VERSION ""

NS_ :

BS_:

BU_: EMS FR_CMR TCU vBDM AFS ILCU_LH ILCU_RH VCU BMS CLU EPB ESC H_U_MM IBU IBU_HS LDC MCU MDPS OBC RR_C_RDR SVM DATC ADAS_DRV ADAS_PRK AWD RWS AMP APSU DAU DVRS Dummy FCS HUD IAU ICSC ICU MLM PFSU PTGM SBW ACU ADM ECS TPMS HCU OPU PSB eCall AHLS ODS VESS AHV DHV DLBCU DPSS DPSU PSM RLHV RRHV SHVU_FR SHVU_RR DIBOX SAS FPCM SCM AFCU_DRV ESC_C CGW SCU WPC MFSW SWRC ESU AFCU_AST AFCU_RL AFCU_RR APSM ARS BCM BCW CCM DSS ECW FCU FICU GST HFKS HSWS LPI OPI PSD PSU RDC RLPSM RRPSM RWPC SLB SMK YRS SML CTM FR_C_RDR_LH FR_C_RDR_RH RR_C_RDR_LH CLU_MM HUD_MM LSD MKBD MM_CGW SBW_FF eCall_MM H_U_ETH FR_RDR

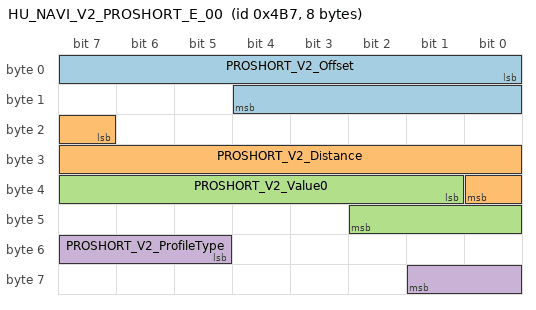
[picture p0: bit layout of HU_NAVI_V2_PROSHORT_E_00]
BO_ 1207 HU_NAVI_V2_PROSHORT_E_00: 8 H_U_ETH
 SG_ PROSHORT_V2_Offset : 0|13@1+ (1,0) [0|0] "m"  FR_CMR
 SG_ PROSHORT_V2_Distance : 23|10@1+ (1,0) [0|0] "m"  FR_CMR
 SG_ PROSHORT_V2_Value0 : 33|10@1+ (1,0) [0|0] ""  FR_CMR
 SG_ PROSHORT_V2_ProfileType : 53|5@1+ (1,0) [0|0] ""  FR_CMR

CM_ BO_ 1207 "[EC] Periodic and On Event";
CM_ SG_ 1207 PROSHORT_V2_Offset "Information for Offset of position of the first profile spot from currnet position
-This Offset should be calculated using below Factors(according to Profile Type)
-Profile Type 1(Curvature): 1m
-Profile Type 4(Slope): 1m(PROSHORT_Accuracy=0x0), 3m(PROSHORT_Accuracy=0x2)
-Profile Type 16(Safety Driving Section): 1m(Section0,1,2,3,5)
-Refer to Specification(ES96523-31) for details";
CM_ SG_ 1207 PROSHORT_V2_Distance "Information for Distance from first profile spot to the second one
-This distance should be calculated using below Factors(according to Profile Type)
-Profile Type 1(Curvature): 2
-Profile Type 4(Slope): 2(PROSHORT_Accuracy=0x0), 20(PROSHORT_Accuracy=0x2)
-Profile Type 16(Safety Driving Section): 20(Section0,1), 2(Section2,3), 5(Section5)";
CM_ SG_ 1207 PROSHORT_V2_Value0 "Information for Profile Short value at Offset";
CM_ SG_ 1207 PROSHORT_V2_ProfileType "Information for Profile Short Type: Slope(Linear) is used for Slope
-In case of Section Speed, transmitt Average Value of Speed Limit of Links in Section.
-Link without Speed Limit is excluded for Average Speed Calculation
-Unlimited Lane in Europe reflects 140kph for Average Speed Calculation";
BA_DEF_ BO_  "GenMsgILSupport" ENUM  "No","Yes";
BA_DEF_ BO_  "DiagState" ENUM  "No","Yes";
BA_DEF_ BO_  "DiagResponse" ENUM  "No","Yes";
BA_DEF_ BO_  "DiagRequest" ENUM  "No","Yes";
BA_DEF_ BO_  "VFrameFormat" ENUM  "StandardCAN","ExtendedCAN","reserved","reserved","reserved","reserved","reserved","reserved","reserved","reserved","reserved","reserved","reserved","reserved","StandardCAN_FD","ExtendedCAN_FD";
BA_DEF_ BO_  "GenMsgSendType" ENUM  "Cyclic","NoMsgSendType";
BA_DEF_ SG_  "UserSigValidity" ENUM  "B+","ACC","IG","IG1","IG2","IG3","IG1 or IG2","IG1 or IG3","Undef";
BA_DEF_ SG_  "RoutingFactor" INT 1 1215752192;
BA_DEF_ SG_  "NetworkRequestHoldingTime" INT 0 65535;
BA_DEF_ SG_  "Description" STRING ;
BA_DEF_ SG_  "Version" STRING ;
BA_DEF_ BO_  "GenMsgCycleTime" INT 0 2000;
BA_DEF_ BO_  "GenMsgStartDelayTime" INT 0 2000;
BA_DEF_ SG_  "UsrSigPurpose" ENUM  "Undef","FN","DIAG","DEV","NM";
BA_DEF_ SG_  "GenSigStartValue" INT 0 0;
BA_DEF_DEF_  "GenMsgILSupport" "Yes";
BA_DEF_DEF_  "DiagState" "No";
BA_DEF_DEF_  "DiagResponse" "No";
BA_DEF_DEF_  "DiagRequest" "No";
BA_DEF_DEF_  "VFrameFormat" "";
BA_DEF_DEF_  "GenMsgSendType" "NoMsgSendType";
BA_DEF_DEF_  "UserSigValidity" "IG";
BA_DEF_DEF_  "RoutingFactor" 1;
BA_DEF_DEF_  "NetworkRequestHoldingTime" 0;
BA_DEF_DEF_  "Description" "";
BA_DEF_DEF_  "Version" "";
BA_DEF_DEF_  "GenMsgCycleTime" 0;
BA_DEF_DEF_  "GenMsgStartDelayTime" 0;
BA_DEF_DEF_  "UsrSigPurpose" "FN";
BA_DEF_DEF_  "GenSigStartValue" 0;
BA_ "GenMsgSendType" BO_ 1207 0;
BA_ "VFrameFormat" BO_ 1207 14;
BA_ "UserSigValidity" SG_ 1207 PROSHORT_V2_Offset 3;
BA_ "GenSigStartValue" SG_ 1207 PROSHORT_V2_Offset 8191;
BA_ "Description" SG_ 1207 PROSHORT_V2_Offset "[Default Value]

0x1FFF";
BA_ "Version" SG_ 1207 PROSHORT_V2_Offset "18.01.07";
BA_ "UserSigValidity" SG_ 1207 PROSHORT_V2_Distance 3;
BA_ "GenSigStartValue" SG_ 1207 PROSHORT_V2_Distance 1023;
BA_ "Description" SG_ 1207 PROSHORT_V2_Distance "[Default Value]

0x3FF";
BA_ "Version" SG_ 1207 PROSHORT_V2_Distance "18.01.04";
BA_ "UserSigValidity" SG_ 1207 PROSHORT_V2_Value0 3;
BA_ "GenSigStartValue" SG_ 1207 PROSHORT_V2_Value0 1023;
BA_ "Description" SG_ 1207 PROSHORT_V2_Value0 "[Default Value]

0x3FF";
BA_ "Version" SG_ 1207 PROSHORT_V2_Value0 "18.01.04";
BA_ "UserSigValidity" SG_ 1207 PROSHORT_V2_ProfileType 3;
BA_ "Description" SG_ 1207 PROSHORT_V2_ProfileType "[Default Value]

0x0";
BA_ "Version" SG_ 1207 PROSHORT_V2_ProfileType "18.01.04";
VAL_ 1207 PROSHORT_V2_Offset 0 "Distance" 1 "Distance" 2 "Distance" 3 "Distance" 4 "Distance" 5 "Distance" 6 "Distance" 7 "Distance" 8 "Distance" 9 "Distance" 10 "Distance" 11 "Distance" 12 "Distance" 13 "Distance" 14 "Distance" 15 "Distance" 16 "Distance" 17 "Distance" 18 "Distance" 19 "Distance" 20 "Distance" 21 "Distance" 22 "Distance" 23 "Distance" 24 "Distance" 25 "Distance" 26 "Distance" 27 "Distance" 28 "Distance" 29 "Distance" 30 "Distance" 31 "Distance" 32 "Distance" 33 "Distance" 34 "Distance" 35 "Distance" 36 "Distance" 37 "Distance" 38 "Distance" 39 "Distance" 40 "Distance" 41 "Distance" 42 "Distance" 43 "Distance" 44 "Distance" 45 "Distance" 46 "Distance" 47 "Distance" 48 "Distance" 49 "Distance" 50 "Distance" 51 "Distance" 52 "Distance" 53 "Distance" 54 "Distance" 55 "Distance" 56 "Distance" 57 "Distance" 58 "Distance" 59 "Distance" 60 "Distance" 61 "Distance" 62 "Distance" 63 "Distance" 64 "Distance" 65 "Distance" 66 "Distance" 67 "Distance" 68 "Distance" 69 "Distance" 70 "Distance" 71 "Distance" 72 "Distance" 73 "Distance" 74 "Distance" 75 "Distance" 76 "Distance" 77 "Distance" 78 "Distance" 79 "Distance" 80 "Distance" 81 "Distance" 82 "Distance" 83 "Distance" 84 "Distance" 85 "Distance" 86 "Distance" 87 "Distance" 88 "Distance" 89 "Distance" 90 "Distance" 91 "Distance" 92 "Distance" 93 "Distance" 94 "Distance" 95 "Distance" 96 "Distance" 97 "Distance" 98 "Distance" 99 "Distance" 100 "Distance" 101 "Distance" 102 "Distance" 103 "Distance" 104 "Distance" 105 "Distance" 106 "Distance" 107 "Distance" 108 "Distance" 109 "Distance" 110 "Distance" 111 "Distance" 112 "Distance" 113 "Distance" 114 "Distance" 115 "Distance" 116 "Distance" 117 "Distance" 118 "Distance" 119 "Distance" 120 "Distance" 121 "Distance" 122 "Distance" 123 "Distance" 124 "Distance" 125 "Distance" 126 "Distance" 127 "Distance" 128 "Distance" 129 "Distance" 130 "Distance" 131 "Distance" 132 "Distance" 133 "Distance" 134 "Distance" 135 "Distance" 136 "Distance" 137 "Distance" 138 "Distance" 139 "Distance" 140 "Distance" 141 "Distance" 142 "Distance" 143 "Distance" 144 "Distance" 145 "Distance" 146 "Distance" 147 "Distance" 148 "Distance" 149 "Distance" 150 "Distance" 151 "Distance" 152 "Distance" 153 "Distance" 154 "Distance" 155 "Distance" 156 "Distance" 157 "Distance" 158 "Distance" 159 "Distance" 160 "Distance" 161 "Distance" 162 "Distance" 163 "Distance" 164 "Distance" 165 "Distance" 166 "Distance" 167 "Distance" 168 "Distance" 169 "Distance" 170 "Distance" 171 "Distance" 172 "Distance" 173 "Distance" 174 "Distance" 175 "Distance" 176 "Distance" 177 "Distance" 178 "Distance" 179 "Distance" 180 "Distance" 181 "Distance" 182 "Distance" 183 "Distance" 184 "Distance" 185 "Distance" 186 "Distance" 187 "Distance" 188 "Distance" 189 "Distance" 190 "Distance" 191 "Distance" 192 "Distance" 193 "Distance" 194 "Distance" 195 "Distance" 196 "Distance" 197 "Distance" 198 "Distance" 199 "Distance" 200 "Distance" 201 "Distance" 202 "Distance" 203 "Distance" 204 "Distance" 205 "Distance" 206 "Distance" 207 "Distance" 208 "Distance" 209 "Distance" 210 "Distance" 211 "Distance" 212 "Distance" 213 "Distance" 214 "Distance" 215 "Distance" 216 "Distance" 217 "Distance" 218 "Distance" 219 "Distance" 220 "Distance" 221 "Distance" 222 "Distance" 223 "Distance" 224 "Distance" 225 "Distance" 226 "Distance" 227 "Distance" 228 "Distance" 229 "Distance" 230 "Distance" 231 "Distance" 232 "Distance" 233 "Distance" 234 "Distance" 235 "Distance" 236 "Distance" 237 "Distance" 238 "Distance" 239 "Distance" 240 "Distance" 241 "Distance" 242 "Distance" 243 "Distance" 244 "Distance" 245 "Distance" 246 "Distance" 247 "Distance" 248 "Distance" 249 "Distance" 250 "Distance" 251 "Distance" 252 "Distance" 253 "Distance" 254 "Distance" 255 "Distance" 256 "Distance" 257 "Distance" 258 "Distance" 259 "Distance" 260 "Distance" 261 "Distance" 262 "Distance" 263 "Distance" 264 "Distance" 265 "Distance" 266 "Distance" 267 "Distance" 268 "Distance" 269 "Distance" 270 "Distance" 271 "Distance" 272 "Distance" 273 "Distance" 274 "Distance" 275 "Distance" 276 "Distance" 277 "Distance" 278 "Distance" 279 "Distance" 280 "Distance" 281 "Distance" 282 "Distance" 283 "Distance" 284 "Distance" 285 "Distance" 286 "Distance" 287 "Distance" 288 "Distance" 289 "Distance" 290 "Distance" 291 "Distance" 292 "Distance" 293 "Distance" 294 "Distance" 295 "Distance" 296 "Distance" 297 "Distance" 298 "Distance" 299 "Distance" 300 "Distance" 301 "Distance" 302 "Distance" 303 "Distance" 304 "Distance" 305 "Distance" 306 "Distance" 307 "Distance" 308 "Distance" 309 "Distance" 310 "Distance" 311 "Distance" 312 "Distance" 313 "Distance" 314 "Distance" 315 "Distance" 316 "Distance" 317 "Distance" 318 "Distance" 319 "Distance" 320 "Distance" 321 "Distance" 322 "Distance" 323 "Distance" 324 "Distance" 325 "Distance" 326 "Distance" 327 "Distance" 328 "Distance" 329 "Distance" 330 "Distance" 331 "Distance" 332 "Distance" 333 "Distance" 334 "Distance" 335 "Distance" 336 "Distance" 337 "Distance" 338 "Distance" 339 "Distance" 340 "Distance" 341 "Distance" 342 "Distance" 343 "Distance" 344 "Distance" 345 "Distance" 346 "Distance" 347 "Distance" 348 "Distance" 349 "Distance" 350 "Distance" 351 "Distance" 352 "Distance" 353 "Distance" 354 "Distance" 355 "Distance" 356 "Distance" 357 "Distance" 358 "Distance" 359 "Distance" 360 "Distance" 361 "Distance" 362 "Distance" 363 "Distance" 364 "Distance" 365 "Distance" 366 "Distance" 367 "Distance" 368 "Distance" 369 "Distance" 370 "Distance" 371 "Distance" 372 "Distance" 373 "Distance" 374 "Distance" 375 "Distance" 376 "Distance" 377 "Distance" 378 "Distance" 379 "Distance" 380 "Distance" 381 "Distance" 382 "Distance" 383 "Distance" 384 "Distance" 385 "Distance" 386 "Distance" 387 "Distance" 388 "Distance" 389 "Distance" 390 "Distance" 391 "Distance" 392 "Distance" 393 "Distance" 394 "Distance" 395 "Distance" 396 "Distance" 397 "Distance" 398 "Distance" 399 "Distance" 400 "Distance" 401 "Distance" 402 "Distance" 403 "Distance" 404 "Distance" 405 "Distance" 406 "Distance" 407 "Distance" 408 "Distance" 409 "Distance" 410 "Distance" 411 "Distance" 412 "Distance" 413 "Distance" 414 "Distance" 415 "Distance" 416 "Distance" 417 "Distance" 418 "Distance" 419 "Distance" 420 "Distance" 421 "Distance" 422 "Distance" 423 "Distance" 424 "Distance" 425 "Distance" 426 "Distance" 427 "Distance" 428 "Distance" 429 "Distance" 430 "Distance" 431 "Distance" 432 "Distance" 433 "Distance" 434 "Distance" 435 "Distance" 436 "Distance" 437 "Distance" 438 "Distance" 439 "Distance" 440 "Distance" 441 "Distance" 442 "Distance" 443 "Distance" 444 "Distance" 445 "Distance" 446 "Distance" 447 "Distance" 448 "Distance" 449 "Distance" 450 "Distance" 451 "Distance" 452 "Distance" 453 "Distance" 454 "Distance" 455 "Distance" 456 "Distance" 457 "Distance" 458 "Distance" 459 "Distance" 460 "Distance" 461 "Distance" 462 "Distance" 463 "Distance" 464 "Distance" 465 "Distance" 466 "Distance" 467 "Distance" 468 "Distance" 469 "Distance" 470 "Distance" 471 "Distance" 472 "Distance" 473 "Distance" 474 "Distance" 475 "Distance" 476 "Distance" 477 "Distance" 478 "Distance" 479 "Distance" 480 "Distance" 481 "Distance" 482 "Distance" 483 "Distance" 484 "Distance" 485 "Distance" 486 "Distance" 487 "Distance" 488 "Distance" 489 "Distance" 490 "Distance" 491 "Distance" 492 "Distance" 493 "Distance" 494 "Distance" 495 "Distance" 496 "Distance" 497 "Distance" 498 "Distance" 499 "Distance" 500 "Distance" 501 "Distance" 502 "Distance" 503 "Distance" 504 "Distance" 505 "Distance" 506 "Distance" 507 "Distance" 508 "Distance" 509 "Distance" 510 "Distance" 511 "Distance" 512 "Distance" 513 "Distance" 514 "Distance" 515 "Distance" 516 "Distance" 517 "Distance" 518 "Distance" 519 "Distance" 520 "Distance" 521 "Distance" 522 "Distance" 523 "Distance" 524 "Distance" 525 "Distance" 526 "Distance" 527 "Distance" 528 "Distance" 529 "Distance" 530 "Distance" 531 "Distance" 532 "Distance" 533 "Distance" 534 "Distance" 535 "Distance" 536 "Distance" 537 "Distance" 538 "Distance" 539 "Distance" 540 "Distance" 541 "Distance" 542 "Distance" 543 "Distance" 544 "Distance" 545 "Distance" 546 "Distance" 547 "Distance" 548 "Distance" 549 "Distance" 550 "Distance" 551 "Distance" 552 "Distance" 553 "Distance" 554 "Distance" 555 "Distance" 556 "Distance" 557 "Distance" 558 "Distance" 559 "Distance" 560 "Distance" 561 "Distance" 562 "Distance" 563 "Distance" 564 "Distance" 565 "Distance" 566 "Distance" 567 "Distance" 568 "Distance" 569 "Distance" 570 "Distance" 571 "Distance" 572 "Distance" 573 "Distance" 574 "Distance" 575 "Distance" 576 "Distance" 577 "Distance" 578 "Distance" 579 "Distance" 580 "Distance" 581 "Distance" 582 "Distance" 583 "Distance" 584 "Distance" 585 "Distance" 586 "Distance" 587 "Distance" 588 "Distance" 589 "Distance" 590 "Distance" 591 "Distance" 592 "Distance" 593 "Distance" 594 "Distance" 595 "Distance" 596 "Distance" 597 "Distance" 598 "Distance" 599 "Distance" 600 "Distance" 601 "Distance" 602 "Distance" 603 "Distance" 604 "Distance" 605 "Distance" 606 "Distance" 607 "Distance" 608 "Distance" 609 "Distance" 610 "Distance" 611 "Distance" 612 "Distance" 613 "Distance" 614 "Distance" 615 "Distance" 616 "Distance" 617 "Distance" 618 "Distance" 619 "Distance" 620 "Distance" 621 "Distance" 622 "Distance" 623 "Distance" 624 "Distance" 625 "Distance" 626 "Distance" 627 "Distance" 628 "Distance" 629 "Distance" 630 "Distance" 631 "Distance" 632 "Distance" 633 "Distance" 634 "Distance" 635 "Distance" 636 "Distance" 637 "Distance" 638 "Distance" 639 "Distance" 640 "Distance" 641 "Distance" 642 "Distance" 643 "Distance" 644 "Distance" 645 "Distance" 646 "Distance" 647 "Distance" 648 "Distance" 649 "Distance" 650 "Distance" 651 "Distance" 652 "Distance" 653 "Distance" 654 "Distance" 655 "Distance" 656 "Distance" 657 "Distance" 658 "Distance" 659 "Distance" 660 "Distance" 661 "Distance" 662 "Distance" 663 "Distance" 664 "Distance" 665 "Distance" 666 "Distance" 667 "Distance" 668 "Distance" 669 "Distance" 670 "Distance" 671 "Distance" 672 "Distance" 673 "Distance" 674 "Distance" 675 "Distance" 676 "Distance" 677 "Distance" 678 "Distance" 679 "Distance" 680 "Distance" 681 "Distance" 682 "Distance" 683 "Distance" 684 "Distance" 685 "Distance" 686 "Distance" 687 "Distance" 688 "Distance" 689 "Distance" 690 "Distance" 691 "Distance" 692 "Distance" 693 "Distance" 694 "Distance" 695 "Distance" 696 "Distance" 697 "Distance" 698 "Distance" 699 "Distance" 700 "Distance" 701 "Distance" 702 "Distance" 703 "Distance" 704 "Distance" 705 "Distance" 706 "Distance" 707 "Distance" 708 "Distance" 709 "Distance" 710 "Distance" 711 "Distance" 712 "Distance" 713 "Distance" 714 "Distance" 715 "Distance" 716 "Distance" 717 "Distance" 718 "Distance" 719 "Distance" 720 "Distance" 721 "Distance" 722 "Distance" 723 "Distance" 724 "Distance" 725 "Distance" 726 "Distance" 727 "Distance" 728 "Distance" 729 "Distance" 730 "Distance" 731 "Distance" 732 "Distance" 733 "Distance" 734 "Distance" 735 "Distance" 736 "Distance" 737 "Distance" 738 "Distance" 739 "Distance" 740 "Distance" 741 "Distance" 742 "Distance" 743 "Distance" 744 "Distance" 745 "Distance" 746 "Distance" 747 "Distance" 748 "Distance" 749 "Distance" 750 "Distance" 751 "Distance" 752 "Distance" 753 "Distance" 754 "Distance" 755 "Distance" 756 "Distance" 757 "Distance" 758 "Distance" 759 "Distance" 760 "Distance" 761 "Distance" 762 "Distance" 763 "Distance" 764 "Distance" 765 "Distance" 766 "Distance" 767 "Distance" 768 "Distance" 769 "Distance" 770 "Distance" 771 "Distance" 772 "Distance" 773 "Distance" 774 "Distance" 775 "Distance" 776 "Distance" 777 "Distance" 778 "Distance" 779 "Distance" 780 "Distance" 781 "Distance" 782 "Distance" 783 "Distance" 784 "Distance" 785 "Distance" 786 "Distance" 787 "Distance" 788 "Distance" 789 "Distance" 790 "Distance" 791 "Distance" 792 "Distance" 793 "Distance" 794 "Distance" 795 "Distance" 796 "Distance" 797 "Distance" 798 "Distance" 799 "Distance" 800 "Distance" 801 "Distance" 802 "Distance" 803 "Distance" 804 "Distance" 805 "Distance" 806 "Distance" 807 "Distance" 808 "Distance" 809 "Distance" 810 "Distance" 811 "Distance" 812 "Distance" 813 "Distance" 814 "Distance" 815 "Distance" 816 "Distance" 817 "Distance" 818 "Distance" 819 "Distance" 820 "Distance" 821 "Distance" 822 "Distance" 823 "Distance" 824 "Distance" 825 "Distance" 826 "Distance" 827 "Distance" 828 "Distance" 829 "Distance" 830 "Distance" 831 "Distance" 832 "Distance" 833 "Distance" 834 "Distance" 835 "Distance" 836 "Distance" 837 "Distance" 838 "Distance" 839 "Distance" 840 "Distance" 841 "Distance" 842 "Distance" 843 "Distance" 844 "Distance" 845 "Distance" 846 "Distance" 847 "Distance" 848 "Distance" 849 "Distance" 850 "Distance" 851 "Distance" 852 "Distance" 853 "Distance" 854 "Distance" 855 "Distance" 856 "Distance" 857 "Distance" 858 "Distance" 859 "Distance" 860 "Distance" 861 "Distance" 862 "Distance" 863 "Distance" 864 "Distance" 865 "Distance" 866 "Distance" 867 "Distance" 868 "Distance" 869 "Distance" 870 "Distance" 871 "Distance" 872 "Distance" 873 "Distance" 874 "Distance" 875 "Distance" 876 "Distance" 877 "Distance" 878 "Distance" 879 "Distance" 880 "Distance" 881 "Distance" 882 "Distance" 883 "Distance" 884 "Distance" 885 "Distance" 886 "Distance" 887 "Distance" 888 "Distance" 889 "Distance" 890 "Distance" 891 "Distance" 892 "Distance" 893 "Distance" 894 "Distance" 895 "Distance" 896 "Distance" 897 "Distance" 898 "Distance" 899 "Distance" 900 "Distance" 901 "Distance" 902 "Distance" 903 "Distance" 904 "Distance" 905 "Distance" 906 "Distance" 907 "Distance" 908 "Distance" 909 "Distance" 910 "Distance" 911 "Distance" 912 "Distance" 913 "Distance" 914 "Distance" 915 "Distance" 916 "Distance" 917 "Distance" 918 "Distance" 919 "Distance" 920 "Distance" 921 "Distance" 922 "Distance" 923 "Distance" 924 "Distance" 925 "Distance" 926 "Distance" 927 "Distance" 928 "Distance" 929 "Distance" 930 "Distance" 931 "Distance" 932 "Distance" 933 "Distance" 934 "Distance" 935 "Distance" 936 "Distance" 937 "Distance" 938 "Distance" 939 "Distance" 940 "Distance" 941 "Distance" 942 "Distance" 943 "Distance" 944 "Distance" 945 "Distance" 946 "Distance" 947 "Distance" 948 "Distance" 949 "Distance" 950 "Distance" 951 "Distance" 952 "Distance" 953 "Distance" 954 "Distance" 955 "Distance" 956 "Distance" 957 "Distance" 958 "Distance" 959 "Distance" 960 "Distance" 961 "Distance" 962 "Distance" 963 "Distance" 964 "Distance" 965 "Distance" 966 "Distance" 967 "Distance" 968 "Distance" 969 "Distance" 970 "Distance" 971 "Distance" 972 "Distance" 973 "Distance" 974 "Distance" 975 "Distance" 976 "Distance" 977 "Distance" 978 "Distance" 979 "Distance" 980 "Distance" 981 "Distance" 982 "Distance" 983 "Distance" 984 "Distance" 985 "Distance" 986 "Distance" 987 "Distance" 988 "Distance" 989 "Distance" 990 "Distance" 991 "Distance" 992 "Distance" 993 "Distance" 994 "Distance" 995 "Distance" 996 "Distance" 997 "Distance" 998 "Distance" 999 "Distance" 1000 "Distance" 1001 "Distance" 1002 "Distance" 1003 "Distance" 1004 "Distance" 1005 "Distance" 1006 "Distance" 1007 "Distance" 1008 "Distance" 1009 "Distance" 1010 "Distance" 1011 "Distance" 1012 "Distance" 1013 "Distance" 1014 "Distance" 1015 "Distance" 1016 "Distance" 1017 "Distance" 1018 "Distance" 1019 "Distance" 1020 "Distance" 1021 "Distance" 1022 "Distance" 1023 "Distance" 1024 "Distance" 1025 "Distance" 1026 "Distance" 1027 "Distance" 1028 "Distance" 1029 "Distance" 1030 "Distance" 1031 "Distance" 1032 "Distance" 1033 "Distance" 1034 "Distance" 1035 "Distance" 1036 "Distance" 1037 "Distance" 1038 "Distance" 1039 "Distance" 1040 "Distance" 1041 "Distance" 1042 "Distance" 1043 "Distance" 1044 "Distance" 1045 "Distance" 1046 "Distance" 1047 "Distance" 1048 "Distance" 1049 "Distance" 1050 "Distance" 1051 "Distance" 1052 "Distance" 1053 "Distance" 1054 "Distance" 1055 "Distance" 1056 "Distance" 1057 "Distance" 1058 "Distance" 1059 "Distance" 1060 "Distance" 1061 "Distance" 1062 "Distance" 1063 "Distance" 1064 "Distance" 1065 "Distance" 1066 "Distance" 1067 "Distance" 1068 "Distance" 1069 "Distance" 1070 "Distance" 1071 "Distance" 1072 "Distance" 1073 "Distance" 1074 "Distance" 1075 "Distance" 1076 "Distance" 1077 "Distance" 1078 "Distance" 1079 "Distance" 1080 "Distance" 1081 "Distance" 1082 "Distance" 1083 "Distance" 1084 "Distance" 1085 "Distance" 1086 "Distance" 1087 "Distance" 1088 "Distance" 1089 "Distance" 1090 "Distance" 1091 "Distance" 1092 "Distance" 1093 "Distance" 1094 "Distance" 1095 "Distance" 1096 "Distance" 1097 "Distance" 1098 "Distance" 1099 "Distance" 1100 "Distance" 1101 "Distance" 1102 "Distance" 1103 "Distance" 1104 "Distance" 1105 "Distance" 1106 "Distance" 1107 "Distance" 1108 "Distance" 1109 "Distance" 1110 "Distance" 1111 "Distance" 1112 "Distance" 1113 "Distance" 1114 "Distance" 1115 "Distance" 1116 "Distance" 1117 "Distance" 1118 "Distance" 1119 "Distance" 1120 "Distance" 1121 "Distance" 1122 "Distance" 1123 "Distance" 1124 "Distance" 1125 "Distance" 1126 "Distance" 1127 "Distance" 1128 "Distance" 1129 "Distance" 1130 "Distance" 1131 "Distance" 1132 "Distance" 1133 "Distance" 1134 "Distance" 1135 "Distance" 1136 "Distance" 1137 "Distance" 1138 "Distance" 1139 "Distance" 1140 "Distance" 1141 "Distance" 1142 "Distance" 1143 "Distance" 1144 "Distance" 1145 "Distance" 1146 "Distance" 1147 "Distance" 1148 "Distance" 1149 "Distance" 1150 "Distance" 1151 "Distance" 1152 "Distance" 1153 "Distance" 1154 "Distance" 1155 "Distance" 1156 "Distance" 1157 "Distance" 1158 "Distance" 1159 "Distance" 1160 "Distance" 1161 "Distance" 1162 "Distance" 1163 "Distance" 1164 "Distance" 1165 "Distance" 1166 "Distance" 1167 "Distance" 1168 "Distance" 1169 "Distance" 1170 "Distance" 1171 "Distance" 1172 "Distance" 1173 "Distance" 1174 "Distance" 1175 "Distance" 1176 "Distance" 1177 "Distance" 1178 "Distance" 1179 "Distance" 1180 "Distance" 1181 "Distance" 1182 "Distance" 1183 "Distance" 1184 "Distance" 1185 "Distance" 1186 "Distance" 1187 "Distance" 1188 "Distance" 1189 "Distance" 1190 "Distance" 1191 "Distance" 1192 "Distance" 1193 "Distance" 1194 "Distance" 1195 "Distance" 1196 "Distance" 1197 "Distance" 1198 "Distance" 1199 "Distance" 1200 "Distance" 1201 "Distance" 1202 "Distance" 1203 "Distance" 1204 "Distance" 1205 "Distance" 1206 "Distance" 1207 "Distance" 1208 "Distance" 1209 "Distance" 1210 "Distance" 1211 "Distance" 1212 "Distance" 1213 "Distance" 1214 "Distance" 1215 "Distance" 1216 "Distance" 1217 "Distance" 1218 "Distance" 1219 "Distance" 1220 "Distance" 1221 "Distance" 1222 "Distance" 1223 "Distance" 1224 "Distance" 1225 "Distance" 1226 "Distance" 1227 "Distance" 1228 "Distance" 1229 "Distance" 1230 "Distance" 1231 "Distance" 1232 "Distance" 1233 "Distance" 1234 "Distance" 1235 "Distance" 1236 "Distance" 1237 "Distance" 1238 "Distance" 1239 "Distance" 1240 "Distance" 1241 "Distance" 1242 "Distance" 1243 "Distance" 1244 "Distance" 1245 "Distance" 1246 "Distance" 1247 "Distance" 1248 "Distance" 1249 "Distance" 1250 "Distance" 1251 "Distance" 1252 "Distance" 1253 "Distance" 1254 "Distance" 1255 "Distance" 1256 "Distance" 1257 "Distance" 1258 "Distance" 1259 "Distance" 1260 "Distance" 1261 "Distance" 1262 "Distance" 1263 "Distance" 1264 "Distance" 1265 "Distance" 1266 "Distance" 1267 "Distance" 1268 "Distance" 1269 "Distance" 1270 "Distance" 1271 "Distance" 1272 "Distance" 1273 "Distance" 1274 "Distance" 1275 "Distance" 1276 "Distance" 1277 "Distance" 1278 "Distance" 1279 "Distance" 1280 "Distance" 1281 "Distance" 1282 "Distance" 1283 "Distance" 1284 "Distance" 1285 "Distance" 1286 "Distance" 1287 "Distance" 1288 "Distance" 1289 "Distance" 1290 "Distance" 1291 "Distance" 1292 "Distance" 1293 "Distance" 1294 "Distance" 1295 "Distance" 1296 "Distance" 1297 "Distance" 1298 "Distance" 1299 "Distance" 1300 "Distance" 1301 "Distance" 1302 "Distance" 1303 "Distance" 1304 "Distance" 1305 "Distance" 1306 "Distance" 1307 "Distance" 1308 "Distance" 1309 "Distance" 1310 "Distance" 1311 "Distance" 1312 "Distance" 1313 "Distance" 1314 "Distance" 1315 "Distance" 1316 "Distance" 1317 "Distance" 1318 "Distance" 1319 "Distance" 1320 "Distance" 1321 "Distance" 1322 "Distance" 1323 "Distance" 1324 "Distance" 1325 "Distance" 1326 "Distance" 1327 "Distance" 1328 "Distance" 1329 "Distance" 1330 "Distance" 1331 "Distance" 1332 "Distance" 1333 "Distance" 1334 "Distance" 1335 "Distance" 1336 "Distance" 1337 "Distance" 1338 "Distance" 1339 "Distance" 1340 "Distance" 1341 "Distance" 1342 "Distance" 1343 "Distance" 1344 "Distance" 1345 "Distance" 1346 "Distance" 1347 "Distance" 1348 "Distance" 1349 "Distance" 1350 "Distance" 1351 "Distance" 1352 "Distance" 1353 "Distance" 1354 "Distance" 1355 "Distance" 1356 "Distance" 1357 "Distance" 1358 "Distance" 1359 "Distance" 1360 "Distance" 1361 "Distance" 1362 "Distance" 1363 "Distance" 1364 "Distance" 1365 "Distance" 1366 "Distance" 1367 "Distance" 1368 "Distance" 1369 "Distance" 1370 "Distance" 1371 "Distance" 1372 "Distance" 1373 "Distance" 1374 "Distance" 1375 "Distance" 1376 "Distance" 1377 "Distance" 1378 "Distance" 1379 "Distance" 1380 "Distance" 1381 "Distance" 1382 "Distance" 1383 "Distance" 1384 "Distance" 1385 "Distance" 1386 "Distance" 1387 "Distance" 1388 "Distance" 1389 "Distance" 1390 "Distance" 1391 "Distance" 1392 "Distance" 1393 "Distance" 1394 "Distance" 1395 "Distance" 1396 "Distance" 1397 "Distance" 1398 "Distance" 1399 "Distance" 1400 "Distance" 1401 "Distance" 1402 "Distance" 1403 "Distance" 1404 "Distance" 1405 "Distance" 1406 "Distance" 1407 "Distance" 1408 "Distance" 1409 "Distance" 1410 "Distance" 1411 "Distance" 1412 "Distance" 1413 "Distance" 1414 "Distance" 1415 "Distance" 1416 "Distance" 1417 "Distance" 1418 "Distance" 1419 "Distance" 1420 "Distance" 1421 "Distance" 1422 "Distance" 1423 "Distance" 1424 "Distance" 1425 "Distance" 1426 "Distance" 1427 "Distance" 1428 "Distance" 1429 "Distance" 1430 "Distance" 1431 "Distance" 1432 "Distance" 1433 "Distance" 1434 "Distance" 1435 "Distance" 1436 "Distance" 1437 "Distance" 1438 "Distance" 1439 "Distance" 1440 "Distance" 1441 "Distance" 1442 "Distance" 1443 "Distance" 1444 "Distance" 1445 "Distance" 1446 "Distance" 1447 "Distance" 1448 "Distance" 1449 "Distance" 1450 "Distance" 1451 "Distance" 1452 "Distance" 1453 "Distance" 1454 "Distance" 1455 "Distance" 1456 "Distance" 1457 "Distance" 1458 "Distance" 1459 "Distance" 1460 "Distance" 1461 "Distance" 1462 "Distance" 1463 "Distance" 1464 "Distance" 1465 "Distance" 1466 "Distance" 1467 "Distance" 1468 "Distance" 1469 "Distance" 1470 "Distance" 1471 "Distance" 1472 "Distance" 1473 "Distance" 1474 "Distance" 1475 "Distance" 1476 "Distance" 1477 "Distance" 1478 "Distance" 1479 "Distance" 1480 "Distance" 1481 "Distance" 1482 "Distance" 1483 "Distance" 1484 "Distance" 1485 "Distance" 1486 "Distance" 1487 "Distance" 1488 "Distance" 1489 "Distance" 1490 "Distance" 1491 "Distance" 1492 "Distance" 1493 "Distance" 1494 "Distance" 1495 "Distance" 1496 "Distance" 1497 "Distance" 1498 "Distance" 1499 "Distance" 1500 "Distance" 1501 "Distance" 1502 "Distance" 1503 "Distance" 1504 "Distance" 1505 "Distance" 1506 "Distance" 1507 "Distance" 1508 "Distance" 1509 "Distance" 1510 "Distance" 1511 "Distance" 1512 "Distance" 1513 "Distance" 1514 "Distance" 1515 "Distance" 1516 "Distance" 1517 "Distance" 1518 "Distance" 1519 "Distance" 1520 "Distance" 1521 "Distance" 1522 "Distance" 1523 "Distance" 1524 "Distance" 1525 "Distance" 1526 "Distance" 1527 "Distance" 1528 "Distance" 1529 "Distance" 1530 "Distance" 1531 "Distance" 1532 "Distance" 1533 "Distance" 1534 "Distance" 1535 "Distance" 1536 "Distance" 1537 "Distance" 1538 "Distance" 1539 "Distance" 1540 "Distance" 1541 "Distance" 1542 "Distance" 1543 "Distance" 1544 "Distance" 1545 "Distance" 1546 "Distance" 1547 "Distance" 1548 "Distance" 1549 "Distance" 1550 "Distance" 1551 "Distance" 1552 "Distance" 1553 "Distance" 1554 "Distance" 1555 "Distance" 1556 "Distance" 1557 "Distance" 1558 "Distance" 1559 "Distance" 1560 "Distance" 1561 "Distance" 1562 "Distance" 1563 "Distance" 1564 "Distance" 1565 "Distance" 1566 "Distance" 1567 "Distance" 1568 "Distance" 1569 "Distance" 1570 "Distance" 1571 "Distance" 1572 "Distance" 1573 "Distance" 1574 "Distance" 1575 "Distance" 1576 "Distance" 1577 "Distance" 1578 "Distance" 1579 "Distance" 1580 "Distance" 1581 "Distance" 1582 "Distance" 1583 "Distance" 1584 "Distance" 1585 "Distance" 1586 "Distance" 1587 "Distance" 1588 "Distance" 1589 "Distance" 1590 "Distance" 1591 "Distance" 1592 "Distance" 1593 "Distance" 1594 "Distance" 1595 "Distance" 1596 "Distance" 1597 "Distance" 1598 "Distance" 1599 "Distance" 1600 "Distance" 1601 "Distance" 1602 "Distance" 1603 "Distance" 1604 "Distance" 1605 "Distance" 1606 "Distance" 1607 "Distance" 1608 "Distance" 1609 "Distance" 1610 "Distance" 1611 "Distance" 1612 "Distance" 1613 "Distance" 1614 "Distance" 1615 "Distance" 1616 "Distance" 1617 "Distance" 1618 "Distance" 1619 "Distance" 1620 "Distance" 1621 "Distance" 1622 "Distance" 1623 "Distance" 1624 "Distance" 1625 "Distance" 1626 "Distance" 1627 "Distance" 1628 "Distance" 1629 "Distance" 1630 "Distance" 1631 "Distance" 1632 "Distance" 1633 "Distance" 1634 "Distance" 1635 "Distance" 1636 "Distance" 1637 "Distance" 1638 "Distance" 1639 "Distance" 1640 "Distance" 1641 "Distance" 1642 "Distance" 1643 "Distance" 1644 "Distance" 1645 "Distance" 1646 "Distance" 1647 "Distance" 1648 "Distance" 1649 "Distance" 1650 "Distance" 1651 "Distance" 1652 "Distance" 1653 "Distance" 1654 "Distance" 1655 "Distance" 1656 "Distance" 1657 "Distance" 1658 "Distance" 1659 "Distance" 1660 "Distance" 1661 "Distance" 1662 "Distance" 1663 "Distance" 1664 "Distance" 1665 "Distance" 1666 "Distance" 1667 "Distance" 1668 "Distance" 1669 "Distance" 1670 "Distance" 1671 "Distance" 1672 "Distance" 1673 "Distance" 1674 "Distance" 1675 "Distance" 1676 "Distance" 1677 "Distance" 1678 "Distance" 1679 "Distance" 1680 "Distance" 1681 "Distance" 1682 "Distance" 1683 "Distance" 1684 "Distance" 1685 "Distance" 1686 "Distance" 1687 "Distance" 1688 "Distance" 1689 "Distance" 1690 "Distance" 1691 "Distance" 1692 "Distance" 1693 "Distance" 1694 "Distance" 1695 "Distance" 1696 "Distance" 1697 "Distance" 1698 "Distance" 1699 "Distance" 1700 "Distance" 1701 "Distance" 1702 "Distance" 1703 "Distance" 1704 "Distance" 1705 "Distance" 1706 "Distance" 1707 "Distance" 1708 "Distance" 1709 "Distance" 1710 "Distance" 1711 "Distance" 1712 "Distance" 1713 "Distance" 1714 "Distance" 1715 "Distance" 1716 "Distance" 1717 "Distance" 1718 "Distance" 1719 "Distance" 1720 "Distance" 1721 "Distance" 1722 "Distance" 1723 "Distance" 1724 "Distance" 1725 "Distance" 1726 "Distance" 1727 "Distance" 1728 "Distance" 1729 "Distance" 1730 "Distance" 1731 "Distance" 1732 "Distance" 1733 "Distance" 1734 "Distance" 1735 "Distance" 1736 "Distance" 1737 "Distance" 1738 "Distance" 1739 "Distance" 1740 "Distance" 1741 "Distance" 1742 "Distance" 1743 "Distance" 1744 "Distance" 1745 "Distance" 1746 "Distance" 1747 "Distance" 1748 "Distance" 1749 "Distance" 1750 "Distance" 1751 "Distance" 1752 "Distance" 1753 "Distance" 1754 "Distance" 1755 "Distance" 1756 "Distance" 1757 "Distance" 1758 "Distance" 1759 "Distance" 1760 "Distance" 1761 "Distance" 1762 "Distance" 1763 "Distance" 1764 "Distance" 1765 "Distance" 1766 "Distance" 1767 "Distance" 1768 "Distance" 1769 "Distance" 1770 "Distance" 1771 "Distance" 1772 "Distance" 1773 "Distance" 1774 "Distance" 1775 "Distance" 1776 "Distance" 1777 "Distance" 1778 "Distance" 1779 "Distance" 1780 "Distance" 1781 "Distance" 1782 "Distance" 1783 "Distance" 1784 "Distance" 1785 "Distance" 1786 "Distance" 1787 "Distance" 1788 "Distance" 1789 "Distance" 1790 "Distance" 1791 "Distance" 1792 "Distance" 1793 "Distance" 1794 "Distance" 1795 "Distance" 1796 "Distance" 1797 "Distance" 1798 "Distance" 1799 "Distance" 1800 "Distance" 1801 "Distance" 1802 "Distance" 1803 "Distance" 1804 "Distance" 1805 "Distance" 1806 "Distance" 1807 "Distance" 1808 "Distance" 1809 "Distance" 1810 "Distance" 1811 "Distance" 1812 "Distance" 1813 "Distance" 1814 "Distance" 1815 "Distance" 1816 "Distance" 1817 "Distance" 1818 "Distance" 1819 "Distance" 1820 "Distance" 1821 "Distance" 1822 "Distance" 1823 "Distance" 1824 "Distance" 1825 "Distance" 1826 "Distance" 1827 "Distance" 1828 "Distance" 1829 "Distance" 1830 "Distance" 1831 "Distance" 1832 "Distance" 1833 "Distance" 1834 "Distance" 1835 "Distance" 1836 "Distance" 1837 "Distance" 1838 "Distance" 1839 "Distance" 1840 "Distance" 1841 "Distance" 1842 "Distance" 1843 "Distance" 1844 "Distance" 1845 "Distance" 1846 "Distance" 1847 "Distance" 1848 "Distance" 1849 "Distance" 1850 "Distance" 1851 "Distance" 1852 "Distance" 1853 "Distance" 1854 "Distance" 1855 "Distance" 1856 "Distance" 1857 "Distance" 1858 "Distance" 1859 "Distance" 1860 "Distance" 1861 "Distance" 1862 "Distance" 1863 "Distance" 1864 "Distance" 1865 "Distance" 1866 "Distance" 1867 "Distance" 1868 "Distance" 1869 "Distance" 1870 "Distance" 1871 "Distance" 1872 "Distance" 1873 "Distance" 1874 "Distance" 1875 "Distance" 1876 "Distance" 1877 "Distance" 1878 "Distance" 1879 "Distance" 1880 "Distance" 1881 "Distance" 1882 "Distance" 1883 "Distance" 1884 "Distance" 1885 "Distance" 1886 "Distance" 1887 "Distance" 1888 "Distance" 1889 "Distance" 1890 "Distance" 1891 "Distance" 1892 "Distance" 1893 "Distance" 1894 "Distance" 1895 "Distance" 1896 "Distance" 1897 "Distance" 1898 "Distance" 1899 "Distance" 1900 "Distance" 1901 "Distance" 1902 "Distance" 1903 "Distance" 1904 "Distance" 1905 "Distance" 1906 "Distance" 1907 "Distance" 1908 "Distance" 1909 "Distance" 1910 "Distance" 1911 "Distance" 1912 "Distance" 1913 "Distance" 1914 "Distance" 1915 "Distance" 1916 "Distance" 1917 "Distance" 1918 "Distance" 1919 "Distance" 1920 "Distance" 1921 "Distance" 1922 "Distance" 1923 "Distance" 1924 "Distance" 1925 "Distance" 1926 "Distance" 1927 "Distance" 1928 "Distance" 1929 "Distance" 1930 "Distance" 1931 "Distance" 1932 "Distance" 1933 "Distance" 1934 "Distance" 1935 "Distance" 1936 "Distance" 1937 "Distance" 1938 "Distance" 1939 "Distance" 1940 "Distance" 1941 "Distance" 1942 "Distance" 1943 "Distance" 1944 "Distance" 1945 "Distance" 1946 "Distance" 1947 "Distance" 1948 "Distance" 1949 "Distance" 1950 "Distance" 1951 "Distance" 1952 "Distance" 1953 "Distance" 1954 "Distance" 1955 "Distance" 1956 "Distance" 1957 "Distance" 1958 "Distance" 1959 "Distance" 1960 "Distance" 1961 "Distance" 1962 "Distance" 1963 "Distance" 1964 "Distance" 1965 "Distance" 1966 "Distance" 1967 "Distance" 1968 "Distance" 1969 "Distance" 1970 "Distance" 1971 "Distance" 1972 "Distance" 1973 "Distance" 1974 "Distance" 1975 "Distance" 1976 "Distance" 1977 "Distance" 1978 "Distance" 1979 "Distance" 1980 "Distance" 1981 "Distance" 1982 "Distance" 1983 "Distance" 1984 "Distance" 1985 "Distance" 1986 "Distance" 1987 "Distance" 1988 "Distance" 1989 "Distance" 1990 "Distance" 1991 "Distance" 1992 "Distance" 1993 "Distance" 1994 "Distance" 1995 "Distance" 1996 "Distance" 1997 "Distance" 1998 "Distance" 1999 "Distance" 2000 "Distance" 2001 "Distance" 2002 "Distance" 2003 "Distance" 2004 "Distance" 2005 "Distance" 2006 "Distance" 2007 "Distance" 2008 "Distance" 2009 "Distance" 2010 "Distance" 2011 "Distance" 2012 "Distance" 2013 "Distance" 2014 "Distance" 2015 "Distance" 2016 "Distance" 2017 "Distance" 2018 "Distance" 2019 "Distance" 2020 "Distance" 2021 "Distance" 2022 "Distance" 2023 "Distance" 2024 "Distance" 2025 "Distance" 2026 "Distance" 2027 "Distance" 2028 "Distance" 2029 "Distance" 2030 "Distance" 2031 "Distance" 2032 "Distance" 2033 "Distance" 2034 "Distance" 2035 "Distance" 2036 "Distance" 2037 "Distance" 2038 "Distance" 2039 "Distance" 2040 "Distance" 2041 "Distance" 2042 "Distance" 2043 "Distance" 2044 "Distance" 2045 "Distance" 2046 "Distance" 2047 "Distance" 2048 "Distance" 2049 "Distance" 2050 "Distance" 2051 "Distance" 2052 "Distance" 2053 "Distance" 2054 "Distance" 2055 "Distance" 2056 "Distance" 2057 "Distance" 2058 "Distance" 2059 "Distance" 2060 "Distance" 2061 "Distance" 2062 "Distance" 2063 "Distance" 2064 "Distance" 2065 "Distance" 2066 "Distance" 2067 "Distance" 2068 "Distance" 2069 "Distance" 2070 "Distance" 2071 "Distance" 2072 "Distance" 2073 "Distance" 2074 "Distance" 2075 "Distance" 2076 "Distance" 2077 "Distance" 2078 "Distance" 2079 "Distance" 2080 "Distance" 2081 "Distance" 2082 "Distance" 2083 "Distance" 2084 "Distance" 2085 "Distance" 2086 "Distance" 2087 "Distance" 2088 "Distance" 2089 "Distance" 2090 "Distance" 2091 "Distance" 2092 "Distance" 2093 "Distance" 2094 "Distance" 2095 "Distance" 2096 "Distance" 2097 "Distance" 2098 "Distance" 2099 "Distance" 2100 "Distance" 2101 "Distance" 2102 "Distance" 2103 "Distance" 2104 "Distance" 2105 "Distance" 2106 "Distance" 2107 "Distance" 2108 "Distance" 2109 "Distance" 2110 "Distance" 2111 "Distance" 2112 "Distance" 2113 "Distance" 2114 "Distance" 2115 "Distance" 2116 "Distance" 2117 "Distance" 2118 "Distance" 2119 "Distance" 2120 "Distance" 2121 "Distance" 2122 "Distance" 2123 "Distance" 2124 "Distance" 2125 "Distance" 2126 "Distance" 2127 "Distance" 2128 "Distance" 2129 "Distance" 2130 "Distance" 2131 "Distance" 2132 "Distance" 2133 "Distance" 2134 "Distance" 2135 "Distance" 2136 "Distance" 2137 "Distance" 2138 "Distance" 2139 "Distance" 2140 "Distance" 2141 "Distance" 2142 "Distance" 2143 "Distance" 2144 "Distance" 2145 "Distance" 2146 "Distance" 2147 "Distance" 2148 "Distance" 2149 "Distance" 2150 "Distance" 2151 "Distance" 2152 "Distance" 2153 "Distance" 2154 "Distance" 2155 "Distance" 2156 "Distance" 2157 "Distance" 2158 "Distance" 2159 "Distance" 2160 "Distance" 2161 "Distance" 2162 "Distance" 2163 "Distance" 2164 "Distance" 2165 "Distance" 2166 "Distance" 2167 "Distance" 2168 "Distance" 2169 "Distance" 2170 "Distance" 2171 "Distance" 2172 "Distance" 2173 "Distance" 2174 "Distance" 2175 "Distance" 2176 "Distance" 2177 "Distance" 2178 "Distance" 2179 "Distance" 2180 "Distance" 2181 "Distance" 2182 "Distance" 2183 "Distance" 2184 "Distance" 2185 "Distance" 2186 "Distance" 2187 "Distance" 2188 "Distance" 2189 "Distance" 2190 "Distance" 2191 "Distance" 2192 "Distance" 2193 "Distance" 2194 "Distance" 2195 "Distance" 2196 "Distance" 2197 "Distance" 2198 "Distance" 2199 "Distance" 2200 "Distance" 2201 "Distance" 2202 "Distance" 2203 "Distance" 2204 "Distance" 2205 "Distance" 2206 "Distance" 2207 "Distance" 2208 "Distance" 2209 "Distance" 2210 "Distance" 2211 "Distance" 2212 "Distance" 2213 "Distance" 2214 "Distance" 2215 "Distance" 2216 "Distance" 2217 "Distance" 2218 "Distance" 2219 "Distance" 2220 "Distance" 2221 "Distance" 2222 "Distance" 2223 "Distance" 2224 "Distance" 2225 "Distance" 2226 "Distance" 2227 "Distance" 2228 "Distance" 2229 "Distance" 2230 "Distance" 2231 "Distance" 2232 "Distance" 2233 "Distance" 2234 "Distance" 2235 "Distance" 2236 "Distance" 2237 "Distance" 2238 "Distance" 2239 "Distance" 2240 "Distance" 2241 "Distance" 2242 "Distance" 2243 "Distance" 2244 "Distance" 2245 "Distance" 2246 "Distance" 2247 "Distance" 2248 "Distance" 2249 "Distance" 2250 "Distance" 2251 "Distance" 2252 "Distance" 2253 "Distance" 2254 "Distance" 2255 "Distance" 2256 "Distance" 2257 "Distance" 2258 "Distance" 2259 "Distance" 2260 "Distance" 2261 "Distance" 2262 "Distance" 2263 "Distance" 2264 "Distance" 2265 "Distance" 2266 "Distance" 2267 "Distance" 2268 "Distance" 2269 "Distance" 2270 "Distance" 2271 "Distance" 2272 "Distance" 2273 "Distance" 2274 "Distance" 2275 "Distance" 2276 "Distance" 2277 "Distance" 2278 "Distance" 2279 "Distance" 2280 "Distance" 2281 "Distance" 2282 "Distance" 2283 "Distance" 2284 "Distance" 2285 "Distance" 2286 "Distance" 2287 "Distance" 2288 "Distance" 2289 "Distance" 2290 "Distance" 2291 "Distance" 2292 "Distance" 2293 "Distance" 2294 "Distance" 2295 "Distance" 2296 "Distance" 2297 "Distance" 2298 "Distance" 2299 "Distance" 2300 "Distance" 2301 "Distance" 2302 "Distance" 2303 "Distance" 2304 "Distance" 2305 "Distance" 2306 "Distance" 2307 "Distance" 2308 "Distance" 2309 "Distance" 2310 "Distance" 2311 "Distance" 2312 "Distance" 2313 "Distance" 2314 "Distance" 2315 "Distance" 2316 "Distance" 2317 "Distance" 2318 "Distance" 2319 "Distance" 2320 "Distance" 2321 "Distance" 2322 "Distance" 2323 "Distance" 2324 "Distance" 2325 "Distance" 2326 "Distance" 2327 "Distance" 2328 "Distance" 2329 "Distance" 2330 "Distance" 2331 "Distance" 2332 "Distance" 2333 "Distance" 2334 "Distance" 2335 "Distance" 2336 "Distance" 2337 "Distance" 2338 "Distance" 2339 "Distance" 2340 "Distance" 2341 "Distance" 2342 "Distance" 2343 "Distance" 2344 "Distance" 2345 "Distance" 2346 "Distance" 2347 "Distance" 2348 "Distance" 2349 "Distance" 2350 "Distance" 2351 "Distance" 2352 "Distance" 2353 "Distance" 2354 "Distance" 2355 "Distance" 2356 "Distance" 2357 "Distance" 2358 "Distance" 2359 "Distance" 2360 "Distance" 2361 "Distance" 2362 "Distance" 2363 "Distance" 2364 "Distance" 2365 "Distance" 2366 "Distance" 2367 "Distance" 2368 "Distance" 2369 "Distance" 2370 "Distance" 2371 "Distance" 2372 "Distance" 2373 "Distance" 2374 "Distance" 2375 "Distance" 2376 "Distance" 2377 "Distance" 2378 "Distance" 2379 "Distance" 2380 "Distance" 2381 "Distance" 2382 "Distance" 2383 "Distance" 2384 "Distance" 2385 "Distance" 2386 "Distance" 2387 "Distance" 2388 "Distance" 2389 "Distance" 2390 "Distance" 2391 "Distance" 2392 "Distance" 2393 "Distance" 2394 "Distance" 2395 "Distance" 2396 "Distance" 2397 "Distance" 2398 "Distance" 2399 "Distance" 2400 "Distance" 2401 "Distance" 2402 "Distance" 2403 "Distance" 2404 "Distance" 2405 "Distance" 2406 "Distance" 2407 "Distance" 2408 "Distance" 2409 "Distance" 2410 "Distance" 2411 "Distance" 2412 "Distance" 2413 "Distance" 2414 "Distance" 2415 "Distance" 2416 "Distance" 2417 "Distance" 2418 "Distance" 2419 "Distance" 2420 "Distance" 2421 "Distance" 2422 "Distance" 2423 "Distance" 2424 "Distance" 2425 "Distance" 2426 "Distance" 2427 "Distance" 2428 "Distance" 2429 "Distance" 2430 "Distance" 2431 "Distance" 2432 "Distance" 2433 "Distance" 2434 "Distance" 2435 "Distance" 2436 "Distance" 2437 "Distance" 2438 "Distance" 2439 "Distance" 2440 "Distance" 2441 "Distance" 2442 "Distance" 2443 "Distance" 2444 "Distance" 2445 "Distance" 2446 "Distance" 2447 "Distance" 2448 "Distance" 2449 "Distance" 2450 "Distance" 2451 "Distance" 2452 "Distance" 2453 "Distance" 2454 "Distance" 2455 "Distance" 2456 "Distance" 2457 "Distance" 2458 "Distance" 2459 "Distance" 2460 "Distance" 2461 "Distance" 2462 "Distance" 2463 "Distance" 2464 "Distance" 2465 "Distance" 2466 "Distance" 2467 "Distance" 2468 "Distance" 2469 "Distance" 2470 "Distance" 2471 "Distance" 2472 "Distance" 2473 "Distance" 2474 "Distance" 2475 "Distance" 2476 "Distance" 2477 "Distance" 2478 "Distance" 2479 "Distance" 2480 "Distance" 2481 "Distance" 2482 "Distance" 2483 "Distance" 2484 "Distance" 2485 "Distance" 2486 "Distance" 2487 "Distance" 2488 "Distance" 2489 "Distance" 2490 "Distance" 2491 "Distance" 2492 "Distance" 2493 "Distance" 2494 "Distance" 2495 "Distance" 2496 "Distance" 2497 "Distance" 2498 "Distance" 2499 "Distance" 2500 "Distance" 2501 "Distance" 2502 "Distance" 2503 "Distance" 2504 "Distance" 2505 "Distance" 2506 "Distance" 2507 "Distance" 2508 "Distance" 2509 "Distance" 2510 "Distance" 2511 "Distance" 2512 "Distance" 2513 "Distance" 2514 "Distance" 2515 "Distance" 2516 "Distance" 2517 "Distance" 2518 "Distance" 2519 "Distance" 2520 "Distance" 2521 "Distance" 2522 "Distance" 2523 "Distance" 2524 "Distance" 2525 "Distance" 2526 "Distance" 2527 "Distance" 2528 "Distance" 2529 "Distance" 2530 "Distance" 2531 "Distance" 2532 "Distance" 2533 "Distance" 2534 "Distance" 2535 "Distance" 2536 "Distance" 2537 "Distance" 2538 "Distance" 2539 "Distance" 2540 "Distance" 2541 "Distance" 2542 "Distance" 2543 "Distance" 2544 "Distance" 2545 "Distance" 2546 "Distance" 2547 "Distance" 2548 "Distance" 2549 "Distance" 2550 "Distance" 2551 "Distance" 2552 "Distance" 2553 "Distance" 2554 "Distance" 2555 "Distance" 2556 "Distance" 2557 "Distance" 2558 "Distance" 2559 "Distance" 2560 "Distance" 2561 "Distance" 2562 "Distance" 2563 "Distance" 2564 "Distance" 2565 "Distance" 2566 "Distance" 2567 "Distance" 2568 "Distance" 2569 "Distance" 2570 "Distance" 2571 "Distance" 2572 "Distance" 2573 "Distance" 2574 "Distance" 2575 "Distance" 2576 "Distance" 2577 "Distance" 2578 "Distance" 2579 "Distance" 2580 "Distance" 2581 "Distance" 2582 "Distance" 2583 "Distance" 2584 "Distance" 2585 "Distance" 2586 "Distance" 2587 "Distance" 2588 "Distance" 2589 "Distance" 2590 "Distance" 2591 "Distance" 2592 "Distance" 2593 "Distance" 2594 "Distance" 2595 "Distance" 2596 "Distance" 2597 "Distance" 2598 "Distance" 2599 "Distance" 2600 "Distance" 2601 "Distance" 2602 "Distance" 2603 "Distance" 2604 "Distance" 2605 "Distance" 2606 "Distance" 2607 "Distance" 2608 "Distance" 2609 "Distance" 2610 "Distance" 2611 "Distance" 2612 "Distance" 2613 "Distance" 2614 "Distance" 2615 "Distance" 2616 "Distance" 2617 "Distance" 2618 "Distance" 2619 "Distance" 2620 "Distance" 2621 "Distance" 2622 "Distance" 2623 "Distance" 2624 "Distance" 2625 "Distance" 2626 "Distance" 2627 "Distance" 2628 "Distance" 2629 "Distance" 2630 "Distance" 2631 "Distance" 2632 "Distance" 2633 "Distance" 2634 "Distance" 2635 "Distance" 2636 "Distance" 2637 "Distance" 2638 "Distance" 2639 "Distance" 2640 "Distance" 2641 "Distance" 2642 "Distance" 2643 "Distance" 2644 "Distance" 2645 "Distance" 2646 "Distance" 2647 "Distance" 2648 "Distance" 2649 "Distance" 2650 "Distance" 2651 "Distance" 2652 "Distance" 2653 "Distance" 2654 "Distance" 2655 "Distance" 2656 "Distance" 2657 "Distance" 2658 "Distance" 2659 "Distance" 2660 "Distance" 2661 "Distance" 2662 "Distance" 2663 "Distance" 2664 "Distance" 2665 "Distance" 2666 "Distance" 2667 "Distance" 2668 "Distance" 2669 "Distance" 2670 "Distance" 2671 "Distance" 2672 "Distance" 2673 "Distance" 2674 "Distance" 2675 "Distance" 2676 "Distance" 2677 "Distance" 2678 "Distance" 2679 "Distance" 2680 "Distance" 2681 "Distance" 2682 "Distance" 2683 "Distance" 2684 "Distance" 2685 "Distance" 2686 "Distance" 2687 "Distance" 2688 "Distance" 2689 "Distance" 2690 "Distance" 2691 "Distance" 2692 "Distance" 2693 "Distance" 2694 "Distance" 2695 "Distance" 2696 "Distance" 2697 "Distance" 2698 "Distance" 2699 "Distance" 2700 "Distance" 2701 "Distance" 2702 "Distance" 2703 "Distance" 2704 "Distance" 2705 "Distance" 2706 "Distance" 2707 "Distance" 2708 "Distance" 2709 "Distance" 2710 "Distance" 2711 "Distance" 2712 "Distance" 2713 "Distance" 2714 "Distance" 2715 "Distance" 2716 "Distance" 2717 "Distance" 2718 "Distance" 2719 "Distance" 2720 "Distance" 2721 "Distance" 2722 "Distance" 2723 "Distance" 2724 "Distance" 2725 "Distance" 2726 "Distance" 2727 "Distance" 2728 "Distance" 2729 "Distance" 2730 "Distance" 2731 "Distance" 2732 "Distance" 2733 "Distance" 2734 "Distance" 2735 "Distance" 2736 "Distance" 2737 "Distance" 2738 "Distance" 2739 "Distance" 2740 "Distance" 2741 "Distance" 2742 "Distance" 2743 "Distance" 2744 "Distance" 2745 "Distance" 2746 "Distance" 2747 "Distance" 2748 "Distance" 2749 "Distance" 2750 "Distance" 2751 "Distance" 2752 "Distance" 2753 "Distance" 2754 "Distance" 2755 "Distance" 2756 "Distance" 2757 "Distance" 2758 "Distance" 2759 "Distance" 2760 "Distance" 2761 "Distance" 2762 "Distance" 2763 "Distance" 2764 "Distance" 2765 "Distance" 2766 "Distance" 2767 "Distance" 2768 "Distance" 2769 "Distance" 2770 "Distance" 2771 "Distance" 2772 "Distance" 2773 "Distance" 2774 "Distance" 2775 "Distance" 2776 "Distance" 2777 "Distance" 2778 "Distance" 2779 "Distance" 2780 "Distance" 2781 "Distance" 2782 "Distance" 2783 "Distance" 2784 "Distance" 2785 "Distance" 2786 "Distance" 2787 "Distance" 2788 "Distance" 2789 "Distance" 2790 "Distance" 2791 "Distance" 2792 "Distance" 2793 "Distance" 2794 "Distance" 2795 "Distance" 2796 "Distance" 2797 "Distance" 2798 "Distance" 2799 "Distance" 2800 "Distance" 2801 "Distance" 2802 "Distance" 2803 "Distance" 2804 "Distance" 2805 "Distance" 2806 "Distance" 2807 "Distance" 2808 "Distance" 2809 "Distance" 2810 "Distance" 2811 "Distance" 2812 "Distance" 2813 "Distance" 2814 "Distance" 2815 "Distance" 2816 "Distance" 2817 "Distance" 2818 "Distance" 2819 "Distance" 2820 "Distance" 2821 "Distance" 2822 "Distance" 2823 "Distance" 2824 "Distance" 2825 "Distance" 2826 "Distance" 2827 "Distance" 2828 "Distance" 2829 "Distance" 2830 "Distance" 2831 "Distance" 2832 "Distance" 2833 "Distance" 2834 "Distance" 2835 "Distance" 2836 "Distance" 2837 "Distance" 2838 "Distance" 2839 "Distance" 2840 "Distance" 2841 "Distance" 2842 "Distance" 2843 "Distance" 2844 "Distance" 2845 "Distance" 2846 "Distance" 2847 "Distance" 2848 "Distance" 2849 "Distance" 2850 "Distance" 2851 "Distance" 2852 "Distance" 2853 "Distance" 2854 "Distance" 2855 "Distance" 2856 "Distance" 2857 "Distance" 2858 "Distance" 2859 "Distance" 2860 "Distance" 2861 "Distance" 2862 "Distance" 2863 "Distance" 2864 "Distance" 2865 "Distance" 2866 "Distance" 2867 "Distance" 2868 "Distance" 2869 "Distance" 2870 "Distance" 2871 "Distance" 2872 "Distance" 2873 "Distance" 2874 "Distance" 2875 "Distance" 2876 "Distance" 2877 "Distance" 2878 "Distance" 2879 "Distance" 2880 "Distance" 2881 "Distance" 2882 "Distance" 2883 "Distance" 2884 "Distance" 2885 "Distance" 2886 "Distance" 2887 "Distance" 2888 "Distance" 2889 "Distance" 2890 "Distance" 2891 "Distance" 2892 "Distance" 2893 "Distance" 2894 "Distance" 2895 "Distance" 2896 "Distance" 2897 "Distance" 2898 "Distance" 2899 "Distance" 2900 "Distance" 2901 "Distance" 2902 "Distance" 2903 "Distance" 2904 "Distance" 2905 "Distance" 2906 "Distance" 2907 "Distance" 2908 "Distance" 2909 "Distance" 2910 "Distance" 2911 "Distance" 2912 "Distance" 2913 "Distance" 2914 "Distance" 2915 "Distance" 2916 "Distance" 2917 "Distance" 2918 "Distance" 2919 "Distance" 2920 "Distance" 2921 "Distance" 2922 "Distance" 2923 "Distance" 2924 "Distance" 2925 "Distance" 2926 "Distance" 2927 "Distance" 2928 "Distance" 2929 "Distance" 2930 "Distance" 2931 "Distance" 2932 "Distance" 2933 "Distance" 2934 "Distance" 2935 "Distance" 2936 "Distance" 2937 "Distance" 2938 "Distance" 2939 "Distance" 2940 "Distance" 2941 "Distance" 2942 "Distance" 2943 "Distance" 2944 "Distance" 2945 "Distance" 2946 "Distance" 2947 "Distance" 2948 "Distance" 2949 "Distance" 2950 "Distance" 2951 "Distance" 2952 "Distance" 2953 "Distance" 2954 "Distance" 2955 "Distance" 2956 "Distance" 2957 "Distance" 2958 "Distance" 2959 "Distance" 2960 "Distance" 2961 "Distance" 2962 "Distance" 2963 "Distance" 2964 "Distance" 2965 "Distance" 2966 "Distance" 2967 "Distance" 2968 "Distance" 2969 "Distance" 2970 "Distance" 2971 "Distance" 2972 "Distance" 2973 "Distance" 2974 "Distance" 2975 "Distance" 2976 "Distance" 2977 "Distance" 2978 "Distance" 2979 "Distance" 2980 "Distance" 2981 "Distance" 2982 "Distance" 2983 "Distance" 2984 "Distance" 2985 "Distance" 2986 "Distance" 2987 "Distance" 2988 "Distance" 2989 "Distance" 2990 "Distance" 2991 "Distance" 2992 "Distance" 2993 "Distance" 2994 "Distance" 2995 "Distance" 2996 "Distance" 2997 "Distance" 2998 "Distance" 2999 "Distance" 3000 "Distance" 3001 "Distance" 3002 "Distance" 3003 "Distance" 3004 "Distance" 3005 "Distance" 3006 "Distance" 3007 "Distance" 3008 "Distance" 3009 "Distance" 3010 "Distance" 3011 "Distance" 3012 "Distance" 3013 "Distance" 3014 "Distance" 3015 "Distance" 3016 "Distance" 3017 "Distance" 3018 "Distance" 3019 "Distance" 3020 "Distance" 3021 "Distance" 3022 "Distance" 3023 "Distance" 3024 "Distance" 3025 "Distance" 3026 "Distance" 3027 "Distance" 3028 "Distance" 3029 "Distance" 3030 "Distance" 3031 "Distance" 3032 "Distance" 3033 "Distance" 3034 "Distance" 3035 "Distance" 3036 "Distance" 3037 "Distance" 3038 "Distance" 3039 "Distance" 3040 "Distance" 3041 "Distance" 3042 "Distance" 3043 "Distance" 3044 "Distance" 3045 "Distance" 3046 "Distance" 3047 "Distance" 3048 "Distance" 3049 "Distance" 3050 "Distance" 3051 "Distance" 3052 "Distance" 3053 "Distance" 3054 "Distance" 3055 "Distance" 3056 "Distance" 3057 "Distance" 3058 "Distance" 3059 "Distance" 3060 "Distance" 3061 "Distance" 3062 "Distance" 3063 "Distance" 3064 "Distance" 3065 "Distance" 3066 "Distance" 3067 "Distance" 3068 "Distance" 3069 "Distance" 3070 "Distance" 3071 "Distance" 3072 "Distance" 3073 "Distance" 3074 "Distance" 3075 "Distance" 3076 "Distance" 3077 "Distance" 3078 "Distance" 3079 "Distance" 3080 "Distance" 3081 "Distance" 3082 "Distance" 3083 "Distance" 3084 "Distance" 3085 "Distance" 3086 "Distance" 3087 "Distance" 3088 "Distance" 3089 "Distance" 3090 "Distance" 3091 "Distance" 3092 "Distance" 3093 "Distance" 3094 "Distance" 3095 "Distance" 3096 "Distance" 3097 "Distance" 3098 "Distance" 3099 "Distance" 3100 "Distance" 3101 "Distance" 3102 "Distance" 3103 "Distance" 3104 "Distance" 3105 "Distance" 3106 "Distance" 3107 "Distance" 3108 "Distance" 3109 "Distance" 3110 "Distance" 3111 "Distance" 3112 "Distance" 3113 "Distance" 3114 "Distance" 3115 "Distance" 3116 "Distance" 3117 "Distance" 3118 "Distance" 3119 "Distance" 3120 "Distance" 3121 "Distance" 3122 "Distance" 3123 "Distance" 3124 "Distance" 3125 "Distance" 3126 "Distance" 3127 "Distance" 3128 "Distance" 3129 "Distance" 3130 "Distance" 3131 "Distance" 3132 "Distance" 3133 "Distance" 3134 "Distance" 3135 "Distance" 3136 "Distance" 3137 "Distance" 3138 "Distance" 3139 "Distance" 3140 "Distance" 3141 "Distance" 3142 "Distance" 3143 "Distance" 3144 "Distance" 3145 "Distance" 3146 "Distance" 3147 "Distance" 3148 "Distance" 3149 "Distance" 3150 "Distance" 3151 "Distance" 3152 "Distance" 3153 "Distance" 3154 "Distance" 3155 "Distance" 3156 "Distance" 3157 "Distance" 3158 "Distance" 3159 "Distance" 3160 "Distance" 3161 "Distance" 3162 "Distance" 3163 "Distance" 3164 "Distance" 3165 "Distance" 3166 "Distance" 3167 "Distance" 3168 "Distance" 3169 "Distance" 3170 "Distance" 3171 "Distance" 3172 "Distance" 3173 "Distance" 3174 "Distance" 3175 "Distance" 3176 "Distance" 3177 "Distance" 3178 "Distance" 3179 "Distance" 3180 "Distance" 3181 "Distance" 3182 "Distance" 3183 "Distance" 3184 "Distance" 3185 "Distance" 3186 "Distance" 3187 "Distance" 3188 "Distance" 3189 "Distance" 3190 "Distance" 3191 "Distance" 3192 "Distance" 3193 "Distance" 3194 "Distance" 3195 "Distance" 3196 "Distance" 3197 "Distance" 3198 "Distance" 3199 "Distance" 3200 "Distance" 3201 "Distance" 3202 "Distance" 3203 "Distance" 3204 "Distance" 3205 "Distance" 3206 "Distance" 3207 "Distance" 3208 "Distance" 3209 "Distance" 3210 "Distance" 3211 "Distance" 3212 "Distance" 3213 "Distance" 3214 "Distance" 3215 "Distance" 3216 "Distance" 3217 "Distance" 3218 "Distance" 3219 "Distance" 3220 "Distance" 3221 "Distance" 3222 "Distance" 3223 "Distance" 3224 "Distance" 3225 "Distance" 3226 "Distance" 3227 "Distance" 3228 "Distance" 3229 "Distance" 3230 "Distance" 3231 "Distance" 3232 "Distance" 3233 "Distance" 3234 "Distance" 3235 "Distance" 3236 "Distance" 3237 "Distance" 3238 "Distance" 3239 "Distance" 3240 "Distance" 3241 "Distance" 3242 "Distance" 3243 "Distance" 3244 "Distance" 3245 "Distance" 3246 "Distance" 3247 "Distance" 3248 "Distance" 3249 "Distance" 3250 "Distance" 3251 "Distance" 3252 "Distance" 3253 "Distance" 3254 "Distance" 3255 "Distance" 3256 "Distance" 3257 "Distance" 3258 "Distance" 3259 "Distance" 3260 "Distance" 3261 "Distance" 3262 "Distance" 3263 "Distance" 3264 "Distance" 3265 "Distance" 3266 "Distance" 3267 "Distance" 3268 "Distance" 3269 "Distance" 3270 "Distance" 3271 "Distance" 3272 "Distance" 3273 "Distance" 3274 "Distance" 3275 "Distance" 3276 "Distance" 3277 "Distance" 3278 "Distance" 3279 "Distance" 3280 "Distance" 3281 "Distance" 3282 "Distance" 3283 "Distance" 3284 "Distance" 3285 "Distance" 3286 "Distance" 3287 "Distance" 3288 "Distance" 3289 "Distance" 3290 "Distance" 3291 "Distance" 3292 "Distance" 3293 "Distance" 3294 "Distance" 3295 "Distance" 3296 "Distance" 3297 "Distance" 3298 "Distance" 3299 "Distance" 3300 "Distance" 3301 "Distance" 3302 "Distance" 3303 "Distance" 3304 "Distance" 3305 "Distance" 3306 "Distance" 3307 "Distance" 3308 "Distance" 3309 "Distance" 3310 "Distance" 3311 "Distance" 3312 "Distance" 3313 "Distance" 3314 "Distance" 3315 "Distance" 3316 "Distance" 3317 "Distance" 3318 "Distance" 3319 "Distance" 3320 "Distance" 3321 "Distance" 3322 "Distance" 3323 "Distance" 3324 "Distance" 3325 "Distance" 3326 "Distance" 3327 "Distance" 3328 "Distance" 3329 "Distance" 3330 "Distance" 3331 "Distance" 3332 "Distance" 3333 "Distance" 3334 "Distance" 3335 "Distance" 3336 "Distance" 3337 "Distance" 3338 "Distance" 3339 "Distance" 3340 "Distance" 3341 "Distance" 3342 "Distance" 3343 "Distance" 3344 "Distance" 3345 "Distance" 3346 "Distance" 3347 "Distance" 3348 "Distance" 3349 "Distance" 3350 "Distance" 3351 "Distance" 3352 "Distance" 3353 "Distance" 3354 "Distance" 3355 "Distance" 3356 "Distance" 3357 "Distance" 3358 "Distance" 3359 "Distance" 3360 "Distance" 3361 "Distance" 3362 "Distance" 3363 "Distance" 3364 "Distance" 3365 "Distance" 3366 "Distance" 3367 "Distance" 3368 "Distance" 3369 "Distance" 3370 "Distance" 3371 "Distance" 3372 "Distance" 3373 "Distance" 3374 "Distance" 3375 "Distance" 3376 "Distance" 3377 "Distance" 3378 "Distance" 3379 "Distance" 3380 "Distance" 3381 "Distance" 3382 "Distance" 3383 "Distance" 3384 "Distance" 3385 "Distance" 3386 "Distance" 3387 "Distance" 3388 "Distance" 3389 "Distance" 3390 "Distance" 3391 "Distance" 3392 "Distance" 3393 "Distance" 3394 "Distance" 3395 "Distance" 3396 "Distance" 3397 "Distance" 3398 "Distance" 3399 "Distance" 3400 "Distance" 3401 "Distance" 3402 "Distance" 3403 "Distance" 3404 "Distance" 3405 "Distance" 3406 "Distance" 3407 "Distance" 3408 "Distance" 3409 "Distance" 3410 "Distance" 3411 "Distance" 3412 "Distance" 3413 "Distance" 3414 "Distance" 3415 "Distance" 3416 "Distance" 3417 "Distance" 3418 "Distance" 3419 "Distance" 3420 "Distance" 3421 "Distance" 3422 "Distance" 3423 "Distance" 3424 "Distance" 3425 "Distance" 3426 "Distance" 3427 "Distance" 3428 "Distance" 3429 "Distance" 3430 "Distance" 3431 "Distance" 3432 "Distance" 3433 "Distance" 3434 "Distance" 3435 "Distance" 3436 "Distance" 3437 "Distance" 3438 "Distance" 3439 "Distance" 3440 "Distance" 3441 "Distance" 3442 "Distance" 3443 "Distance" 3444 "Distance" 3445 "Distance" 3446 "Distance" 3447 "Distance" 3448 "Distance" 3449 "Distance" 3450 "Distance" 3451 "Distance" 3452 "Distance" 3453 "Distance" 3454 "Distance" 3455 "Distance" 3456 "Distance" 3457 "Distance" 3458 "Distance" 3459 "Distance" 3460 "Distance" 3461 "Distance" 3462 "Distance" 3463 "Distance" 3464 "Distance" 3465 "Distance" 3466 "Distance" 3467 "Distance" 3468 "Distance" 3469 "Distance" 3470 "Distance" 3471 "Distance" 3472 "Distance" 3473 "Distance" 3474 "Distance" 3475 "Distance" 3476 "Distance" 3477 "Distance" 3478 "Distance" 3479 "Distance" 3480 "Distance" 3481 "Distance" 3482 "Distance" 3483 "Distance" 3484 "Distance" 3485 "Distance" 3486 "Distance" 3487 "Distance" 3488 "Distance" 3489 "Distance" 3490 "Distance" 3491 "Distance" 3492 "Distance" 3493 "Distance" 3494 "Distance" 3495 "Distance" 3496 "Distance" 3497 "Distance" 3498 "Distance" 3499 "Distance" 3500 "Distance" 3501 "Distance" 3502 "Distance" 3503 "Distance" 3504 "Distance" 3505 "Distance" 3506 "Distance" 3507 "Distance" 3508 "Distance" 3509 "Distance" 3510 "Distance" 3511 "Distance" 3512 "Distance" 3513 "Distance" 3514 "Distance" 3515 "Distance" 3516 "Distance" 3517 "Distance" 3518 "Distance" 3519 "Distance" 3520 "Distance" 3521 "Distance" 3522 "Distance" 3523 "Distance" 3524 "Distance" 3525 "Distance" 3526 "Distance" 3527 "Distance" 3528 "Distance" 3529 "Distance" 3530 "Distance" 3531 "Distance" 3532 "Distance" 3533 "Distance" 3534 "Distance" 3535 "Distance" 3536 "Distance" 3537 "Distance" 3538 "Distance" 3539 "Distance" 3540 "Distance" 3541 "Distance" 3542 "Distance" 3543 "Distance" 3544 "Distance" 3545 "Distance" 3546 "Distance" 3547 "Distance" 3548 "Distance" 3549 "Distance" 3550 "Distance" 3551 "Distance" 3552 "Distance" 3553 "Distance" 3554 "Distance" 3555 "Distance" 3556 "Distance" 3557 "Distance" 3558 "Distance" 3559 "Distance" 3560 "Distance" 3561 "Distance" 3562 "Distance" 3563 "Distance" 3564 "Distance" 3565 "Distance" 3566 "Distance" 3567 "Distance" 3568 "Distance" 3569 "Distance" 3570 "Distance" 3571 "Distance" 3572 "Distance" 3573 "Distance" 3574 "Distance" 3575 "Distance" 3576 "Distance" 3577 "Distance" 3578 "Distance" 3579 "Distance" 3580 "Distance" 3581 "Distance" 3582 "Distance" 3583 "Distance" 3584 "Distance" 3585 "Distance" 3586 "Distance" 3587 "Distance" 3588 "Distance" 3589 "Distance" 3590 "Distance" 3591 "Distance" 3592 "Distance" 3593 "Distance" 3594 "Distance" 3595 "Distance" 3596 "Distance" 3597 "Distance" 3598 "Distance" 3599 "Distance" 3600 "Distance" 3601 "Distance" 3602 "Distance" 3603 "Distance" 3604 "Distance" 3605 "Distance" 3606 "Distance" 3607 "Distance" 3608 "Distance" 3609 "Distance" 3610 "Distance" 3611 "Distance" 3612 "Distance" 3613 "Distance" 3614 "Distance" 3615 "Distance" 3616 "Distance" 3617 "Distance" 3618 "Distance" 3619 "Distance" 3620 "Distance" 3621 "Distance" 3622 "Distance" 3623 "Distance" 3624 "Distance" 3625 "Distance" 3626 "Distance" 3627 "Distance" 3628 "Distance" 3629 "Distance" 3630 "Distance" 3631 "Distance" 3632 "Distance" 3633 "Distance" 3634 "Distance" 3635 "Distance" 3636 "Distance" 3637 "Distance" 3638 "Distance" 3639 "Distance" 3640 "Distance" 3641 "Distance" 3642 "Distance" 3643 "Distance" 3644 "Distance" 3645 "Distance" 3646 "Distance" 3647 "Distance" 3648 "Distance" 3649 "Distance" 3650 "Distance" 3651 "Distance" 3652 "Distance" 3653 "Distance" 3654 "Distance" 3655 "Distance" 3656 "Distance" 3657 "Distance" 3658 "Distance" 3659 "Distance" 3660 "Distance" 3661 "Distance" 3662 "Distance" 3663 "Distance" 3664 "Distance" 3665 "Distance" 3666 "Distance" 3667 "Distance" 3668 "Distance" 3669 "Distance" 3670 "Distance" 3671 "Distance" 3672 "Distance" 3673 "Distance" 3674 "Distance" 3675 "Distance" 3676 "Distance" 3677 "Distance" 3678 "Distance" 3679 "Distance" 3680 "Distance" 3681 "Distance" 3682 "Distance" 3683 "Distance" 3684 "Distance" 3685 "Distance" 3686 "Distance" 3687 "Distance" 3688 "Distance" 3689 "Distance" 3690 "Distance" 3691 "Distance" 3692 "Distance" 3693 "Distance" 3694 "Distance" 3695 "Distance" 3696 "Distance" 3697 "Distance" 3698 "Distance" 3699 "Distance" 3700 "Distance" 3701 "Distance" 3702 "Distance" 3703 "Distance" 3704 "Distance" 3705 "Distance" 3706 "Distance" 3707 "Distance" 3708 "Distance" 3709 "Distance" 3710 "Distance" 3711 "Distance" 3712 "Distance" 3713 "Distance" 3714 "Distance" 3715 "Distance" 3716 "Distance" 3717 "Distance" 3718 "Distance" 3719 "Distance" 3720 "Distance" 3721 "Distance" 3722 "Distance" 3723 "Distance" 3724 "Distance" 3725 "Distance" 3726 "Distance" 3727 "Distance" 3728 "Distance" 3729 "Distance" 3730 "Distance" 3731 "Distance" 3732 "Distance" 3733 "Distance" 3734 "Distance" 3735 "Distance" 3736 "Distance" 3737 "Distance" 3738 "Distance" 3739 "Distance" 3740 "Distance" 3741 "Distance" 3742 "Distance" 3743 "Distance" 3744 "Distance" 3745 "Distance" 3746 "Distance" 3747 "Distance" 3748 "Distance" 3749 "Distance" 3750 "Distance" 3751 "Distance" 3752 "Distance" 3753 "Distance" 3754 "Distance" 3755 "Distance" 3756 "Distance" 3757 "Distance" 3758 "Distance" 3759 "Distance" 3760 "Distance" 3761 "Distance" 3762 "Distance" 3763 "Distance" 3764 "Distance" 3765 "Distance" 3766 "Distance" 3767 "Distance" 3768 "Distance" 3769 "Distance" 3770 "Distance" 3771 "Distance" 3772 "Distance" 3773 "Distance" 3774 "Distance" 3775 "Distance" 3776 "Distance" 3777 "Distance" 3778 "Distance" 3779 "Distance" 3780 "Distance" 3781 "Distance" 3782 "Distance" 3783 "Distance" 3784 "Distance" 3785 "Distance" 3786 "Distance" 3787 "Distance" 3788 "Distance" 3789 "Distance" 3790 "Distance" 3791 "Distance" 3792 "Distance" 3793 "Distance" 3794 "Distance" 3795 "Distance" 3796 "Distance" 3797 "Distance" 3798 "Distance" 3799 "Distance" 3800 "Distance" 3801 "Distance" 3802 "Distance" 3803 "Distance" 3804 "Distance" 3805 "Distance" 3806 "Distance" 3807 "Distance" 3808 "Distance" 3809 "Distance" 3810 "Distance" 3811 "Distance" 3812 "Distance" 3813 "Distance" 3814 "Distance" 3815 "Distance" 3816 "Distance" 3817 "Distance" 3818 "Distance" 3819 "Distance" 3820 "Distance" 3821 "Distance" 3822 "Distance" 3823 "Distance" 3824 "Distance" 3825 "Distance" 3826 "Distance" 3827 "Distance" 3828 "Distance" 3829 "Distance" 3830 "Distance" 3831 "Distance" 3832 "Distance" 3833 "Distance" 3834 "Distance" 3835 "Distance" 3836 "Distance" 3837 "Distance" 3838 "Distance" 3839 "Distance" 3840 "Distance" 3841 "Distance" 3842 "Distance" 3843 "Distance" 3844 "Distance" 3845 "Distance" 3846 "Distance" 3847 "Distance" 3848 "Distance" 3849 "Distance" 3850 "Distance" 3851 "Distance" 3852 "Distance" 3853 "Distance" 3854 "Distance" 3855 "Distance" 3856 "Distance" 3857 "Distance" 3858 "Distance" 3859 "Distance" 3860 "Distance" 3861 "Distance" 3862 "Distance" 3863 "Distance" 3864 "Distance" 3865 "Distance" 3866 "Distance" 3867 "Distance" 3868 "Distance" 3869 "Distance" 3870 "Distance" 3871 "Distance" 3872 "Distance" 3873 "Distance" 3874 "Distance" 3875 "Distance" 3876 "Distance" 3877 "Distance" 3878 "Distance" 3879 "Distance" 3880 "Distance" 3881 "Distance" 3882 "Distance" 3883 "Distance" 3884 "Distance" 3885 "Distance" 3886 "Distance" 3887 "Distance" 3888 "Distance" 3889 "Distance" 3890 "Distance" 3891 "Distance" 3892 "Distance" 3893 "Distance" 3894 "Distance" 3895 "Distance" 3896 "Distance" 3897 "Distance" 3898 "Distance" 3899 "Distance" 3900 "Distance" 3901 "Distance" 3902 "Distance" 3903 "Distance" 3904 "Distance" 3905 "Distance" 3906 "Distance" 3907 "Distance" 3908 "Distance" 3909 "Distance" 3910 "Distance" 3911 "Distance" 3912 "Distance" 3913 "Distance" 3914 "Distance" 3915 "Distance" 3916 "Distance" 3917 "Distance" 3918 "Distance" 3919 "Distance" 3920 "Distance" 3921 "Distance" 3922 "Distance" 3923 "Distance" 3924 "Distance" 3925 "Distance" 3926 "Distance" 3927 "Distance" 3928 "Distance" 3929 "Distance" 3930 "Distance" 3931 "Distance" 3932 "Distance" 3933 "Distance" 3934 "Distance" 3935 "Distance" 3936 "Distance" 3937 "Distance" 3938 "Distance" 3939 "Distance" 3940 "Distance" 3941 "Distance" 3942 "Distance" 3943 "Distance" 3944 "Distance" 3945 "Distance" 3946 "Distance" 3947 "Distance" 3948 "Distance" 3949 "Distance" 3950 "Distance" 3951 "Distance" 3952 "Distance" 3953 "Distance" 3954 "Distance" 3955 "Distance" 3956 "Distance" 3957 "Distance" 3958 "Distance" 3959 "Distance" 3960 "Distance" 3961 "Distance" 3962 "Distance" 3963 "Distance" 3964 "Distance" 3965 "Distance" 3966 "Distance" 3967 "Distance" 3968 "Distance" 3969 "Distance" 3970 "Distance" 3971 "Distance" 3972 "Distance" 3973 "Distance" 3974 "Distance" 3975 "Distance" 3976 "Distance" 3977 "Distance" 3978 "Distance" 3979 "Distance" 3980 "Distance" 3981 "Distance" 3982 "Distance" 3983 "Distance" 3984 "Distance" 3985 "Distance" 3986 "Distance" 3987 "Distance" 3988 "Distance" 3989 "Distance" 3990 "Distance" 3991 "Distance" 3992 "Distance" 3993 "Distance" 3994 "Distance" 3995 "Distance" 3996 "Distance" 3997 "Distance" 3998 "Distance" 3999 "Distance" 4000 "Distance" 4001 "Distance" 4002 "Distance" 4003 "Distance" 4004 "Distance" 4005 "Distance" 4006 "Distance" 4007 "Distance" 4008 "Distance" 4009 "Distance" 4010 "Distance" 4011 "Distance" 4012 "Distance" 4013 "Distance" 4014 "Distance" 4015 "Distance" 4016 "Distance" 4017 "Distance" 4018 "Distance" 4019 "Distance" 4020 "Distance" 4021 "Distance" 4022 "Distance" 4023 "Distance" 4024 "Distance" 4025 "Distance" 4026 "Distance" 4027 "Distance" 4028 "Distance" 4029 "Distance" 4030 "Distance" 4031 "Distance" 4032 "Distance" 4033 "Distance" 4034 "Distance" 4035 "Distance" 4036 "Distance" 4037 "Distance" 4038 "Distance" 4039 "Distance" 4040 "Distance" 4041 "Distance" 4042 "Distance" 4043 "Distance" 4044 "Distance" 4045 "Distance" 4046 "Distance" 4047 "Distance" 4048 "Distance" 4049 "Distance" 4050 "Distance" 4051 "Distance" 4052 "Distance" 4053 "Distance" 4054 "Distance" 4055 "Distance" 4056 "Distance" 4057 "Distance" 4058 "Distance" 4059 "Distance" 4060 "Distance" 4061 "Distance" 4062 "Distance" 4063 "Distance" 4064 "Distance" 4065 "Distance" 4066 "Distance" 4067 "Distance" 4068 "Distance" 4069 "Distance" 4070 "Distance" 4071 "Distance" 4072 "Distance" 4073 "Distance" 4074 "Distance" 4075 "Distance" 4076 "Distance" 4077 "Distance" 4078 "Distance" 4079 "Distance" 4080 "Distance" 4081 "Distance" 4082 "Distance" 4083 "Distance" 4084 "Distance" 4085 "Distance" 4086 "Distance" 4087 "Distance" 4088 "Distance" 4089 "Distance" 4090 "Distance" 4091 "Distance" 4092 "Distance" 4093 "Distance" 4094 "Distance" 4095 "Distance" 4096 "Distance" 4097 "Distance" 4098 "Distance" 4099 "Distance" 4100 "Distance" 4101 "Distance" 4102 "Distance" 4103 "Distance" 4104 "Distance" 4105 "Distance" 4106 "Distance" 4107 "Distance" 4108 "Distance" 4109 "Distance" 4110 "Distance" 4111 "Distance" 4112 "Distance" 4113 "Distance" 4114 "Distance" 4115 "Distance" 4116 "Distance" 4117 "Distance" 4118 "Distance" 4119 "Distance" 4120 "Distance" 4121 "Distance" 4122 "Distance" 4123 "Distance" 4124 "Distance" 4125 "Distance" 4126 "Distance" 4127 "Distance" 4128 "Distance" 4129 "Distance" 4130 "Distance" 4131 "Distance" 4132 "Distance" 4133 "Distance" 4134 "Distance" 4135 "Distance" 4136 "Distance" 4137 "Distance" 4138 "Distance" 4139 "Distance" 4140 "Distance" 4141 "Distance" 4142 "Distance" 4143 "Distance" 4144 "Distance" 4145 "Distance" 4146 "Distance" 4147 "Distance" 4148 "Distance" 4149 "Distance" 4150 "Distance" 4151 "Distance" 4152 "Distance" 4153 "Distance" 4154 "Distance" 4155 "Distance" 4156 "Distance" 4157 "Distance" 4158 "Distance" 4159 "Distance" 4160 "Distance" 4161 "Distance" 4162 "Distance" 4163 "Distance" 4164 "Distance" 4165 "Distance" 4166 "Distance" 4167 "Distance" 4168 "Distance" 4169 "Distance" 4170 "Distance" 4171 "Distance" 4172 "Distance" 4173 "Distance" 4174 "Distance" 4175 "Distance" 4176 "Distance" 4177 "Distance" 4178 "Distance" 4179 "Distance" 4180 "Distance" 4181 "Distance" 4182 "Distance" 4183 "Distance" 4184 "Distance" 4185 "Distance" 4186 "Distance" 4187 "Distance" 4188 "Distance" 4189 "Distance" 4190 "Distance" 4191 "Distance" 4192 "Distance" 4193 "Distance" 4194 "Distance" 4195 "Distance" 4196 "Distance" 4197 "Distance" 4198 "Distance" 4199 "Distance" 4200 "Distance" 4201 "Distance" 4202 "Distance" 4203 "Distance" 4204 "Distance" 4205 "Distance" 4206 "Distance" 4207 "Distance" 4208 "Distance" 4209 "Distance" 4210 "Distance" 4211 "Distance" 4212 "Distance" 4213 "Distance" 4214 "Distance" 4215 "Distance" 4216 "Distance" 4217 "Distance" 4218 "Distance" 4219 "Distance" 4220 "Distance" 4221 "Distance" 4222 "Distance" 4223 "Distance" 4224 "Distance" 4225 "Distance" 4226 "Distance" 4227 "Distance" 4228 "Distance" 4229 "Distance" 4230 "Distance" 4231 "Distance" 4232 "Distance" 4233 "Distance" 4234 "Distance" 4235 "Distance" 4236 "Distance" 4237 "Distance" 4238 "Distance" 4239 "Distance" 4240 "Distance" 4241 "Distance" 4242 "Distance" 4243 "Distance" 4244 "Distance" 4245 "Distance" 4246 "Distance" 4247 "Distance" 4248 "Distance" 4249 "Distance" 4250 "Distance" 4251 "Distance" 4252 "Distance" 4253 "Distance" 4254 "Distance" 4255 "Distance" 4256 "Distance" 4257 "Distance" 4258 "Distance" 4259 "Distance" 4260 "Distance" 4261 "Distance" 4262 "Distance" 4263 "Distance" 4264 "Distance" 4265 "Distance" 4266 "Distance" 4267 "Distance" 4268 "Distance" 4269 "Distance" 4270 "Distance" 4271 "Distance" 4272 "Distance" 4273 "Distance" 4274 "Distance" 4275 "Distance" 4276 "Distance" 4277 "Distance" 4278 "Distance" 4279 "Distance" 4280 "Distance" 4281 "Distance" 4282 "Distance" 4283 "Distance" 4284 "Distance" 4285 "Distance" 4286 "Distance" 4287 "Distance" 4288 "Distance" 4289 "Distance" 4290 "Distance" 4291 "Distance" 4292 "Distance" 4293 "Distance" 4294 "Distance" 4295 "Distance" 4296 "Distance" 4297 "Distance" 4298 "Distance" 4299 "Distance" 4300 "Distance" 4301 "Distance" 4302 "Distance" 4303 "Distance" 4304 "Distance" 4305 "Distance" 4306 "Distance" 4307 "Distance" 4308 "Distance" 4309 "Distance" 4310 "Distance" 4311 "Distance" 4312 "Distance" 4313 "Distance" 4314 "Distance" 4315 "Distance" 4316 "Distance" 4317 "Distance" 4318 "Distance" 4319 "Distance" 4320 "Distance" 4321 "Distance" 4322 "Distance" 4323 "Distance" 4324 "Distance" 4325 "Distance" 4326 "Distance" 4327 "Distance" 4328 "Distance" 4329 "Distance" 4330 "Distance" 4331 "Distance" 4332 "Distance" 4333 "Distance" 4334 "Distance" 4335 "Distance" 4336 "Distance" 4337 "Distance" 4338 "Distance" 4339 "Distance" 4340 "Distance" 4341 "Distance" 4342 "Distance" 4343 "Distance" 4344 "Distance" 4345 "Distance" 4346 "Distance" 4347 "Distance" 4348 "Distance" 4349 "Distance" 4350 "Distance" 4351 "Distance" 4352 "Distance" 4353 "Distance" 4354 "Distance" 4355 "Distance" 4356 "Distance" 4357 "Distance" 4358 "Distance" 4359 "Distance" 4360 "Distance" 4361 "Distance" 4362 "Distance" 4363 "Distance" 4364 "Distance" 4365 "Distance" 4366 "Distance" 4367 "Distance" 4368 "Distance" 4369 "Distance" 4370 "Distance" 4371 "Distance" 4372 "Distance" 4373 "Distance" 4374 "Distance" 4375 "Distance" 4376 "Distance" 4377 "Distance" 4378 "Distance" 4379 "Distance" 4380 "Distance" 4381 "Distance" 4382 "Distance" 4383 "Distance" 4384 "Distance" 4385 "Distance" 4386 "Distance" 4387 "Distance" 4388 "Distance" 4389 "Distance" 4390 "Distance" 4391 "Distance" 4392 "Distance" 4393 "Distance" 4394 "Distance" 4395 "Distance" 4396 "Distance" 4397 "Distance" 4398 "Distance" 4399 "Distance" 4400 "Distance" 4401 "Distance" 4402 "Distance" 4403 "Distance" 4404 "Distance" 4405 "Distance" 4406 "Distance" 4407 "Distance" 4408 "Distance" 4409 "Distance" 4410 "Distance" 4411 "Distance" 4412 "Distance" 4413 "Distance" 4414 "Distance" 4415 "Distance" 4416 "Distance" 4417 "Distance" 4418 "Distance" 4419 "Distance" 4420 "Distance" 4421 "Distance" 4422 "Distance" 4423 "Distance" 4424 "Distance" 4425 "Distance" 4426 "Distance" 4427 "Distance" 4428 "Distance" 4429 "Distance" 4430 "Distance" 4431 "Distance" 4432 "Distance" 4433 "Distance" 4434 "Distance" 4435 "Distance" 4436 "Distance" 4437 "Distance" 4438 "Distance" 4439 "Distance" 4440 "Distance" 4441 "Distance" 4442 "Distance" 4443 "Distance" 4444 "Distance" 4445 "Distance" 4446 "Distance" 4447 "Distance" 4448 "Distance" 4449 "Distance" 4450 "Distance" 4451 "Distance" 4452 "Distance" 4453 "Distance" 4454 "Distance" 4455 "Distance" 4456 "Distance" 4457 "Distance" 4458 "Distance" 4459 "Distance" 4460 "Distance" 4461 "Distance" 4462 "Distance" 4463 "Distance" 4464 "Distance" 4465 "Distance" 4466 "Distance" 4467 "Distance" 4468 "Distance" 4469 "Distance" 4470 "Distance" 4471 "Distance" 4472 "Distance" 4473 "Distance" 4474 "Distance" 4475 "Distance" 4476 "Distance" 4477 "Distance" 4478 "Distance" 4479 "Distance" 4480 "Distance" 4481 "Distance" 4482 "Distance" 4483 "Distance" 4484 "Distance" 4485 "Distance" 4486 "Distance" 4487 "Distance" 4488 "Distance" 4489 "Distance" 4490 "Distance" 4491 "Distance" 4492 "Distance" 4493 "Distance" 4494 "Distance" 4495 "Distance" 4496 "Distance" 4497 "Distance" 4498 "Distance" 4499 "Distance" 4500 "Distance" 4501 "Distance" 4502 "Distance" 4503 "Distance" 4504 "Distance" 4505 "Distance" 4506 "Distance" 4507 "Distance" 4508 "Distance" 4509 "Distance" 4510 "Distance" 4511 "Distance" 4512 "Distance" 4513 "Distance" 4514 "Distance" 4515 "Distance" 4516 "Distance" 4517 "Distance" 4518 "Distance" 4519 "Distance" 4520 "Distance" 4521 "Distance" 4522 "Distance" 4523 "Distance" 4524 "Distance" 4525 "Distance" 4526 "Distance" 4527 "Distance" 4528 "Distance" 4529 "Distance" 4530 "Distance" 4531 "Distance" 4532 "Distance" 4533 "Distance" 4534 "Distance" 4535 "Distance" 4536 "Distance" 4537 "Distance" 4538 "Distance" 4539 "Distance" 4540 "Distance" 4541 "Distance" 4542 "Distance" 4543 "Distance" 4544 "Distance" 4545 "Distance" 4546 "Distance" 4547 "Distance" 4548 "Distance" 4549 "Distance" 4550 "Distance" 4551 "Distance" 4552 "Distance" 4553 "Distance" 4554 "Distance" 4555 "Distance" 4556 "Distance" 4557 "Distance" 4558 "Distance" 4559 "Distance" 4560 "Distance" 4561 "Distance" 4562 "Distance" 4563 "Distance" 4564 "Distance" 4565 "Distance" 4566 "Distance" 4567 "Distance" 4568 "Distance" 4569 "Distance" 4570 "Distance" 4571 "Distance" 4572 "Distance" 4573 "Distance" 4574 "Distance" 4575 "Distance" 4576 "Distance" 4577 "Distance" 4578 "Distance" 4579 "Distance" 4580 "Distance" 4581 "Distance" 4582 "Distance" 4583 "Distance" 4584 "Distance" 4585 "Distance" 4586 "Distance" 4587 "Distance" 4588 "Distance" 4589 "Distance" 4590 "Distance" 4591 "Distance" 4592 "Distance" 4593 "Distance" 4594 "Distance" 4595 "Distance" 4596 "Distance" 4597 "Distance" 4598 "Distance" 4599 "Distance" 4600 "Distance" 4601 "Distance" 4602 "Distance" 4603 "Distance" 4604 "Distance" 4605 "Distance" 4606 "Distance" 4607 "Distance" 4608 "Distance" 4609 "Distance" 4610 "Distance" 4611 "Distance" 4612 "Distance" 4613 "Distance" 4614 "Distance" 4615 "Distance" 4616 "Distance" 4617 "Distance" 4618 "Distance" 4619 "Distance" 4620 "Distance" 4621 "Distance" 4622 "Distance" 4623 "Distance" 4624 "Distance" 4625 "Distance" 4626 "Distance" 4627 "Distance" 4628 "Distance" 4629 "Distance" 4630 "Distance" 4631 "Distance" 4632 "Distance" 4633 "Distance" 4634 "Distance" 4635 "Distance" 4636 "Distance" 4637 "Distance" 4638 "Distance" 4639 "Distance" 4640 "Distance" 4641 "Distance" 4642 "Distance" 4643 "Distance" 4644 "Distance" 4645 "Distance" 4646 "Distance" 4647 "Distance" 4648 "Distance" 4649 "Distance" 4650 "Distance" 4651 "Distance" 4652 "Distance" 4653 "Distance" 4654 "Distance" 4655 "Distance" 4656 "Distance" 4657 "Distance" 4658 "Distance" 4659 "Distance" 4660 "Distance" 4661 "Distance" 4662 "Distance" 4663 "Distance" 4664 "Distance" 4665 "Distance" 4666 "Distance" 4667 "Distance" 4668 "Distance" 4669 "Distance" 4670 "Distance" 4671 "Distance" 4672 "Distance" 4673 "Distance" 4674 "Distance" 4675 "Distance" 4676 "Distance" 4677 "Distance" 4678 "Distance" 4679 "Distance" 4680 "Distance" 4681 "Distance" 4682 "Distance" 4683 "Distance" 4684 "Distance" 4685 "Distance" 4686 "Distance" 4687 "Distance" 4688 "Distance" 4689 "Distance" 4690 "Distance" 4691 "Distance" 4692 "Distance" 4693 "Distance" 4694 "Distance" 4695 "Distance" 4696 "Distance" 4697 "Distance" 4698 "Distance" 4699 "Distance" 4700 "Distance" 4701 "Distance" 4702 "Distance" 4703 "Distance" 4704 "Distance" 4705 "Distance" 4706 "Distance" 4707 "Distance" 4708 "Distance" 4709 "Distance" 4710 "Distance" 4711 "Distance" 4712 "Distance" 4713 "Distance" 4714 "Distance" 4715 "Distance" 4716 "Distance" 4717 "Distance" 4718 "Distance" 4719 "Distance" 4720 "Distance" 4721 "Distance" 4722 "Distance" 4723 "Distance" 4724 "Distance" 4725 "Distance" 4726 "Distance" 4727 "Distance" 4728 "Distance" 4729 "Distance" 4730 "Distance" 4731 "Distance" 4732 "Distance" 4733 "Distance" 4734 "Distance" 4735 "Distance" 4736 "Distance" 4737 "Distance" 4738 "Distance" 4739 "Distance" 4740 "Distance" 4741 "Distance" 4742 "Distance" 4743 "Distance" 4744 "Distance" 4745 "Distance" 4746 "Distance" 4747 "Distance" 4748 "Distance" 4749 "Distance" 4750 "Distance" 4751 "Distance" 4752 "Distance" 4753 "Distance" 4754 "Distance" 4755 "Distance" 4756 "Distance" 4757 "Distance" 4758 "Distance" 4759 "Distance" 4760 "Distance" 4761 "Distance" 4762 "Distance" 4763 "Distance" 4764 "Distance" 4765 "Distance" 4766 "Distance" 4767 "Distance" 4768 "Distance" 4769 "Distance" 4770 "Distance" 4771 "Distance" 4772 "Distance" 4773 "Distance" 4774 "Distance" 4775 "Distance" 4776 "Distance" 4777 "Distance" 4778 "Distance" 4779 "Distance" 4780 "Distance" 4781 "Distance" 4782 "Distance" 4783 "Distance" 4784 "Distance" 4785 "Distance" 4786 "Distance" 4787 "Distance" 4788 "Distance" 4789 "Distance" 4790 "Distance" 4791 "Distance" 4792 "Distance" 4793 "Distance" 4794 "Distance" 4795 "Distance" 4796 "Distance" 4797 "Distance" 4798 "Distance" 4799 "Distance" 4800 "Distance" 4801 "Distance" 4802 "Distance" 4803 "Distance" 4804 "Distance" 4805 "Distance" 4806 "Distance" 4807 "Distance" 4808 "Distance" 4809 "Distance" 4810 "Distance" 4811 "Distance" 4812 "Distance" 4813 "Distance" 4814 "Distance" 4815 "Distance" 4816 "Distance" 4817 "Distance" 4818 "Distance" 4819 "Distance" 4820 "Distance" 4821 "Distance" 4822 "Distance" 4823 "Distance" 4824 "Distance" 4825 "Distance" 4826 "Distance" 4827 "Distance" 4828 "Distance" 4829 "Distance" 4830 "Distance" 4831 "Distance" 4832 "Distance" 4833 "Distance" 4834 "Distance" 4835 "Distance" 4836 "Distance" 4837 "Distance" 4838 "Distance" 4839 "Distance" 4840 "Distance" 4841 "Distance" 4842 "Distance" 4843 "Distance" 4844 "Distance" 4845 "Distance" 4846 "Distance" 4847 "Distance" 4848 "Distance" 4849 "Distance" 4850 "Distance" 4851 "Distance" 4852 "Distance" 4853 "Distance" 4854 "Distance" 4855 "Distance" 4856 "Distance" 4857 "Distance" 4858 "Distance" 4859 "Distance" 4860 "Distance" 4861 "Distance" 4862 "Distance" 4863 "Distance" 4864 "Distance" 4865 "Distance" 4866 "Distance" 4867 "Distance" 4868 "Distance" 4869 "Distance" 4870 "Distance" 4871 "Distance" 4872 "Distance" 4873 "Distance" 4874 "Distance" 4875 "Distance" 4876 "Distance" 4877 "Distance" 4878 "Distance" 4879 "Distance" 4880 "Distance" 4881 "Distance" 4882 "Distance" 4883 "Distance" 4884 "Distance" 4885 "Distance" 4886 "Distance" 4887 "Distance" 4888 "Distance" 4889 "Distance" 4890 "Distance" 4891 "Distance" 4892 "Distance" 4893 "Distance" 4894 "Distance" 4895 "Distance" 4896 "Distance" 4897 "Distance" 4898 "Distance" 4899 "Distance" 4900 "Distance" 4901 "Distance" 4902 "Distance" 4903 "Distance" 4904 "Distance" 4905 "Distance" 4906 "Distance" 4907 "Distance" 4908 "Distance" 4909 "Distance" 4910 "Distance" 4911 "Distance" 4912 "Distance" 4913 "Distance" 4914 "Distance" 4915 "Distance" 4916 "Distance" 4917 "Distance" 4918 "Distance" 4919 "Distance" 4920 "Distance" 4921 "Distance" 4922 "Distance" 4923 "Distance" 4924 "Distance" 4925 "Distance" 4926 "Distance" 4927 "Distance" 4928 "Distance" 4929 "Distance" 4930 "Distance" 4931 "Distance" 4932 "Distance" 4933 "Distance" 4934 "Distance" 4935 "Distance" 4936 "Distance" 4937 "Distance" 4938 "Distance" 4939 "Distance" 4940 "Distance" 4941 "Distance" 4942 "Distance" 4943 "Distance" 4944 "Distance" 4945 "Distance" 4946 "Distance" 4947 "Distance" 4948 "Distance" 4949 "Distance" 4950 "Distance" 4951 "Distance" 4952 "Distance" 4953 "Distance" 4954 "Distance" 4955 "Distance" 4956 "Distance" 4957 "Distance" 4958 "Distance" 4959 "Distance" 4960 "Distance" 4961 "Distance" 4962 "Distance" 4963 "Distance" 4964 "Distance" 4965 "Distance" 4966 "Distance" 4967 "Distance" 4968 "Distance" 4969 "Distance" 4970 "Distance" 4971 "Distance" 4972 "Distance" 4973 "Distance" 4974 "Distance" 4975 "Distance" 4976 "Distance" 4977 "Distance" 4978 "Distance" 4979 "Distance" 4980 "Distance" 4981 "Distance" 4982 "Distance" 4983 "Distance" 4984 "Distance" 4985 "Distance" 4986 "Distance" 4987 "Distance" 4988 "Distance" 4989 "Distance" 4990 "Distance" 4991 "Distance" 4992 "Distance" 4993 "Distance" 4994 "Distance" 4995 "Distance" 4996 "Distance" 4997 "Distance" 4998 "Distance" 4999 "Distance" 5000 "Distance" 5001 "Distance" 5002 "Distance" 5003 "Distance" 5004 "Distance" 5005 "Distance" 5006 "Distance" 5007 "Distance" 5008 "Distance" 5009 "Distance" 5010 "Distance" 5011 "Distance" 5012 "Distance" 5013 "Distance" 5014 "Distance" 5015 "Distance" 5016 "Distance" 5017 "Distance" 5018 "Distance" 5019 "Distance" 5020 "Distance" 5021 "Distance" 5022 "Distance" 5023 "Distance" 5024 "Distance" 5025 "Distance" 5026 "Distance" 5027 "Distance" 5028 "Distance" 5029 "Distance" 5030 "Distance" 5031 "Distance" 5032 "Distance" 5033 "Distance" 5034 "Distance" 5035 "Distance" 5036 "Distance" 5037 "Distance" 5038 "Distance" 5039 "Distance" 5040 "Distance" 5041 "Distance" 5042 "Distance" 5043 "Distance" 5044 "Distance" 5045 "Distance" 5046 "Distance" 5047 "Distance" 5048 "Distance" 5049 "Distance" 5050 "Distance" 5051 "Distance" 5052 "Distance" 5053 "Distance" 5054 "Distance" 5055 "Distance" 5056 "Distance" 5057 "Distance" 5058 "Distance" 5059 "Distance" 5060 "Distance" 5061 "Distance" 5062 "Distance" 5063 "Distance" 5064 "Distance" 5065 "Distance" 5066 "Distance" 5067 "Distance" 5068 "Distance" 5069 "Distance" 5070 "Distance" 5071 "Distance" 5072 "Distance" 5073 "Distance" 5074 "Distance" 5075 "Distance" 5076 "Distance" 5077 "Distance" 5078 "Distance" 5079 "Distance" 5080 "Distance" 5081 "Distance" 5082 "Distance" 5083 "Distance" 5084 "Distance" 5085 "Distance" 5086 "Distance" 5087 "Distance" 5088 "Distance" 5089 "Distance" 5090 "Distance" 5091 "Distance" 5092 "Distance" 5093 "Distance" 5094 "Distance" 5095 "Distance" 5096 "Distance" 5097 "Distance" 5098 "Distance" 5099 "Distance" 5100 "Distance" 5101 "Distance" 5102 "Distance" 5103 "Distance" 5104 "Distance" 5105 "Distance" 5106 "Distance" 5107 "Distance" 5108 "Distance" 5109 "Distance" 5110 "Distance" 5111 "Distance" 5112 "Distance" 5113 "Distance" 5114 "Distance" 5115 "Distance" 5116 "Distance" 5117 "Distance" 5118 "Distance" 5119 "Distance" 5120 "Distance" 5121 "Distance" 5122 "Distance" 5123 "Distance" 5124 "Distance" 5125 "Distance" 5126 "Distance" 5127 "Distance" 5128 "Distance" 5129 "Distance" 5130 "Distance" 5131 "Distance" 5132 "Distance" 5133 "Distance" 5134 "Distance" 5135 "Distance" 5136 "Distance" 5137 "Distance" 5138 "Distance" 5139 "Distance" 5140 "Distance" 5141 "Distance" 5142 "Distance" 5143 "Distance" 5144 "Distance" 5145 "Distance" 5146 "Distance" 5147 "Distance" 5148 "Distance" 5149 "Distance" 5150 "Distance" 5151 "Distance" 5152 "Distance" 5153 "Distance" 5154 "Distance" 5155 "Distance" 5156 "Distance" 5157 "Distance" 5158 "Distance" 5159 "Distance" 5160 "Distance" 5161 "Distance" 5162 "Distance" 5163 "Distance" 5164 "Distance" 5165 "Distance" 5166 "Distance" 5167 "Distance" 5168 "Distance" 5169 "Distance" 5170 "Distance" 5171 "Distance" 5172 "Distance" 5173 "Distance" 5174 "Distance" 5175 "Distance" 5176 "Distance" 5177 "Distance" 5178 "Distance" 5179 "Distance" 5180 "Distance" 5181 "Distance" 5182 "Distance" 5183 "Distance" 5184 "Distance" 5185 "Distance" 5186 "Distance" 5187 "Distance" 5188 "Distance" 5189 "Distance" 5190 "Distance" 5191 "Distance" 5192 "Distance" 5193 "Distance" 5194 "Distance" 5195 "Distance" 5196 "Distance" 5197 "Distance" 5198 "Distance" 5199 "Distance" 5200 "Distance" 5201 "Distance" 5202 "Distance" 5203 "Distance" 5204 "Distance" 5205 "Distance" 5206 "Distance" 5207 "Distance" 5208 "Distance" 5209 "Distance" 5210 "Distance" 5211 "Distance" 5212 "Distance" 5213 "Distance" 5214 "Distance" 5215 "Distance" 5216 "Distance" 5217 "Distance" 5218 "Distance" 5219 "Distance" 5220 "Distance" 5221 "Distance" 5222 "Distance" 5223 "Distance" 5224 "Distance" 5225 "Distance" 5226 "Distance" 5227 "Distance" 5228 "Distance" 5229 "Distance" 5230 "Distance" 5231 "Distance" 5232 "Distance" 5233 "Distance" 5234 "Distance" 5235 "Distance" 5236 "Distance" 5237 "Distance" 5238 "Distance" 5239 "Distance" 5240 "Distance" 5241 "Distance" 5242 "Distance" 5243 "Distance" 5244 "Distance" 5245 "Distance" 5246 "Distance" 5247 "Distance" 5248 "Distance" 5249 "Distance" 5250 "Distance" 5251 "Distance" 5252 "Distance" 5253 "Distance" 5254 "Distance" 5255 "Distance" 5256 "Distance" 5257 "Distance" 5258 "Distance" 5259 "Distance" 5260 "Distance" 5261 "Distance" 5262 "Distance" 5263 "Distance" 5264 "Distance" 5265 "Distance" 5266 "Distance" 5267 "Distance" 5268 "Distance" 5269 "Distance" 5270 "Distance" 5271 "Distance" 5272 "Distance" 5273 "Distance" 5274 "Distance" 5275 "Distance" 5276 "Distance" 5277 "Distance" 5278 "Distance" 5279 "Distance" 5280 "Distance" 5281 "Distance" 5282 "Distance" 5283 "Distance" 5284 "Distance" 5285 "Distance" 5286 "Distance" 5287 "Distance" 5288 "Distance" 5289 "Distance" 5290 "Distance" 5291 "Distance" 5292 "Distance" 5293 "Distance" 5294 "Distance" 5295 "Distance" 5296 "Distance" 5297 "Distance" 5298 "Distance" 5299 "Distance" 5300 "Distance" 5301 "Distance" 5302 "Distance" 5303 "Distance" 5304 "Distance" 5305 "Distance" 5306 "Distance" 5307 "Distance" 5308 "Distance" 5309 "Distance" 5310 "Distance" 5311 "Distance" 5312 "Distance" 5313 "Distance" 5314 "Distance" 5315 "Distance" 5316 "Distance" 5317 "Distance" 5318 "Distance" 5319 "Distance" 5320 "Distance" 5321 "Distance" 5322 "Distance" 5323 "Distance" 5324 "Distance" 5325 "Distance" 5326 "Distance" 5327 "Distance" 5328 "Distance" 5329 "Distance" 5330 "Distance" 5331 "Distance" 5332 "Distance" 5333 "Distance" 5334 "Distance" 5335 "Distance" 5336 "Distance" 5337 "Distance" 5338 "Distance" 5339 "Distance" 5340 "Distance" 5341 "Distance" 5342 "Distance" 5343 "Distance" 5344 "Distance" 5345 "Distance" 5346 "Distance" 5347 "Distance" 5348 "Distance" 5349 "Distance" 5350 "Distance" 5351 "Distance" 5352 "Distance" 5353 "Distance" 5354 "Distance" 5355 "Distance" 5356 "Distance" 5357 "Distance" 5358 "Distance" 5359 "Distance" 5360 "Distance" 5361 "Distance" 5362 "Distance" 5363 "Distance" 5364 "Distance" 5365 "Distance" 5366 "Distance" 5367 "Distance" 5368 "Distance" 5369 "Distance" 5370 "Distance" 5371 "Distance" 5372 "Distance" 5373 "Distance" 5374 "Distance" 5375 "Distance" 5376 "Distance" 5377 "Distance" 5378 "Distance" 5379 "Distance" 5380 "Distance" 5381 "Distance" 5382 "Distance" 5383 "Distance" 5384 "Distance" 5385 "Distance" 5386 "Distance" 5387 "Distance" 5388 "Distance" 5389 "Distance" 5390 "Distance" 5391 "Distance" 5392 "Distance" 5393 "Distance" 5394 "Distance" 5395 "Distance" 5396 "Distance" 5397 "Distance" 5398 "Distance" 5399 "Distance" 5400 "Distance" 5401 "Distance" 5402 "Distance" 5403 "Distance" 5404 "Distance" 5405 "Distance" 5406 "Distance" 5407 "Distance" 5408 "Distance" 5409 "Distance" 5410 "Distance" 5411 "Distance" 5412 "Distance" 5413 "Distance" 5414 "Distance" 5415 "Distance" 5416 "Distance" 5417 "Distance" 5418 "Distance" 5419 "Distance" 5420 "Distance" 5421 "Distance" 5422 "Distance" 5423 "Distance" 5424 "Distance" 5425 "Distance" 5426 "Distance" 5427 "Distance" 5428 "Distance" 5429 "Distance" 5430 "Distance" 5431 "Distance" 5432 "Distance" 5433 "Distance" 5434 "Distance" 5435 "Distance" 5436 "Distance" 5437 "Distance" 5438 "Distance" 5439 "Distance" 5440 "Distance" 5441 "Distance" 5442 "Distance" 5443 "Distance" 5444 "Distance" 5445 "Distance" 5446 "Distance" 5447 "Distance" 5448 "Distance" 5449 "Distance" 5450 "Distance" 5451 "Distance" 5452 "Distance" 5453 "Distance" 5454 "Distance" 5455 "Distance" 5456 "Distance" 5457 "Distance" 5458 "Distance" 5459 "Distance" 5460 "Distance" 5461 "Distance" 5462 "Distance" 5463 "Distance" 5464 "Distance" 5465 "Distance" 5466 "Distance" 5467 "Distance" 5468 "Distance" 5469 "Distance" 5470 "Distance" 5471 "Distance" 5472 "Distance" 5473 "Distance" 5474 "Distance" 5475 "Distance" 5476 "Distance" 5477 "Distance" 5478 "Distance" 5479 "Distance" 5480 "Distance" 5481 "Distance" 5482 "Distance" 5483 "Distance" 5484 "Distance" 5485 "Distance" 5486 "Distance" 5487 "Distance" 5488 "Distance" 5489 "Distance" 5490 "Distance" 5491 "Distance" 5492 "Distance" 5493 "Distance" 5494 "Distance" 5495 "Distance" 5496 "Distance" 5497 "Distance" 5498 "Distance" 5499 "Distance" 5500 "Distance" 5501 "Distance" 5502 "Distance" 5503 "Distance" 5504 "Distance" 5505 "Distance" 5506 "Distance" 5507 "Distance" 5508 "Distance" 5509 "Distance" 5510 "Distance" 5511 "Distance" 5512 "Distance" 5513 "Distance" 5514 "Distance" 5515 "Distance" 5516 "Distance" 5517 "Distance" 5518 "Distance" 5519 "Distance" 5520 "Distance" 5521 "Distance" 5522 "Distance" 5523 "Distance" 5524 "Distance" 5525 "Distance" 5526 "Distance" 5527 "Distance" 5528 "Distance" 5529 "Distance" 5530 "Distance" 5531 "Distance" 5532 "Distance" 5533 "Distance" 5534 "Distance" 5535 "Distance" 5536 "Distance" 5537 "Distance" 5538 "Distance" 5539 "Distance" 5540 "Distance" 5541 "Distance" 5542 "Distance" 5543 "Distance" 5544 "Distance" 5545 "Distance" 5546 "Distance" 5547 "Distance" 5548 "Distance" 5549 "Distance" 5550 "Distance" 5551 "Distance" 5552 "Distance" 5553 "Distance" 5554 "Distance" 5555 "Distance" 5556 "Distance" 5557 "Distance" 5558 "Distance" 5559 "Distance" 5560 "Distance" 5561 "Distance" 5562 "Distance" 5563 "Distance" 5564 "Distance" 5565 "Distance" 5566 "Distance" 5567 "Distance" 5568 "Distance" 5569 "Distance" 5570 "Distance" 5571 "Distance" 5572 "Distance" 5573 "Distance" 5574 "Distance" 5575 "Distance" 5576 "Distance" 5577 "Distance" 5578 "Distance" 5579 "Distance" 5580 "Distance" 5581 "Distance" 5582 "Distance" 5583 "Distance" 5584 "Distance" 5585 "Distance" 5586 "Distance" 5587 "Distance" 5588 "Distance" 5589 "Distance" 5590 "Distance" 5591 "Distance" 5592 "Distance" 5593 "Distance" 5594 "Distance" 5595 "Distance" 5596 "Distance" 5597 "Distance" 5598 "Distance" 5599 "Distance" 5600 "Distance" 5601 "Distance" 5602 "Distance" 5603 "Distance" 5604 "Distance" 5605 "Distance" 5606 "Distance" 5607 "Distance" 5608 "Distance" 5609 "Distance" 5610 "Distance" 5611 "Distance" 5612 "Distance" 5613 "Distance" 5614 "Distance" 5615 "Distance" 5616 "Distance" 5617 "Distance" 5618 "Distance" 5619 "Distance" 5620 "Distance" 5621 "Distance" 5622 "Distance" 5623 "Distance" 5624 "Distance" 5625 "Distance" 5626 "Distance" 5627 "Distance" 5628 "Distance" 5629 "Distance" 5630 "Distance" 5631 "Distance" 5632 "Distance" 5633 "Distance" 5634 "Distance" 5635 "Distance" 5636 "Distance" 5637 "Distance" 5638 "Distance" 5639 "Distance" 5640 "Distance" 5641 "Distance" 5642 "Distance" 5643 "Distance" 5644 "Distance" 5645 "Distance" 5646 "Distance" 5647 "Distance" 5648 "Distance" 5649 "Distance" 5650 "Distance" 5651 "Distance" 5652 "Distance" 5653 "Distance" 5654 "Distance" 5655 "Distance" 5656 "Distance" 5657 "Distance" 5658 "Distance" 5659 "Distance" 5660 "Distance" 5661 "Distance" 5662 "Distance" 5663 "Distance" 5664 "Distance" 5665 "Distance" 5666 "Distance" 5667 "Distance" 5668 "Distance" 5669 "Distance" 5670 "Distance" 5671 "Distance" 5672 "Distance" 5673 "Distance" 5674 "Distance" 5675 "Distance" 5676 "Distance" 5677 "Distance" 5678 "Distance" 5679 "Distance" 5680 "Distance" 5681 "Distance" 5682 "Distance" 5683 "Distance" 5684 "Distance" 5685 "Distance" 5686 "Distance" 5687 "Distance" 5688 "Distance" 5689 "Distance" 5690 "Distance" 5691 "Distance" 5692 "Distance" 5693 "Distance" 5694 "Distance" 5695 "Distance" 5696 "Distance" 5697 "Distance" 5698 "Distance" 5699 "Distance" 5700 "Distance" 5701 "Distance" 5702 "Distance" 5703 "Distance" 5704 "Distance" 5705 "Distance" 5706 "Distance" 5707 "Distance" 5708 "Distance" 5709 "Distance" 5710 "Distance" 5711 "Distance" 5712 "Distance" 5713 "Distance" 5714 "Distance" 5715 "Distance" 5716 "Distance" 5717 "Distance" 5718 "Distance" 5719 "Distance" 5720 "Distance" 5721 "Distance" 5722 "Distance" 5723 "Distance" 5724 "Distance" 5725 "Distance" 5726 "Distance" 5727 "Distance" 5728 "Distance" 5729 "Distance" 5730 "Distance" 5731 "Distance" 5732 "Distance" 5733 "Distance" 5734 "Distance" 5735 "Distance" 5736 "Distance" 5737 "Distance" 5738 "Distance" 5739 "Distance" 5740 "Distance" 5741 "Distance" 5742 "Distance" 5743 "Distance" 5744 "Distance" 5745 "Distance" 5746 "Distance" 5747 "Distance" 5748 "Distance" 5749 "Distance" 5750 "Distance" 5751 "Distance" 5752 "Distance" 5753 "Distance" 5754 "Distance" 5755 "Distance" 5756 "Distance" 5757 "Distance" 5758 "Distance" 5759 "Distance" 5760 "Distance" 5761 "Distance" 5762 "Distance" 5763 "Distance" 5764 "Distance" 5765 "Distance" 5766 "Distance" 5767 "Distance" 5768 "Distance" 5769 "Distance" 5770 "Distance" 5771 "Distance" 5772 "Distance" 5773 "Distance" 5774 "Distance" 5775 "Distance" 5776 "Distance" 5777 "Distance" 5778 "Distance" 5779 "Distance" 5780 "Distance" 5781 "Distance" 5782 "Distance" 5783 "Distance" 5784 "Distance" 5785 "Distance" 5786 "Distance" 5787 "Distance" 5788 "Distance" 5789 "Distance" 5790 "Distance" 5791 "Distance" 5792 "Distance" 5793 "Distance" 5794 "Distance" 5795 "Distance" 5796 "Distance" 5797 "Distance" 5798 "Distance" 5799 "Distance" 5800 "Distance" 5801 "Distance" 5802 "Distance" 5803 "Distance" 5804 "Distance" 5805 "Distance" 5806 "Distance" 5807 "Distance" 5808 "Distance" 5809 "Distance" 5810 "Distance" 5811 "Distance" 5812 "Distance" 5813 "Distance" 5814 "Distance" 5815 "Distance" 5816 "Distance" 5817 "Distance" 5818 "Distance" 5819 "Distance" 5820 "Distance" 5821 "Distance" 5822 "Distance" 5823 "Distance" 5824 "Distance" 5825 "Distance" 5826 "Distance" 5827 "Distance" 5828 "Distance" 5829 "Distance" 5830 "Distance" 5831 "Distance" 5832 "Distance" 5833 "Distance" 5834 "Distance" 5835 "Distance" 5836 "Distance" 5837 "Distance" 5838 "Distance" 5839 "Distance" 5840 "Distance" 5841 "Distance" 5842 "Distance" 5843 "Distance" 5844 "Distance" 5845 "Distance" 5846 "Distance" 5847 "Distance" 5848 "Distance" 5849 "Distance" 5850 "Distance" 5851 "Distance" 5852 "Distance" 5853 "Distance" 5854 "Distance" 5855 "Distance" 5856 "Distance" 5857 "Distance" 5858 "Distance" 5859 "Distance" 5860 "Distance" 5861 "Distance" 5862 "Distance" 5863 "Distance" 5864 "Distance" 5865 "Distance" 5866 "Distance" 5867 "Distance" 5868 "Distance" 5869 "Distance" 5870 "Distance" 5871 "Distance" 5872 "Distance" 5873 "Distance" 5874 "Distance" 5875 "Distance" 5876 "Distance" 5877 "Distance" 5878 "Distance" 5879 "Distance" 5880 "Distance" 5881 "Distance" 5882 "Distance" 5883 "Distance" 5884 "Distance" 5885 "Distance" 5886 "Distance" 5887 "Distance" 5888 "Distance" 5889 "Distance" 5890 "Distance" 5891 "Distance" 5892 "Distance" 5893 "Distance" 5894 "Distance" 5895 "Distance" 5896 "Distance" 5897 "Distance" 5898 "Distance" 5899 "Distance" 5900 "Distance" 5901 "Distance" 5902 "Distance" 5903 "Distance" 5904 "Distance" 5905 "Distance" 5906 "Distance" 5907 "Distance" 5908 "Distance" 5909 "Distance" 5910 "Distance" 5911 "Distance" 5912 "Distance" 5913 "Distance" 5914 "Distance" 5915 "Distance" 5916 "Distance" 5917 "Distance" 5918 "Distance" 5919 "Distance" 5920 "Distance" 5921 "Distance" 5922 "Distance" 5923 "Distance" 5924 "Distance" 5925 "Distance" 5926 "Distance" 5927 "Distance" 5928 "Distance" 5929 "Distance" 5930 "Distance" 5931 "Distance" 5932 "Distance" 5933 "Distance" 5934 "Distance" 5935 "Distance" 5936 "Distance" 5937 "Distance" 5938 "Distance" 5939 "Distance" 5940 "Distance" 5941 "Distance" 5942 "Distance" 5943 "Distance" 5944 "Distance" 5945 "Distance" 5946 "Distance" 5947 "Distance" 5948 "Distance" 5949 "Distance" 5950 "Distance" 5951 "Distance" 5952 "Distance" 5953 "Distance" 5954 "Distance" 5955 "Distance" 5956 "Distance" 5957 "Distance" 5958 "Distance" 5959 "Distance" 5960 "Distance" 5961 "Distance" 5962 "Distance" 5963 "Distance" 5964 "Distance" 5965 "Distance" 5966 "Distance" 5967 "Distance" 5968 "Distance" 5969 "Distance" 5970 "Distance" 5971 "Distance" 5972 "Distance" 5973 "Distance" 5974 "Distance" 5975 "Distance" 5976 "Distance" 5977 "Distance" 5978 "Distance" 5979 "Distance" 5980 "Distance" 5981 "Distance" 5982 "Distance" 5983 "Distance" 5984 "Distance" 5985 "Distance" 5986 "Distance" 5987 "Distance" 5988 "Distance" 5989 "Distance" 5990 "Distance" 5991 "Distance" 5992 "Distance" 5993 "Distance" 5994 "Distance" 5995 "Distance" 5996 "Distance" 5997 "Distance" 5998 "Distance" 5999 "Distance" 6000 "Distance" 6001 "Distance" 6002 "Distance" 6003 "Distance" 6004 "Distance" 6005 "Distance" 6006 "Distance" 6007 "Distance" 6008 "Distance" 6009 "Distance" 6010 "Distance" 6011 "Distance" 6012 "Distance" 6013 "Distance" 6014 "Distance" 6015 "Distance" 6016 "Distance" 6017 "Distance" 6018 "Distance" 6019 "Distance" 6020 "Distance" 6021 "Distance" 6022 "Distance" 6023 "Distance" 6024 "Distance" 6025 "Distance" 6026 "Distance" 6027 "Distance" 6028 "Distance" 6029 "Distance" 6030 "Distance" 6031 "Distance" 6032 "Distance" 6033 "Distance" 6034 "Distance" 6035 "Distance" 6036 "Distance" 6037 "Distance" 6038 "Distance" 6039 "Distance" 6040 "Distance" 6041 "Distance" 6042 "Distance" 6043 "Distance" 6044 "Distance" 6045 "Distance" 6046 "Distance" 6047 "Distance" 6048 "Distance" 6049 "Distance" 6050 "Distance" 6051 "Distance" 6052 "Distance" 6053 "Distance" 6054 "Distance" 6055 "Distance" 6056 "Distance" 6057 "Distance" 6058 "Distance" 6059 "Distance" 6060 "Distance" 6061 "Distance" 6062 "Distance" 6063 "Distance" 6064 "Distance" 6065 "Distance" 6066 "Distance" 6067 "Distance" 6068 "Distance" 6069 "Distance" 6070 "Distance" 6071 "Distance" 6072 "Distance" 6073 "Distance" 6074 "Distance" 6075 "Distance" 6076 "Distance" 6077 "Distance" 6078 "Distance" 6079 "Distance" 6080 "Distance" 6081 "Distance" 6082 "Distance" 6083 "Distance" 6084 "Distance" 6085 "Distance" 6086 "Distance" 6087 "Distance" 6088 "Distance" 6089 "Distance" 6090 "Distance" 6091 "Distance" 6092 "Distance" 6093 "Distance" 6094 "Distance" 6095 "Distance" 6096 "Distance" 6097 "Distance" 6098 "Distance" 6099 "Distance" 6100 "Distance" 6101 "Distance" 6102 "Distance" 6103 "Distance" 6104 "Distance" 6105 "Distance" 6106 "Distance" 6107 "Distance" 6108 "Distance" 6109 "Distance" 6110 "Distance" 6111 "Distance" 6112 "Distance" 6113 "Distance" 6114 "Distance" 6115 "Distance" 6116 "Distance" 6117 "Distance" 6118 "Distance" 6119 "Distance" 6120 "Distance" 6121 "Distance" 6122 "Distance" 6123 "Distance" 6124 "Distance" 6125 "Distance" 6126 "Distance" 6127 "Distance" 6128 "Distance" 6129 "Distance" 6130 "Distance" 6131 "Distance" 6132 "Distance" 6133 "Distance" 6134 "Distance" 6135 "Distance" 6136 "Distance" 6137 "Distance" 6138 "Distance" 6139 "Distance" 6140 "Distance" 6141 "Distance" 6142 "Distance" 6143 "Distance" 6144 "Distance" 6145 "Distance" 6146 "Distance" 6147 "Distance" 6148 "Distance" 6149 "Distance" 6150 "Distance" 6151 "Distance" 6152 "Distance" 6153 "Distance" 6154 "Distance" 6155 "Distance" 6156 "Distance" 6157 "Distance" 6158 "Distance" 6159 "Distance" 6160 "Distance" 6161 "Distance" 6162 "Distance" 6163 "Distance" 6164 "Distance" 6165 "Distance" 6166 "Distance" 6167 "Distance" 6168 "Distance" 6169 "Distance" 6170 "Distance" 6171 "Distance" 6172 "Distance" 6173 "Distance" 6174 "Distance" 6175 "Distance" 6176 "Distance" 6177 "Distance" 6178 "Distance" 6179 "Distance" 6180 "Distance" 6181 "Distance" 6182 "Distance" 6183 "Distance" 6184 "Distance" 6185 "Distance" 6186 "Distance" 6187 "Distance" 6188 "Distance" 6189 "Distance" 6190 "Distance" 6191 "Distance" 6192 "Distance" 6193 "Distance" 6194 "Distance" 6195 "Distance" 6196 "Distance" 6197 "Distance" 6198 "Distance" 6199 "Distance" 6200 "Distance" 6201 "Distance" 6202 "Distance" 6203 "Distance" 6204 "Distance" 6205 "Distance" 6206 "Distance" 6207 "Distance" 6208 "Distance" 6209 "Distance" 6210 "Distance" 6211 "Distance" 6212 "Distance" 6213 "Distance" 6214 "Distance" 6215 "Distance" 6216 "Distance" 6217 "Distance" 6218 "Distance" 6219 "Distance" 6220 "Distance" 6221 "Distance" 6222 "Distance" 6223 "Distance" 6224 "Distance" 6225 "Distance" 6226 "Distance" 6227 "Distance" 6228 "Distance" 6229 "Distance" 6230 "Distance" 6231 "Distance" 6232 "Distance" 6233 "Distance" 6234 "Distance" 6235 "Distance" 6236 "Distance" 6237 "Distance" 6238 "Distance" 6239 "Distance" 6240 "Distance" 6241 "Distance" 6242 "Distance" 6243 "Distance" 6244 "Distance" 6245 "Distance" 6246 "Distance" 6247 "Distance" 6248 "Distance" 6249 "Distance" 6250 "Distance" 6251 "Distance" 6252 "Distance" 6253 "Distance" 6254 "Distance" 6255 "Distance" 6256 "Distance" 6257 "Distance" 6258 "Distance" 6259 "Distance" 6260 "Distance" 6261 "Distance" 6262 "Distance" 6263 "Distance" 6264 "Distance" 6265 "Distance" 6266 "Distance" 6267 "Distance" 6268 "Distance" 6269 "Distance" 6270 "Distance" 6271 "Distance" 6272 "Distance" 6273 "Distance" 6274 "Distance" 6275 "Distance" 6276 "Distance" 6277 "Distance" 6278 "Distance" 6279 "Distance" 6280 "Distance" 6281 "Distance" 6282 "Distance" 6283 "Distance" 6284 "Distance" 6285 "Distance" 6286 "Distance" 6287 "Distance" 6288 "Distance" 6289 "Distance" 6290 "Distance" 6291 "Distance" 6292 "Distance" 6293 "Distance" 6294 "Distance" 6295 "Distance" 6296 "Distance" 6297 "Distance" 6298 "Distance" 6299 "Distance" 6300 "Distance" 6301 "Distance" 6302 "Distance" 6303 "Distance" 6304 "Distance" 6305 "Distance" 6306 "Distance" 6307 "Distance" 6308 "Distance" 6309 "Distance" 6310 "Distance" 6311 "Distance" 6312 "Distance" 6313 "Distance" 6314 "Distance" 6315 "Distance" 6316 "Distance" 6317 "Distance" 6318 "Distance" 6319 "Distance" 6320 "Distance" 6321 "Distance" 6322 "Distance" 6323 "Distance" 6324 "Distance" 6325 "Distance" 6326 "Distance" 6327 "Distance" 6328 "Distance" 6329 "Distance" 6330 "Distance" 6331 "Distance" 6332 "Distance" 6333 "Distance" 6334 "Distance" 6335 "Distance" 6336 "Distance" 6337 "Distance" 6338 "Distance" 6339 "Distance" 6340 "Distance" 6341 "Distance" 6342 "Distance" 6343 "Distance" 6344 "Distance" 6345 "Distance" 6346 "Distance" 6347 "Distance" 6348 "Distance" 6349 "Distance" 6350 "Distance" 6351 "Distance" 6352 "Distance" 6353 "Distance" 6354 "Distance" 6355 "Distance" 6356 "Distance" 6357 "Distance" 6358 "Distance" 6359 "Distance" 6360 "Distance" 6361 "Distance" 6362 "Distance" 6363 "Distance" 6364 "Distance" 6365 "Distance" 6366 "Distance" 6367 "Distance" 6368 "Distance" 6369 "Distance" 6370 "Distance" 6371 "Distance" 6372 "Distance" 6373 "Distance" 6374 "Distance" 6375 "Distance" 6376 "Distance" 6377 "Distance" 6378 "Distance" 6379 "Distance" 6380 "Distance" 6381 "Distance" 6382 "Distance" 6383 "Distance" 6384 "Distance" 6385 "Distance" 6386 "Distance" 6387 "Distance" 6388 "Distance" 6389 "Distance" 6390 "Distance" 6391 "Distance" 6392 "Distance" 6393 "Distance" 6394 "Distance" 6395 "Distance" 6396 "Distance" 6397 "Distance" 6398 "Distance" 6399 "Distance" 6400 "Distance" 6401 "Distance" 6402 "Distance" 6403 "Distance" 6404 "Distance" 6405 "Distance" 6406 "Distance" 6407 "Distance" 6408 "Distance" 6409 "Distance" 6410 "Distance" 6411 "Distance" 6412 "Distance" 6413 "Distance" 6414 "Distance" 6415 "Distance" 6416 "Distance" 6417 "Distance" 6418 "Distance" 6419 "Distance" 6420 "Distance" 6421 "Distance" 6422 "Distance" 6423 "Distance" 6424 "Distance" 6425 "Distance" 6426 "Distance" 6427 "Distance" 6428 "Distance" 6429 "Distance" 6430 "Distance" 6431 "Distance" 6432 "Distance" 6433 "Distance" 6434 "Distance" 6435 "Distance" 6436 "Distance" 6437 "Distance" 6438 "Distance" 6439 "Distance" 6440 "Distance" 6441 "Distance" 6442 "Distance" 6443 "Distance" 6444 "Distance" 6445 "Distance" 6446 "Distance" 6447 "Distance" 6448 "Distance" 6449 "Distance" 6450 "Distance" 6451 "Distance" 6452 "Distance" 6453 "Distance" 6454 "Distance" 6455 "Distance" 6456 "Distance" 6457 "Distance" 6458 "Distance" 6459 "Distance" 6460 "Distance" 6461 "Distance" 6462 "Distance" 6463 "Distance" 6464 "Distance" 6465 "Distance" 6466 "Distance" 6467 "Distance" 6468 "Distance" 6469 "Distance" 6470 "Distance" 6471 "Distance" 6472 "Distance" 6473 "Distance" 6474 "Distance" 6475 "Distance" 6476 "Distance" 6477 "Distance" 6478 "Distance" 6479 "Distance" 6480 "Distance" 6481 "Distance" 6482 "Distance" 6483 "Distance" 6484 "Distance" 6485 "Distance" 6486 "Distance" 6487 "Distance" 6488 "Distance" 6489 "Distance" 6490 "Distance" 6491 "Distance" 6492 "Distance" 6493 "Distance" 6494 "Distance" 6495 "Distance" 6496 "Distance" 6497 "Distance" 6498 "Distance" 6499 "Distance" 6500 "Distance" 6501 "Distance" 6502 "Distance" 6503 "Distance" 6504 "Distance" 6505 "Distance" 6506 "Distance" 6507 "Distance" 6508 "Distance" 6509 "Distance" 6510 "Distance" 6511 "Distance" 6512 "Distance" 6513 "Distance" 6514 "Distance" 6515 "Distance" 6516 "Distance" 6517 "Distance" 6518 "Distance" 6519 "Distance" 6520 "Distance" 6521 "Distance" 6522 "Distance" 6523 "Distance" 6524 "Distance" 6525 "Distance" 6526 "Distance" 6527 "Distance" 6528 "Distance" 6529 "Distance" 6530 "Distance" 6531 "Distance" 6532 "Distance" 6533 "Distance" 6534 "Distance" 6535 "Distance" 6536 "Distance" 6537 "Distance" 6538 "Distance" 6539 "Distance" 6540 "Distance" 6541 "Distance" 6542 "Distance" 6543 "Distance" 6544 "Distance" 6545 "Distance" 6546 "Distance" 6547 "Distance" 6548 "Distance" 6549 "Distance" 6550 "Distance" 6551 "Distance" 6552 "Distance" 6553 "Distance" 6554 "Distance" 6555 "Distance" 6556 "Distance" 6557 "Distance" 6558 "Distance" 6559 "Distance" 6560 "Distance" 6561 "Distance" 6562 "Distance" 6563 "Distance" 6564 "Distance" 6565 "Distance" 6566 "Distance" 6567 "Distance" 6568 "Distance" 6569 "Distance" 6570 "Distance" 6571 "Distance" 6572 "Distance" 6573 "Distance" 6574 "Distance" 6575 "Distance" 6576 "Distance" 6577 "Distance" 6578 "Distance" 6579 "Distance" 6580 "Distance" 6581 "Distance" 6582 "Distance" 6583 "Distance" 6584 "Distance" 6585 "Distance" 6586 "Distance" 6587 "Distance" 6588 "Distance" 6589 "Distance" 6590 "Distance" 6591 "Distance" 6592 "Distance" 6593 "Distance" 6594 "Distance" 6595 "Distance" 6596 "Distance" 6597 "Distance" 6598 "Distance" 6599 "Distance" 6600 "Distance" 6601 "Distance" 6602 "Distance" 6603 "Distance" 6604 "Distance" 6605 "Distance" 6606 "Distance" 6607 "Distance" 6608 "Distance" 6609 "Distance" 6610 "Distance" 6611 "Distance" 6612 "Distance" 6613 "Distance" 6614 "Distance" 6615 "Distance" 6616 "Distance" 6617 "Distance" 6618 "Distance" 6619 "Distance" 6620 "Distance" 6621 "Distance" 6622 "Distance" 6623 "Distance" 6624 "Distance" 6625 "Distance" 6626 "Distance" 6627 "Distance" 6628 "Distance" 6629 "Distance" 6630 "Distance" 6631 "Distance" 6632 "Distance" 6633 "Distance" 6634 "Distance" 6635 "Distance" 6636 "Distance" 6637 "Distance" 6638 "Distance" 6639 "Distance" 6640 "Distance" 6641 "Distance" 6642 "Distance" 6643 "Distance" 6644 "Distance" 6645 "Distance" 6646 "Distance" 6647 "Distance" 6648 "Distance" 6649 "Distance" 6650 "Distance" 6651 "Distance" 6652 "Distance" 6653 "Distance" 6654 "Distance" 6655 "Distance" 6656 "Distance" 6657 "Distance" 6658 "Distance" 6659 "Distance" 6660 "Distance" 6661 "Distance" 6662 "Distance" 6663 "Distance" 6664 "Distance" 6665 "Distance" 6666 "Distance" 6667 "Distance" 6668 "Distance" 6669 "Distance" 6670 "Distance" 6671 "Distance" 6672 "Distance" 6673 "Distance" 6674 "Distance" 6675 "Distance" 6676 "Distance" 6677 "Distance" 6678 "Distance" 6679 "Distance" 6680 "Distance" 6681 "Distance" 6682 "Distance" 6683 "Distance" 6684 "Distance" 6685 "Distance" 6686 "Distance" 6687 "Distance" 6688 "Distance" 6689 "Distance" 6690 "Distance" 6691 "Distance" 6692 "Distance" 6693 "Distance" 6694 "Distance" 6695 "Distance" 6696 "Distance" 6697 "Distance" 6698 "Distance" 6699 "Distance" 6700 "Distance" 6701 "Distance" 6702 "Distance" 6703 "Distance" 6704 "Distance" 6705 "Distance" 6706 "Distance" 6707 "Distance" 6708 "Distance" 6709 "Distance" 6710 "Distance" 6711 "Distance" 6712 "Distance" 6713 "Distance" 6714 "Distance" 6715 "Distance" 6716 "Distance" 6717 "Distance" 6718 "Distance" 6719 "Distance" 6720 "Distance" 6721 "Distance" 6722 "Distance" 6723 "Distance" 6724 "Distance" 6725 "Distance" 6726 "Distance" 6727 "Distance" 6728 "Distance" 6729 "Distance" 6730 "Distance" 6731 "Distance" 6732 "Distance" 6733 "Distance" 6734 "Distance" 6735 "Distance" 6736 "Distance" 6737 "Distance" 6738 "Distance" 6739 "Distance" 6740 "Distance" 6741 "Distance" 6742 "Distance" 6743 "Distance" 6744 "Distance" 6745 "Distance" 6746 "Distance" 6747 "Distance" 6748 "Distance" 6749 "Distance" 6750 "Distance" 6751 "Distance" 6752 "Distance" 6753 "Distance" 6754 "Distance" 6755 "Distance" 6756 "Distance" 6757 "Distance" 6758 "Distance" 6759 "Distance" 6760 "Distance" 6761 "Distance" 6762 "Distance" 6763 "Distance" 6764 "Distance" 6765 "Distance" 6766 "Distance" 6767 "Distance" 6768 "Distance" 6769 "Distance" 6770 "Distance" 6771 "Distance" 6772 "Distance" 6773 "Distance" 6774 "Distance" 6775 "Distance" 6776 "Distance" 6777 "Distance" 6778 "Distance" 6779 "Distance" 6780 "Distance" 6781 "Distance" 6782 "Distance" 6783 "Distance" 6784 "Distance" 6785 "Distance" 6786 "Distance" 6787 "Distance" 6788 "Distance" 6789 "Distance" 6790 "Distance" 6791 "Distance" 6792 "Distance" 6793 "Distance" 6794 "Distance" 6795 "Distance" 6796 "Distance" 6797 "Distance" 6798 "Distance" 6799 "Distance" 6800 "Distance" 6801 "Distance" 6802 "Distance" 6803 "Distance" 6804 "Distance" 6805 "Distance" 6806 "Distance" 6807 "Distance" 6808 "Distance" 6809 "Distance" 6810 "Distance" 6811 "Distance" 6812 "Distance" 6813 "Distance" 6814 "Distance" 6815 "Distance" 6816 "Distance" 6817 "Distance" 6818 "Distance" 6819 "Distance" 6820 "Distance" 6821 "Distance" 6822 "Distance" 6823 "Distance" 6824 "Distance" 6825 "Distance" 6826 "Distance" 6827 "Distance" 6828 "Distance" 6829 "Distance" 6830 "Distance" 6831 "Distance" 6832 "Distance" 6833 "Distance" 6834 "Distance" 6835 "Distance" 6836 "Distance" 6837 "Distance" 6838 "Distance" 6839 "Distance" 6840 "Distance" 6841 "Distance" 6842 "Distance" 6843 "Distance" 6844 "Distance" 6845 "Distance" 6846 "Distance" 6847 "Distance" 6848 "Distance" 6849 "Distance" 6850 "Distance" 6851 "Distance" 6852 "Distance" 6853 "Distance" 6854 "Distance" 6855 "Distance" 6856 "Distance" 6857 "Distance" 6858 "Distance" 6859 "Distance" 6860 "Distance" 6861 "Distance" 6862 "Distance" 6863 "Distance" 6864 "Distance" 6865 "Distance" 6866 "Distance" 6867 "Distance" 6868 "Distance" 6869 "Distance" 6870 "Distance" 6871 "Distance" 6872 "Distance" 6873 "Distance" 6874 "Distance" 6875 "Distance" 6876 "Distance" 6877 "Distance" 6878 "Distance" 6879 "Distance" 6880 "Distance" 6881 "Distance" 6882 "Distance" 6883 "Distance" 6884 "Distance" 6885 "Distance" 6886 "Distance" 6887 "Distance" 6888 "Distance" 6889 "Distance" 6890 "Distance" 6891 "Distance" 6892 "Distance" 6893 "Distance" 6894 "Distance" 6895 "Distance" 6896 "Distance" 6897 "Distance" 6898 "Distance" 6899 "Distance" 6900 "Distance" 6901 "Distance" 6902 "Distance" 6903 "Distance" 6904 "Distance" 6905 "Distance" 6906 "Distance" 6907 "Distance" 6908 "Distance" 6909 "Distance" 6910 "Distance" 6911 "Distance" 6912 "Distance" 6913 "Distance" 6914 "Distance" 6915 "Distance" 6916 "Distance" 6917 "Distance" 6918 "Distance" 6919 "Distance" 6920 "Distance" 6921 "Distance" 6922 "Distance" 6923 "Distance" 6924 "Distance" 6925 "Distance" 6926 "Distance" 6927 "Distance" 6928 "Distance" 6929 "Distance" 6930 "Distance" 6931 "Distance" 6932 "Distance" 6933 "Distance" 6934 "Distance" 6935 "Distance" 6936 "Distance" 6937 "Distance" 6938 "Distance" 6939 "Distance" 6940 "Distance" 6941 "Distance" 6942 "Distance" 6943 "Distance" 6944 "Distance" 6945 "Distance" 6946 "Distance" 6947 "Distance" 6948 "Distance" 6949 "Distance" 6950 "Distance" 6951 "Distance" 6952 "Distance" 6953 "Distance" 6954 "Distance" 6955 "Distance" 6956 "Distance" 6957 "Distance" 6958 "Distance" 6959 "Distance" 6960 "Distance" 6961 "Distance" 6962 "Distance" 6963 "Distance" 6964 "Distance" 6965 "Distance" 6966 "Distance" 6967 "Distance" 6968 "Distance" 6969 "Distance" 6970 "Distance" 6971 "Distance" 6972 "Distance" 6973 "Distance" 6974 "Distance" 6975 "Distance" 6976 "Distance" 6977 "Distance" 6978 "Distance" 6979 "Distance" 6980 "Distance" 6981 "Distance" 6982 "Distance" 6983 "Distance" 6984 "Distance" 6985 "Distance" 6986 "Distance" 6987 "Distance" 6988 "Distance" 6989 "Distance" 6990 "Distance" 6991 "Distance" 6992 "Distance" 6993 "Distance" 6994 "Distance" 6995 "Distance" 6996 "Distance" 6997 "Distance" 6998 "Distance" 6999 "Distance" 7000 "Distance" 7001 "Distance" 7002 "Distance" 7003 "Distance" 7004 "Distance" 7005 "Distance" 7006 "Distance" 7007 "Distance" 7008 "Distance" 7009 "Distance" 7010 "Distance" 7011 "Distance" 7012 "Distance" 7013 "Distance" 7014 "Distance" 7015 "Distance" 7016 "Distance" 7017 "Distance" 7018 "Distance" 7019 "Distance" 7020 "Distance" 7021 "Distance" 7022 "Distance" 7023 "Distance" 7024 "Distance" 7025 "Distance" 7026 "Distance" 7027 "Distance" 7028 "Distance" 7029 "Distance" 7030 "Distance" 7031 "Distance" 7032 "Distance" 7033 "Distance" 7034 "Distance" 7035 "Distance" 7036 "Distance" 7037 "Distance" 7038 "Distance" 7039 "Distance" 7040 "Distance" 7041 "Distance" 7042 "Distance" 7043 "Distance" 7044 "Distance" 7045 "Distance" 7046 "Distance" 7047 "Distance" 7048 "Distance" 7049 "Distance" 7050 "Distance" 7051 "Distance" 7052 "Distance" 7053 "Distance" 7054 "Distance" 7055 "Distance" 7056 "Distance" 7057 "Distance" 7058 "Distance" 7059 "Distance" 7060 "Distance" 7061 "Distance" 7062 "Distance" 7063 "Distance" 7064 "Distance" 7065 "Distance" 7066 "Distance" 7067 "Distance" 7068 "Distance" 7069 "Distance" 7070 "Distance" 7071 "Distance" 7072 "Distance" 7073 "Distance" 7074 "Distance" 7075 "Distance" 7076 "Distance" 7077 "Distance" 7078 "Distance" 7079 "Distance" 7080 "Distance" 7081 "Distance" 7082 "Distance" 7083 "Distance" 7084 "Distance" 7085 "Distance" 7086 "Distance" 7087 "Distance" 7088 "Distance" 7089 "Distance" 7090 "Distance" 7091 "Distance" 7092 "Distance" 7093 "Distance" 7094 "Distance" 7095 "Distance" 7096 "Distance" 7097 "Distance" 7098 "Distance" 7099 "Distance" 7100 "Distance" 7101 "Distance" 7102 "Distance" 7103 "Distance" 7104 "Distance" 7105 "Distance" 7106 "Distance" 7107 "Distance" 7108 "Distance" 7109 "Distance" 7110 "Distance" 7111 "Distance" 7112 "Distance" 7113 "Distance" 7114 "Distance" 7115 "Distance" 7116 "Distance" 7117 "Distance" 7118 "Distance" 7119 "Distance" 7120 "Distance" 7121 "Distance" 7122 "Distance" 7123 "Distance" 7124 "Distance" 7125 "Distance" 7126 "Distance" 7127 "Distance" 7128 "Distance" 7129 "Distance" 7130 "Distance" 7131 "Distance" 7132 "Distance" 7133 "Distance" 7134 "Distance" 7135 "Distance" 7136 "Distance" 7137 "Distance" 7138 "Distance" 7139 "Distance" 7140 "Distance" 7141 "Distance" 7142 "Distance" 7143 "Distance" 7144 "Distance" 7145 "Distance" 7146 "Distance" 7147 "Distance" 7148 "Distance" 7149 "Distance" 7150 "Distance" 7151 "Distance" 7152 "Distance" 7153 "Distance" 7154 "Distance" 7155 "Distance" 7156 "Distance" 7157 "Distance" 7158 "Distance" 7159 "Distance" 7160 "Distance" 7161 "Distance" 7162 "Distance" 7163 "Distance" 7164 "Distance" 7165 "Distance" 7166 "Distance" 7167 "Distance" 7168 "Distance" 7169 "Distance" 7170 "Distance" 7171 "Distance" 7172 "Distance" 7173 "Distance" 7174 "Distance" 7175 "Distance" 7176 "Distance" 7177 "Distance" 7178 "Distance" 7179 "Distance" 7180 "Distance" 7181 "Distance" 7182 "Distance" 7183 "Distance" 7184 "Distance" 7185 "Distance" 7186 "Distance" 7187 "Distance" 7188 "Distance" 7189 "Distance" 7190 "Distance" 7191 "Distance" 7192 "Distance" 7193 "Distance" 7194 "Distance" 7195 "Distance" 7196 "Distance" 7197 "Distance" 7198 "Distance" 7199 "Distance" 7200 "Distance" 7201 "Distance" 7202 "Distance" 7203 "Distance" 7204 "Distance" 7205 "Distance" 7206 "Distance" 7207 "Distance" 7208 "Distance" 7209 "Distance" 7210 "Distance" 7211 "Distance" 7212 "Distance" 7213 "Distance" 7214 "Distance" 7215 "Distance" 7216 "Distance" 7217 "Distance" 7218 "Distance" 7219 "Distance" 7220 "Distance" 7221 "Distance" 7222 "Distance" 7223 "Distance" 7224 "Distance" 7225 "Distance" 7226 "Distance" 7227 "Distance" 7228 "Distance" 7229 "Distance" 7230 "Distance" 7231 "Distance" 7232 "Distance" 7233 "Distance" 7234 "Distance" 7235 "Distance" 7236 "Distance" 7237 "Distance" 7238 "Distance" 7239 "Distance" 7240 "Distance" 7241 "Distance" 7242 "Distance" 7243 "Distance" 7244 "Distance" 7245 "Distance" 7246 "Distance" 7247 "Distance" 7248 "Distance" 7249 "Distance" 7250 "Distance" 7251 "Distance" 7252 "Distance" 7253 "Distance" 7254 "Distance" 7255 "Distance" 7256 "Distance" 7257 "Distance" 7258 "Distance" 7259 "Distance" 7260 "Distance" 7261 "Distance" 7262 "Distance" 7263 "Distance" 7264 "Distance" 7265 "Distance" 7266 "Distance" 7267 "Distance" 7268 "Distance" 7269 "Distance" 7270 "Distance" 7271 "Distance" 7272 "Distance" 7273 "Distance" 7274 "Distance" 7275 "Distance" 7276 "Distance" 7277 "Distance" 7278 "Distance" 7279 "Distance" 7280 "Distance" 7281 "Distance" 7282 "Distance" 7283 "Distance" 7284 "Distance" 7285 "Distance" 7286 "Distance" 7287 "Distance" 7288 "Distance" 7289 "Distance" 7290 "Distance" 7291 "Distance" 7292 "Distance" 7293 "Distance" 7294 "Distance" 7295 "Distance" 7296 "Distance" 7297 "Distance" 7298 "Distance" 7299 "Distance" 7300 "Distance" 7301 "Distance" 7302 "Distance" 7303 "Distance" 7304 "Distance" 7305 "Distance" 7306 "Distance" 7307 "Distance" 7308 "Distance" 7309 "Distance" 7310 "Distance" 7311 "Distance" 7312 "Distance" 7313 "Distance" 7314 "Distance" 7315 "Distance" 7316 "Distance" 7317 "Distance" 7318 "Distance" 7319 "Distance" 7320 "Distance" 7321 "Distance" 7322 "Distance" 7323 "Distance" 7324 "Distance" 7325 "Distance" 7326 "Distance" 7327 "Distance" 7328 "Distance" 7329 "Distance" 7330 "Distance" 7331 "Distance" 7332 "Distance" 7333 "Distance" 7334 "Distance" 7335 "Distance" 7336 "Distance" 7337 "Distance" 7338 "Distance" 7339 "Distance" 7340 "Distance" 7341 "Distance" 7342 "Distance" 7343 "Distance" 7344 "Distance" 7345 "Distance" 7346 "Distance" 7347 "Distance" 7348 "Distance" 7349 "Distance" 7350 "Distance" 7351 "Distance" 7352 "Distance" 7353 "Distance" 7354 "Distance" 7355 "Distance" 7356 "Distance" 7357 "Distance" 7358 "Distance" 7359 "Distance" 7360 "Distance" 7361 "Distance" 7362 "Distance" 7363 "Distance" 7364 "Distance" 7365 "Distance" 7366 "Distance" 7367 "Distance" 7368 "Distance" 7369 "Distance" 7370 "Distance" 7371 "Distance" 7372 "Distance" 7373 "Distance" 7374 "Distance" 7375 "Distance" 7376 "Distance" 7377 "Distance" 7378 "Distance" 7379 "Distance" 7380 "Distance" 7381 "Distance" 7382 "Distance" 7383 "Distance" 7384 "Distance" 7385 "Distance" 7386 "Distance" 7387 "Distance" 7388 "Distance" 7389 "Distance" 7390 "Distance" 7391 "Distance" 7392 "Distance" 7393 "Distance" 7394 "Distance" 7395 "Distance" 7396 "Distance" 7397 "Distance" 7398 "Distance" 7399 "Distance" 7400 "Distance" 7401 "Distance" 7402 "Distance" 7403 "Distance" 7404 "Distance" 7405 "Distance" 7406 "Distance" 7407 "Distance" 7408 "Distance" 7409 "Distance" 7410 "Distance" 7411 "Distance" 7412 "Distance" 7413 "Distance" 7414 "Distance" 7415 "Distance" 7416 "Distance" 7417 "Distance" 7418 "Distance" 7419 "Distance" 7420 "Distance" 7421 "Distance" 7422 "Distance" 7423 "Distance" 7424 "Distance" 7425 "Distance" 7426 "Distance" 7427 "Distance" 7428 "Distance" 7429 "Distance" 7430 "Distance" 7431 "Distance" 7432 "Distance" 7433 "Distance" 7434 "Distance" 7435 "Distance" 7436 "Distance" 7437 "Distance" 7438 "Distance" 7439 "Distance" 7440 "Distance" 7441 "Distance" 7442 "Distance" 7443 "Distance" 7444 "Distance" 7445 "Distance" 7446 "Distance" 7447 "Distance" 7448 "Distance" 7449 "Distance" 7450 "Distance" 7451 "Distance" 7452 "Distance" 7453 "Distance" 7454 "Distance" 7455 "Distance" 7456 "Distance" 7457 "Distance" 7458 "Distance" 7459 "Distance" 7460 "Distance" 7461 "Distance" 7462 "Distance" 7463 "Distance" 7464 "Distance" 7465 "Distance" 7466 "Distance" 7467 "Distance" 7468 "Distance" 7469 "Distance" 7470 "Distance" 7471 "Distance" 7472 "Distance" 7473 "Distance" 7474 "Distance" 7475 "Distance" 7476 "Distance" 7477 "Distance" 7478 "Distance" 7479 "Distance" 7480 "Distance" 7481 "Distance" 7482 "Distance" 7483 "Distance" 7484 "Distance" 7485 "Distance" 7486 "Distance" 7487 "Distance" 7488 "Distance" 7489 "Distance" 7490 "Distance" 7491 "Distance" 7492 "Distance" 7493 "Distance" 7494 "Distance" 7495 "Distance" 7496 "Distance" 7497 "Distance" 7498 "Distance" 7499 "Distance" 7500 "Distance" 7501 "Distance" 7502 "Distance" 7503 "Distance" 7504 "Distance" 7505 "Distance" 7506 "Distance" 7507 "Distance" 7508 "Distance" 7509 "Distance" 7510 "Distance" 7511 "Distance" 7512 "Distance" 7513 "Distance" 7514 "Distance" 7515 "Distance" 7516 "Distance" 7517 "Distance" 7518 "Distance" 7519 "Distance" 7520 "Distance" 7521 "Distance" 7522 "Distance" 7523 "Distance" 7524 "Distance" 7525 "Distance" 7526 "Distance" 7527 "Distance" 7528 "Distance" 7529 "Distance" 7530 "Distance" 7531 "Distance" 7532 "Distance" 7533 "Distance" 7534 "Distance" 7535 "Distance" 7536 "Distance" 7537 "Distance" 7538 "Distance" 7539 "Distance" 7540 "Distance" 7541 "Distance" 7542 "Distance" 7543 "Distance" 7544 "Distance" 7545 "Distance" 7546 "Distance" 7547 "Distance" 7548 "Distance" 7549 "Distance" 7550 "Distance" 7551 "Distance" 7552 "Distance" 7553 "Distance" 7554 "Distance" 7555 "Distance" 7556 "Distance" 7557 "Distance" 7558 "Distance" 7559 "Distance" 7560 "Distance" 7561 "Distance" 7562 "Distance" 7563 "Distance" 7564 "Distance" 7565 "Distance" 7566 "Distance" 7567 "Distance" 7568 "Distance" 7569 "Distance" 7570 "Distance" 7571 "Distance" 7572 "Distance" 7573 "Distance" 7574 "Distance" 7575 "Distance" 7576 "Distance" 7577 "Distance" 7578 "Distance" 7579 "Distance" 7580 "Distance" 7581 "Distance" 7582 "Distance" 7583 "Distance" 7584 "Distance" 7585 "Distance" 7586 "Distance" 7587 "Distance" 7588 "Distance" 7589 "Distance" 7590 "Distance" 7591 "Distance" 7592 "Distance" 7593 "Distance" 7594 "Distance" 7595 "Distance" 7596 "Distance" 7597 "Distance" 7598 "Distance" 7599 "Distance" 7600 "Distance" 7601 "Distance" 7602 "Distance" 7603 "Distance" 7604 "Distance" 7605 "Distance" 7606 "Distance" 7607 "Distance" 7608 "Distance" 7609 "Distance" 7610 "Distance" 7611 "Distance" 7612 "Distance" 7613 "Distance" 7614 "Distance" 7615 "Distance" 7616 "Distance" 7617 "Distance" 7618 "Distance" 7619 "Distance" 7620 "Distance" 7621 "Distance" 7622 "Distance" 7623 "Distance" 7624 "Distance" 7625 "Distance" 7626 "Distance" 7627 "Distance" 7628 "Distance" 7629 "Distance" 7630 "Distance" 7631 "Distance" 7632 "Distance" 7633 "Distance" 7634 "Distance" 7635 "Distance" 7636 "Distance" 7637 "Distance" 7638 "Distance" 7639 "Distance" 7640 "Distance" 7641 "Distance" 7642 "Distance" 7643 "Distance" 7644 "Distance" 7645 "Distance" 7646 "Distance" 7647 "Distance" 7648 "Distance" 7649 "Distance" 7650 "Distance" 7651 "Distance" 7652 "Distance" 7653 "Distance" 7654 "Distance" 7655 "Distance" 7656 "Distance" 7657 "Distance" 7658 "Distance" 7659 "Distance" 7660 "Distance" 7661 "Distance" 7662 "Distance" 7663 "Distance" 7664 "Distance" 7665 "Distance" 7666 "Distance" 7667 "Distance" 7668 "Distance" 7669 "Distance" 7670 "Distance" 7671 "Distance" 7672 "Distance" 7673 "Distance" 7674 "Distance" 7675 "Distance" 7676 "Distance" 7677 "Distance" 7678 "Distance" 7679 "Distance" 7680 "Distance" 7681 "Distance" 7682 "Distance" 7683 "Distance" 7684 "Distance" 7685 "Distance" 7686 "Distance" 7687 "Distance" 7688 "Distance" 7689 "Distance" 7690 "Distance" 7691 "Distance" 7692 "Distance" 7693 "Distance" 7694 "Distance" 7695 "Distance" 7696 "Distance" 7697 "Distance" 7698 "Distance" 7699 "Distance" 7700 "Distance" 7701 "Distance" 7702 "Distance" 7703 "Distance" 7704 "Distance" 7705 "Distance" 7706 "Distance" 7707 "Distance" 7708 "Distance" 7709 "Distance" 7710 "Distance" 7711 "Distance" 7712 "Distance" 7713 "Distance" 7714 "Distance" 7715 "Distance" 7716 "Distance" 7717 "Distance" 7718 "Distance" 7719 "Distance" 7720 "Distance" 7721 "Distance" 7722 "Distance" 7723 "Distance" 7724 "Distance" 7725 "Distance" 7726 "Distance" 7727 "Distance" 7728 "Distance" 7729 "Distance" 7730 "Distance" 7731 "Distance" 7732 "Distance" 7733 "Distance" 7734 "Distance" 7735 "Distance" 7736 "Distance" 7737 "Distance" 7738 "Distance" 7739 "Distance" 7740 "Distance" 7741 "Distance" 7742 "Distance" 7743 "Distance" 7744 "Distance" 7745 "Distance" 7746 "Distance" 7747 "Distance" 7748 "Distance" 7749 "Distance" 7750 "Distance" 7751 "Distance" 7752 "Distance" 7753 "Distance" 7754 "Distance" 7755 "Distance" 7756 "Distance" 7757 "Distance" 7758 "Distance" 7759 "Distance" 7760 "Distance" 7761 "Distance" 7762 "Distance" 7763 "Distance" 7764 "Distance" 7765 "Distance" 7766 "Distance" 7767 "Distance" 7768 "Distance" 7769 "Distance" 7770 "Distance" 7771 "Distance" 7772 "Distance" 7773 "Distance" 7774 "Distance" 7775 "Distance" 7776 "Distance" 7777 "Distance" 7778 "Distance" 7779 "Distance" 7780 "Distance" 7781 "Distance" 7782 "Distance" 7783 "Distance" 7784 "Distance" 7785 "Distance" 7786 "Distance" 7787 "Distance" 7788 "Distance" 7789 "Distance" 7790 "Distance" 7791 "Distance" 7792 "Distance" 7793 "Distance" 7794 "Distance" 7795 "Distance" 7796 "Distance" 7797 "Distance" 7798 "Distance" 7799 "Distance" 7800 "Distance" 7801 "Distance" 7802 "Distance" 7803 "Distance" 7804 "Distance" 7805 "Distance" 7806 "Distance" 7807 "Distance" 7808 "Distance" 7809 "Distance" 7810 "Distance" 7811 "Distance" 7812 "Distance" 7813 "Distance" 7814 "Distance" 7815 "Distance" 7816 "Distance" 7817 "Distance" 7818 "Distance" 7819 "Distance" 7820 "Distance" 7821 "Distance" 7822 "Distance" 7823 "Distance" 7824 "Distance" 7825 "Distance" 7826 "Distance" 7827 "Distance" 7828 "Distance" 7829 "Distance" 7830 "Distance" 7831 "Distance" 7832 "Distance" 7833 "Distance" 7834 "Distance" 7835 "Distance" 7836 "Distance" 7837 "Distance" 7838 "Distance" 7839 "Distance" 7840 "Distance" 7841 "Distance" 7842 "Distance" 7843 "Distance" 7844 "Distance" 7845 "Distance" 7846 "Distance" 7847 "Distance" 7848 "Distance" 7849 "Distance" 7850 "Distance" 7851 "Distance" 7852 "Distance" 7853 "Distance" 7854 "Distance" 7855 "Distance" 7856 "Distance" 7857 "Distance" 7858 "Distance" 7859 "Distance" 7860 "Distance" 7861 "Distance" 7862 "Distance" 7863 "Distance" 7864 "Distance" 7865 "Distance" 7866 "Distance" 7867 "Distance" 7868 "Distance" 7869 "Distance" 7870 "Distance" 7871 "Distance" 7872 "Distance" 7873 "Distance" 7874 "Distance" 7875 "Distance" 7876 "Distance" 7877 "Distance" 7878 "Distance" 7879 "Distance" 7880 "Distance" 7881 "Distance" 7882 "Distance" 7883 "Distance" 7884 "Distance" 7885 "Distance" 7886 "Distance" 7887 "Distance" 7888 "Distance" 7889 "Distance" 7890 "Distance" 7891 "Distance" 7892 "Distance" 7893 "Distance" 7894 "Distance" 7895 "Distance" 7896 "Distance" 7897 "Distance" 7898 "Distance" 7899 "Distance" 7900 "Distance" 7901 "Distance" 7902 "Distance" 7903 "Distance" 7904 "Distance" 7905 "Distance" 7906 "Distance" 7907 "Distance" 7908 "Distance" 7909 "Distance" 7910 "Distance" 7911 "Distance" 7912 "Distance" 7913 "Distance" 7914 "Distance" 7915 "Distance" 7916 "Distance" 7917 "Distance" 7918 "Distance" 7919 "Distance" 7920 "Distance" 7921 "Distance" 7922 "Distance" 7923 "Distance" 7924 "Distance" 7925 "Distance" 7926 "Distance" 7927 "Distance" 7928 "Distance" 7929 "Distance" 7930 "Distance" 7931 "Distance" 7932 "Distance" 7933 "Distance" 7934 "Distance" 7935 "Distance" 7936 "Distance" 7937 "Distance" 7938 "Distance" 7939 "Distance" 7940 "Distance" 7941 "Distance" 7942 "Distance" 7943 "Distance" 7944 "Distance" 7945 "Distance" 7946 "Distance" 7947 "Distance" 7948 "Distance" 7949 "Distance" 7950 "Distance" 7951 "Distance" 7952 "Distance" 7953 "Distance" 7954 "Distance" 7955 "Distance" 7956 "Distance" 7957 "Distance" 7958 "Distance" 7959 "Distance" 7960 "Distance" 7961 "Distance" 7962 "Distance" 7963 "Distance" 7964 "Distance" 7965 "Distance" 7966 "Distance" 7967 "Distance" 7968 "Distance" 7969 "Distance" 7970 "Distance" 7971 "Distance" 7972 "Distance" 7973 "Distance" 7974 "Distance" 7975 "Distance" 7976 "Distance" 7977 "Distance" 7978 "Distance" 7979 "Distance" 7980 "Distance" 7981 "Distance" 7982 "Distance" 7983 "Distance" 7984 "Distance" 7985 "Distance" 7986 "Distance" 7987 "Distance" 7988 "Distance" 7989 "Distance" 7990 "Distance" 7991 "Distance" 7992 "Distance" 7993 "Distance" 7994 "Distance" 7995 "Distance" 7996 "Distance" 7997 "Distance" 7998 "Distance" 7999 "Distance" 8000 "Distance" 8001 "Distance" 8002 "Distance" 8003 "Distance" 8004 "Distance" 8005 "Distance" 8006 "Distance" 8007 "Distance" 8008 "Distance" 8009 "Distance" 8010 "Distance" 8011 "Distance" 8012 "Distance" 8013 "Distance" 8014 "Distance" 8015 "Distance" 8016 "Distance" 8017 "Distance" 8018 "Distance" 8019 "Distance" 8020 "Distance" 8021 "Distance" 8022 "Distance" 8023 "Distance" 8024 "Distance" 8025 "Distance" 8026 "Distance" 8027 "Distance" 8028 "Distance" 8029 "Distance" 8030 "Distance" 8031 "Distance" 8032 "Distance" 8033 "Distance" 8034 "Distance" 8035 "Distance" 8036 "Distance" 8037 "Distance" 8038 "Distance" 8039 "Distance" 8040 "Distance" 8041 "Distance" 8042 "Distance" 8043 "Distance" 8044 "Distance" 8045 "Distance" 8046 "Distance" 8047 "Distance" 8048 "Distance" 8049 "Distance" 8050 "Distance" 8051 "Distance" 8052 "Distance" 8053 "Distance" 8054 "Distance" 8055 "Distance" 8056 "Distance" 8057 "Distance" 8058 "Distance" 8059 "Distance" 8060 "Distance" 8061 "Distance" 8062 "Distance" 8063 "Distance" 8064 "Distance" 8065 "Distance" 8066 "Distance" 8067 "Distance" 8068 "Distance" 8069 "Distance" 8070 "Distance" 8071 "Distance" 8072 "Distance" 8073 "Distance" 8074 "Distance" 8075 "Distance" 8076 "Distance" 8077 "Distance" 8078 "Distance" 8079 "Distance" 8080 "Distance" 8081 "Distance" 8082 "Distance" 8083 "Distance" 8084 "Distance" 8085 "Distance" 8086 "Distance" 8087 "Distance" 8088 "Distance" 8089 "Distance" 8090 "Distance" 8091 "Distance" 8092 "Distance" 8093 "Distance" 8094 "Distance" 8095 "Distance" 8096 "Distance" 8097 "Distance" 8098 "Distance" 8099 "Distance" 8100 "Distance" 8101 "Distance" 8102 "Distance" 8103 "Distance" 8104 "Distance" 8105 "Distance" 8106 "Distance" 8107 "Distance" 8108 "Distance" 8109 "Distance" 8110 "Distance" 8111 "Distance" 8112 "Distance" 8113 "Distance" 8114 "Distance" 8115 "Distance" 8116 "Distance" 8117 "Distance" 8118 "Distance" 8119 "Distance" 8120 "Distance" 8121 "Distance" 8122 "Distance" 8123 "Distance" 8124 "Distance" 8125 "Distance" 8126 "Distance" 8127 "Distance" 8128 "Distance" 8129 "Distance" 8130 "Distance" 8131 "Distance" 8132 "Distance" 8133 "Distance" 8134 "Distance" 8135 "Distance" 8136 "Distance" 8137 "Distance" 8138 "Distance" 8139 "Distance" 8140 "Distance" 8141 "Distance" 8142 "Distance" 8143 "Distance" 8144 "Distance" 8145 "Distance" 8146 "Distance" 8147 "Distance" 8148 "Distance" 8149 "Distance" 8150 "Distance" 8151 "Distance" 8152 "Distance" 8153 "Distance" 8154 "Distance" 8155 "Distance" 8156 "Distance" 8157 "Distance" 8158 "Distance" 8159 "Distance" 8160 "Distance" 8161 "Distance" 8162 "Distance" 8163 "Distance" 8164 "Distance" 8165 "Distance" 8166 "Distance" 8167 "Distance" 8168 "Distance" 8169 "Distance" 8170 "Distance" 8171 "Distance" 8172 "Distance" 8173 "Distance" 8174 "Distance" 8175 "Distance" 8176 "Distance" 8177 "Distance" 8178 "Distance" 8179 "Distance" 8180 "Distance" 8181 "Distance" 8182 "Distance" 8183 "Distance" 8184 "Distance" 8185 "Distance" 8186 "Distance" 8187 "Distance" 8188 "Distance" 8189 "Distance" 8190 "Distance" 8191 "Invalid" ;
VAL_ 1207 PROSHORT_V2_Distance 0 "Distance" 1 "Distance" 2 "Distance" 3 "Distance" 4 "Distance" 5 "Distance" 6 "Distance" 7 "Distance" 8 "Distance" 9 "Distance" 10 "Distance" 11 "Distance" 12 "Distance" 13 "Distance" 14 "Distance" 15 "Distance" 16 "Distance" 17 "Distance" 18 "Distance" 19 "Distance" 20 "Distance" 21 "Distance" 22 "Distance" 23 "Distance" 24 "Distance" 25 "Distance" 26 "Distance" 27 "Distance" 28 "Distance" 29 "Distance" 30 "Distance" 31 "Distance" 32 "Distance" 33 "Distance" 34 "Distance" 35 "Distance" 36 "Distance" 37 "Distance" 38 "Distance" 39 "Distance" 40 "Distance" 41 "Distance" 42 "Distance" 43 "Distance" 44 "Distance" 45 "Distance" 46 "Distance" 47 "Distance" 48 "Distance" 49 "Distance" 50 "Distance" 51 "Distance" 52 "Distance" 53 "Distance" 54 "Distance" 55 "Distance" 56 "Distance" 57 "Distance" 58 "Distance" 59 "Distance" 60 "Distance" 61 "Distance" 62 "Distance" 63 "Distance" 64 "Distance" 65 "Distance" 66 "Distance" 67 "Distance" 68 "Distance" 69 "Distance" 70 "Distance" 71 "Distance" 72 "Distance" 73 "Distance" 74 "Distance" 75 "Distance" 76 "Distance" 77 "Distance" 78 "Distance" 79 "Distance" 80 "Distance" 81 "Distance" 82 "Distance" 83 "Distance" 84 "Distance" 85 "Distance" 86 "Distance" 87 "Distance" 88 "Distance" 89 "Distance" 90 "Distance" 91 "Distance" 92 "Distance" 93 "Distance" 94 "Distance" 95 "Distance" 96 "Distance" 97 "Distance" 98 "Distance" 99 "Distance" 100 "Distance" 101 "Distance" 102 "Distance" 103 "Distance" 104 "Distance" 105 "Distance" 106 "Distance" 107 "Distance" 108 "Distance" 109 "Distance" 110 "Distance" 111 "Distance" 112 "Distance" 113 "Distance" 114 "Distance" 115 "Distance" 116 "Distance" 117 "Distance" 118 "Distance" 119 "Distance" 120 "Distance" 121 "Distance" 122 "Distance" 123 "Distance" 124 "Distance" 125 "Distance" 126 "Distance" 127 "Distance" 128 "Distance" 129 "Distance" 130 "Distance" 131 "Distance" 132 "Distance" 133 "Distance" 134 "Distance" 135 "Distance" 136 "Distance" 137 "Distance" 138 "Distance" 139 "Distance" 140 "Distance" 141 "Distance" 142 "Distance" 143 "Distance" 144 "Distance" 145 "Distance" 146 "Distance" 147 "Distance" 148 "Distance" 149 "Distance" 150 "Distance" 151 "Distance" 152 "Distance" 153 "Distance" 154 "Distance" 155 "Distance" 156 "Distance" 157 "Distance" 158 "Distance" 159 "Distance" 160 "Distance" 161 "Distance" 162 "Distance" 163 "Distance" 164 "Distance" 165 "Distance" 166 "Distance" 167 "Distance" 168 "Distance" 169 "Distance" 170 "Distance" 171 "Distance" 172 "Distance" 173 "Distance" 174 "Distance" 175 "Distance" 176 "Distance" 177 "Distance" 178 "Distance" 179 "Distance" 180 "Distance" 181 "Distance" 182 "Distance" 183 "Distance" 184 "Distance" 185 "Distance" 186 "Distance" 187 "Distance" 188 "Distance" 189 "Distance" 190 "Distance" 191 "Distance" 192 "Distance" 193 "Distance" 194 "Distance" 195 "Distance" 196 "Distance" 197 "Distance" 198 "Distance" 199 "Distance" 200 "Distance" 201 "Distance" 202 "Distance" 203 "Distance" 204 "Distance" 205 "Distance" 206 "Distance" 207 "Distance" 208 "Distance" 209 "Distance" 210 "Distance" 211 "Distance" 212 "Distance" 213 "Distance" 214 "Distance" 215 "Distance" 216 "Distance" 217 "Distance" 218 "Distance" 219 "Distance" 220 "Distance" 221 "Distance" 222 "Distance" 223 "Distance" 224 "Distance" 225 "Distance" 226 "Distance" 227 "Distance" 228 "Distance" 229 "Distance" 230 "Distance" 231 "Distance" 232 "Distance" 233 "Distance" 234 "Distance" 235 "Distance" 236 "Distance" 237 "Distance" 238 "Distance" 239 "Distance" 240 "Distance" 241 "Distance" 242 "Distance" 243 "Distance" 244 "Distance" 245 "Distance" 246 "Distance" 247 "Distance" 248 "Distance" 249 "Distance" 250 "Distance" 251 "Distance" 252 "Distance" 253 "Distance" 254 "Distance" 255 "Distance" 256 "Distance" 257 "Distance" 258 "Distance" 259 "Distance" 260 "Distance" 261 "Distance" 262 "Distance" 263 "Distance" 264 "Distance" 265 "Distance" 266 "Distance" 267 "Distance" 268 "Distance" 269 "Distance" 270 "Distance" 271 "Distance" 272 "Distance" 273 "Distance" 274 "Distance" 275 "Distance" 276 "Distance" 277 "Distance" 278 "Distance" 279 "Distance" 280 "Distance" 281 "Distance" 282 "Distance" 283 "Distance" 284 "Distance" 285 "Distance" 286 "Distance" 287 "Distance" 288 "Distance" 289 "Distance" 290 "Distance" 291 "Distance" 292 "Distance" 293 "Distance" 294 "Distance" 295 "Distance" 296 "Distance" 297 "Distance" 298 "Distance" 299 "Distance" 300 "Distance" 301 "Distance" 302 "Distance" 303 "Distance" 304 "Distance" 305 "Distance" 306 "Distance" 307 "Distance" 308 "Distance" 309 "Distance" 310 "Distance" 311 "Distance" 312 "Distance" 313 "Distance" 314 "Distance" 315 "Distance" 316 "Distance" 317 "Distance" 318 "Distance" 319 "Distance" 320 "Distance" 321 "Distance" 322 "Distance" 323 "Distance" 324 "Distance" 325 "Distance" 326 "Distance" 327 "Distance" 328 "Distance" 329 "Distance" 330 "Distance" 331 "Distance" 332 "Distance" 333 "Distance" 334 "Distance" 335 "Distance" 336 "Distance" 337 "Distance" 338 "Distance" 339 "Distance" 340 "Distance" 341 "Distance" 342 "Distance" 343 "Distance" 344 "Distance" 345 "Distance" 346 "Distance" 347 "Distance" 348 "Distance" 349 "Distance" 350 "Distance" 351 "Distance" 352 "Distance" 353 "Distance" 354 "Distance" 355 "Distance" 356 "Distance" 357 "Distance" 358 "Distance" 359 "Distance" 360 "Distance" 361 "Distance" 362 "Distance" 363 "Distance" 364 "Distance" 365 "Distance" 366 "Distance" 367 "Distance" 368 "Distance" 369 "Distance" 370 "Distance" 371 "Distance" 372 "Distance" 373 "Distance" 374 "Distance" 375 "Distance" 376 "Distance" 377 "Distance" 378 "Distance" 379 "Distance" 380 "Distance" 381 "Distance" 382 "Distance" 383 "Distance" 384 "Distance" 385 "Distance" 386 "Distance" 387 "Distance" 388 "Distance" 389 "Distance" 390 "Distance" 391 "Distance" 392 "Distance" 393 "Distance" 394 "Distance" 395 "Distance" 396 "Distance" 397 "Distance" 398 "Distance" 399 "Distance" 400 "Distance" 401 "Distance" 402 "Distance" 403 "Distance" 404 "Distance" 405 "Distance" 406 "Distance" 407 "Distance" 408 "Distance" 409 "Distance" 410 "Distance" 411 "Distance" 412 "Distance" 413 "Distance" 414 "Distance" 415 "Distance" 416 "Distance" 417 "Distance" 418 "Distance" 419 "Distance" 420 "Distance" 421 "Distance" 422 "Distance" 423 "Distance" 424 "Distance" 425 "Distance" 426 "Distance" 427 "Distance" 428 "Distance" 429 "Distance" 430 "Distance" 431 "Distance" 432 "Distance" 433 "Distance" 434 "Distance" 435 "Distance" 436 "Distance" 437 "Distance" 438 "Distance" 439 "Distance" 440 "Distance" 441 "Distance" 442 "Distance" 443 "Distance" 444 "Distance" 445 "Distance" 446 "Distance" 447 "Distance" 448 "Distance" 449 "Distance" 450 "Distance" 451 "Distance" 452 "Distance" 453 "Distance" 454 "Distance" 455 "Distance" 456 "Distance" 457 "Distance" 458 "Distance" 459 "Distance" 460 "Distance" 461 "Distance" 462 "Distance" 463 "Distance" 464 "Distance" 465 "Distance" 466 "Distance" 467 "Distance" 468 "Distance" 469 "Distance" 470 "Distance" 471 "Distance" 472 "Distance" 473 "Distance" 474 "Distance" 475 "Distance" 476 "Distance" 477 "Distance" 478 "Distance" 479 "Distance" 480 "Distance" 481 "Distance" 482 "Distance" 483 "Distance" 484 "Distance" 485 "Distance" 486 "Distance" 487 "Distance" 488 "Distance" 489 "Distance" 490 "Distance" 491 "Distance" 492 "Distance" 493 "Distance" 494 "Distance" 495 "Distance" 496 "Distance" 497 "Distance" 498 "Distance" 499 "Distance" 500 "Distance" 501 "Distance" 502 "Distance" 503 "Distance" 504 "Distance" 505 "Distance" 506 "Distance" 507 "Distance" 508 "Distance" 509 "Distance" 510 "Distance" 511 "Distance" 512 "Distance" 513 "Distance" 514 "Distance" 515 "Distance" 516 "Distance" 517 "Distance" 518 "Distance" 519 "Distance" 520 "Distance" 521 "Distance" 522 "Distance" 523 "Distance" 524 "Distance" 525 "Distance" 526 "Distance" 527 "Distance" 528 "Distance" 529 "Distance" 530 "Distance" 531 "Distance" 532 "Distance" 533 "Distance" 534 "Distance" 535 "Distance" 536 "Distance" 537 "Distance" 538 "Distance" 539 "Distance" 540 "Distance" 541 "Distance" 542 "Distance" 543 "Distance" 544 "Distance" 545 "Distance" 546 "Distance" 547 "Distance" 548 "Distance" 549 "Distance" 550 "Distance" 551 "Distance" 552 "Distance" 553 "Distance" 554 "Distance" 555 "Distance" 556 "Distance" 557 "Distance" 558 "Distance" 559 "Distance" 560 "Distance" 561 "Distance" 562 "Distance" 563 "Distance" 564 "Distance" 565 "Distance" 566 "Distance" 567 "Distance" 568 "Distance" 569 "Distance" 570 "Distance" 571 "Distance" 572 "Distance" 573 "Distance" 574 "Distance" 575 "Distance" 576 "Distance" 577 "Distance" 578 "Distance" 579 "Distance" 580 "Distance" 581 "Distance" 582 "Distance" 583 "Distance" 584 "Distance" 585 "Distance" 586 "Distance" 587 "Distance" 588 "Distance" 589 "Distance" 590 "Distance" 591 "Distance" 592 "Distance" 593 "Distance" 594 "Distance" 595 "Distance" 596 "Distance" 597 "Distance" 598 "Distance" 599 "Distance" 600 "Distance" 601 "Distance" 602 "Distance" 603 "Distance" 604 "Distance" 605 "Distance" 606 "Distance" 607 "Distance" 608 "Distance" 609 "Distance" 610 "Distance" 611 "Distance" 612 "Distance" 613 "Distance" 614 "Distance" 615 "Distance" 616 "Distance" 617 "Distance" 618 "Distance" 619 "Distance" 620 "Distance" 621 "Distance" 622 "Distance" 623 "Distance" 624 "Distance" 625 "Distance" 626 "Distance" 627 "Distance" 628 "Distance" 629 "Distance" 630 "Distance" 631 "Distance" 632 "Distance" 633 "Distance" 634 "Distance" 635 "Distance" 636 "Distance" 637 "Distance" 638 "Distance" 639 "Distance" 640 "Distance" 641 "Distance" 642 "Distance" 643 "Distance" 644 "Distance" 645 "Distance" 646 "Distance" 647 "Distance" 648 "Distance" 649 "Distance" 650 "Distance" 651 "Distance" 652 "Distance" 653 "Distance" 654 "Distance" 655 "Distance" 656 "Distance" 657 "Distance" 658 "Distance" 659 "Distance" 660 "Distance" 661 "Distance" 662 "Distance" 663 "Distance" 664 "Distance" 665 "Distance" 666 "Distance" 667 "Distance" 668 "Distance" 669 "Distance" 670 "Distance" 671 "Distance" 672 "Distance" 673 "Distance" 674 "Distance" 675 "Distance" 676 "Distance" 677 "Distance" 678 "Distance" 679 "Distance" 680 "Distance" 681 "Distance" 682 "Distance" 683 "Distance" 684 "Distance" 685 "Distance" 686 "Distance" 687 "Distance" 688 "Distance" 689 "Distance" 690 "Distance" 691 "Distance" 692 "Distance" 693 "Distance" 694 "Distance" 695 "Distance" 696 "Distance" 697 "Distance" 698 "Distance" 699 "Distance" 700 "Distance" 701 "Distance" 702 "Distance" 703 "Distance" 704 "Distance" 705 "Distance" 706 "Distance" 707 "Distance" 708 "Distance" 709 "Distance" 710 "Distance" 711 "Distance" 712 "Distance" 713 "Distance" 714 "Distance" 715 "Distance" 716 "Distance" 717 "Distance" 718 "Distance" 719 "Distance" 720 "Distance" 721 "Distance" 722 "Distance" 723 "Distance" 724 "Distance" 725 "Distance" 726 "Distance" 727 "Distance" 728 "Distance" 729 "Distance" 730 "Distance" 731 "Distance" 732 "Distance" 733 "Distance" 734 "Distance" 735 "Distance" 736 "Distance" 737 "Distance" 738 "Distance" 739 "Distance" 740 "Distance" 741 "Distance" 742 "Distance" 743 "Distance" 744 "Distance" 745 "Distance" 746 "Distance" 747 "Distance" 748 "Distance" 749 "Distance" 750 "Distance" 751 "Distance" 752 "Distance" 753 "Distance" 754 "Distance" 755 "Distance" 756 "Distance" 757 "Distance" 758 "Distance" 759 "Distance" 760 "Distance" 761 "Distance" 762 "Distance" 763 "Distance" 764 "Distance" 765 "Distance" 766 "Distance" 767 "Distance" 768 "Distance" 769 "Distance" 770 "Distance" 771 "Distance" 772 "Distance" 773 "Distance" 774 "Distance" 775 "Distance" 776 "Distance" 777 "Distance" 778 "Distance" 779 "Distance" 780 "Distance" 781 "Distance" 782 "Distance" 783 "Distance" 784 "Distance" 785 "Distance" 786 "Distance" 787 "Distance" 788 "Distance" 789 "Distance" 790 "Distance" 791 "Distance" 792 "Distance" 793 "Distance" 794 "Distance" 795 "Distance" 796 "Distance" 797 "Distance" 798 "Distance" 799 "Distance" 800 "Distance" 801 "Distance" 802 "Distance" 803 "Distance" 804 "Distance" 805 "Distance" 806 "Distance" 807 "Distance" 808 "Distance" 809 "Distance" 810 "Distance" 811 "Distance" 812 "Distance" 813 "Distance" 814 "Distance" 815 "Distance" 816 "Distance" 817 "Distance" 818 "Distance" 819 "Distance" 820 "Distance" 821 "Distance" 822 "Distance" 823 "Distance" 824 "Distance" 825 "Distance" 826 "Distance" 827 "Distance" 828 "Distance" 829 "Distance" 830 "Distance" 831 "Distance" 832 "Distance" 833 "Distance" 834 "Distance" 835 "Distance" 836 "Distance" 837 "Distance" 838 "Distance" 839 "Distance" 840 "Distance" 841 "Distance" 842 "Distance" 843 "Distance" 844 "Distance" 845 "Distance" 846 "Distance" 847 "Distance" 848 "Distance" 849 "Distance" 850 "Distance" 851 "Distance" 852 "Distance" 853 "Distance" 854 "Distance" 855 "Distance" 856 "Distance" 857 "Distance" 858 "Distance" 859 "Distance" 860 "Distance" 861 "Distance" 862 "Distance" 863 "Distance" 864 "Distance" 865 "Distance" 866 "Distance" 867 "Distance" 868 "Distance" 869 "Distance" 870 "Distance" 871 "Distance" 872 "Distance" 873 "Distance" 874 "Distance" 875 "Distance" 876 "Distance" 877 "Distance" 878 "Distance" 879 "Distance" 880 "Distance" 881 "Distance" 882 "Distance" 883 "Distance" 884 "Distance" 885 "Distance" 886 "Distance" 887 "Distance" 888 "Distance" 889 "Distance" 890 "Distance" 891 "Distance" 892 "Distance" 893 "Distance" 894 "Distance" 895 "Distance" 896 "Distance" 897 "Distance" 898 "Distance" 899 "Distance" 900 "Distance" 901 "Distance" 902 "Distance" 903 "Distance" 904 "Distance" 905 "Distance" 906 "Distance" 907 "Distance" 908 "Distance" 909 "Distance" 910 "Distance" 911 "Distance" 912 "Distance" 913 "Distance" 914 "Distance" 915 "Distance" 916 "Distance" 917 "Distance" 918 "Distance" 919 "Distance" 920 "Distance" 921 "Distance" 922 "Distance" 923 "Distance" 924 "Distance" 925 "Distance" 926 "Distance" 927 "Distance" 928 "Distance" 929 "Distance" 930 "Distance" 931 "Distance" 932 "Distance" 933 "Distance" 934 "Distance" 935 "Distance" 936 "Distance" 937 "Distance" 938 "Distance" 939 "Distance" 940 "Distance" 941 "Distance" 942 "Distance" 943 "Distance" 944 "Distance" 945 "Distance" 946 "Distance" 947 "Distance" 948 "Distance" 949 "Distance" 950 "Distance" 951 "Distance" 952 "Distance" 953 "Distance" 954 "Distance" 955 "Distance" 956 "Distance" 957 "Distance" 958 "Distance" 959 "Distance" 960 "Distance" 961 "Distance" 962 "Distance" 963 "Distance" 964 "Distance" 965 "Distance" 966 "Distance" 967 "Distance" 968 "Distance" 969 "Distance" 970 "Distance" 971 "Distance" 972 "Distance" 973 "Distance" 974 "Distance" 975 "Distance" 976 "Distance" 977 "Distance" 978 "Distance" 979 "Distance" 980 "Distance" 981 "Distance" 982 "Distance" 983 "Distance" 984 "Distance" 985 "Distance" 986 "Distance" 987 "Distance" 988 "Distance" 989 "Distance" 990 "Distance" 991 "Distance" 992 "Distance" 993 "Distance" 994 "Distance" 995 "Distance" 996 "Distance" 997 "Distance" 998 "Distance" 999 "Distance" 1000 "Distance" 1001 "Distance" 1002 "Distance" 1003 "Distance" 1004 "Distance" 1005 "Distance" 1006 "Distance" 1007 "Distance" 1008 "Distance" 1009 "Distance" 1010 "Distance" 1011 "Distance" 1012 "Distance" 1013 "Distance" 1014 "Distance" 1015 "Distance" 1016 "Distance" 1017 "Distance" 1018 "Distance" 1019 "Distance" 1020 "Distance" 1021 "Distance" 1022 "Distance" 1023 "Invalid" ;
VAL_ 1207 PROSHORT_V2_Value0 0 "Profile Vaue at Offset" 1 "Profile Vaue at Offset" 2 "Profile Vaue at Offset" 3 "Profile Vaue at Offset" 4 "Profile Vaue at Offset" 5 "Profile Vaue at Offset" 6 "Profile Vaue at Offset" 7 "Profile Vaue at Offset" 8 "Profile Vaue at Offset" 9 "Profile Vaue at Offset" 10 "Profile Vaue at Offset" 11 "Profile Vaue at Offset" 12 "Profile Vaue at Offset" 13 "Profile Vaue at Offset" 14 "Profile Vaue at Offset" 15 "Profile Vaue at Offset" 16 "Profile Vaue at Offset" 17 "Profile Vaue at Offset" 18 "Profile Vaue at Offset" 19 "Profile Vaue at Offset" 20 "Profile Vaue at Offset" 21 "Profile Vaue at Offset" 22 "Profile Vaue at Offset" 23 "Profile Vaue at Offset" 24 "Profile Vaue at Offset" 25 "Profile Vaue at Offset" 26 "Profile Vaue at Offset" 27 "Profile Vaue at Offset" 28 "Profile Vaue at Offset" 29 "Profile Vaue at Offset" 30 "Profile Vaue at Offset" 31 "Profile Vaue at Offset" 32 "Profile Vaue at Offset" 33 "Profile Vaue at Offset" 34 "Profile Vaue at Offset" 35 "Profile Vaue at Offset" 36 "Profile Vaue at Offset" 37 "Profile Vaue at Offset" 38 "Profile Vaue at Offset" 39 "Profile Vaue at Offset" 40 "Profile Vaue at Offset" 41 "Profile Vaue at Offset" 42 "Profile Vaue at Offset" 43 "Profile Vaue at Offset" 44 "Profile Vaue at Offset" 45 "Profile Vaue at Offset" 46 "Profile Vaue at Offset" 47 "Profile Vaue at Offset" 48 "Profile Vaue at Offset" 49 "Profile Vaue at Offset" 50 "Profile Vaue at Offset" 51 "Profile Vaue at Offset" 52 "Profile Vaue at Offset" 53 "Profile Vaue at Offset" 54 "Profile Vaue at Offset" 55 "Profile Vaue at Offset" 56 "Profile Vaue at Offset" 57 "Profile Vaue at Offset" 58 "Profile Vaue at Offset" 59 "Profile Vaue at Offset" 60 "Profile Vaue at Offset" 61 "Profile Vaue at Offset" 62 "Profile Vaue at Offset" 63 "Profile Vaue at Offset" 64 "Profile Vaue at Offset" 65 "Profile Vaue at Offset" 66 "Profile Vaue at Offset" 67 "Profile Vaue at Offset" 68 "Profile Vaue at Offset" 69 "Profile Vaue at Offset" 70 "Profile Vaue at Offset" 71 "Profile Vaue at Offset" 72 "Profile Vaue at Offset" 73 "Profile Vaue at Offset" 74 "Profile Vaue at Offset" 75 "Profile Vaue at Offset" 76 "Profile Vaue at Offset" 77 "Profile Vaue at Offset" 78 "Profile Vaue at Offset" 79 "Profile Vaue at Offset" 80 "Profile Vaue at Offset" 81 "Profile Vaue at Offset" 82 "Profile Vaue at Offset" 83 "Profile Vaue at Offset" 84 "Profile Vaue at Offset" 85 "Profile Vaue at Offset" 86 "Profile Vaue at Offset" 87 "Profile Vaue at Offset" 88 "Profile Vaue at Offset" 89 "Profile Vaue at Offset" 90 "Profile Vaue at Offset" 91 "Profile Vaue at Offset" 92 "Profile Vaue at Offset" 93 "Profile Vaue at Offset" 94 "Profile Vaue at Offset" 95 "Profile Vaue at Offset" 96 "Profile Vaue at Offset" 97 "Profile Vaue at Offset" 98 "Profile Vaue at Offset" 99 "Profile Vaue at Offset" 100 "Profile Vaue at Offset" 101 "Profile Vaue at Offset" 102 "Profile Vaue at Offset" 103 "Profile Vaue at Offset" 104 "Profile Vaue at Offset" 105 "Profile Vaue at Offset" 106 "Profile Vaue at Offset" 107 "Profile Vaue at Offset" 108 "Profile Vaue at Offset" 109 "Profile Vaue at Offset" 110 "Profile Vaue at Offset" 111 "Profile Vaue at Offset" 112 "Profile Vaue at Offset" 113 "Profile Vaue at Offset" 114 "Profile Vaue at Offset" 115 "Profile Vaue at Offset" 116 "Profile Vaue at Offset" 117 "Profile Vaue at Offset" 118 "Profile Vaue at Offset" 119 "Profile Vaue at Offset" 120 "Profile Vaue at Offset" 121 "Profile Vaue at Offset" 122 "Profile Vaue at Offset" 123 "Profile Vaue at Offset" 124 "Profile Vaue at Offset" 125 "Profile Vaue at Offset" 126 "Profile Vaue at Offset" 127 "Profile Vaue at Offset" 128 "Profile Vaue at Offset" 129 "Profile Vaue at Offset" 130 "Profile Vaue at Offset" 131 "Profile Vaue at Offset" 132 "Profile Vaue at Offset" 133 "Profile Vaue at Offset" 134 "Profile Vaue at Offset" 135 "Profile Vaue at Offset" 136 "Profile Vaue at Offset" 137 "Profile Vaue at Offset" 138 "Profile Vaue at Offset" 139 "Profile Vaue at Offset" 140 "Profile Vaue at Offset" 141 "Profile Vaue at Offset" 142 "Profile Vaue at Offset" 143 "Profile Vaue at Offset" 144 "Profile Vaue at Offset" 145 "Profile Vaue at Offset" 146 "Profile Vaue at Offset" 147 "Profile Vaue at Offset" 148 "Profile Vaue at Offset" 149 "Profile Vaue at Offset" 150 "Profile Vaue at Offset" 151 "Profile Vaue at Offset" 152 "Profile Vaue at Offset" 153 "Profile Vaue at Offset" 154 "Profile Vaue at Offset" 155 "Profile Vaue at Offset" 156 "Profile Vaue at Offset" 157 "Profile Vaue at Offset" 158 "Profile Vaue at Offset" 159 "Profile Vaue at Offset" 160 "Profile Vaue at Offset" 161 "Profile Vaue at Offset" 162 "Profile Vaue at Offset" 163 "Profile Vaue at Offset" 164 "Profile Vaue at Offset" 165 "Profile Vaue at Offset" 166 "Profile Vaue at Offset" 167 "Profile Vaue at Offset" 168 "Profile Vaue at Offset" 169 "Profile Vaue at Offset" 170 "Profile Vaue at Offset" 171 "Profile Vaue at Offset" 172 "Profile Vaue at Offset" 173 "Profile Vaue at Offset" 174 "Profile Vaue at Offset" 175 "Profile Vaue at Offset" 176 "Profile Vaue at Offset" 177 "Profile Vaue at Offset" 178 "Profile Vaue at Offset" 179 "Profile Vaue at Offset" 180 "Profile Vaue at Offset" 181 "Profile Vaue at Offset" 182 "Profile Vaue at Offset" 183 "Profile Vaue at Offset" 184 "Profile Vaue at Offset" 185 "Profile Vaue at Offset" 186 "Profile Vaue at Offset" 187 "Profile Vaue at Offset" 188 "Profile Vaue at Offset" 189 "Profile Vaue at Offset" 190 "Profile Vaue at Offset" 191 "Profile Vaue at Offset" 192 "Profile Vaue at Offset" 193 "Profile Vaue at Offset" 194 "Profile Vaue at Offset" 195 "Profile Vaue at Offset" 196 "Profile Vaue at Offset" 197 "Profile Vaue at Offset" 198 "Profile Vaue at Offset" 199 "Profile Vaue at Offset" 200 "Profile Vaue at Offset" 201 "Profile Vaue at Offset" 202 "Profile Vaue at Offset" 203 "Profile Vaue at Offset" 204 "Profile Vaue at Offset" 205 "Profile Vaue at Offset" 206 "Profile Vaue at Offset" 207 "Profile Vaue at Offset" 208 "Profile Vaue at Offset" 209 "Profile Vaue at Offset" 210 "Profile Vaue at Offset" 211 "Profile Vaue at Offset" 212 "Profile Vaue at Offset" 213 "Profile Vaue at Offset" 214 "Profile Vaue at Offset" 215 "Profile Vaue at Offset" 216 "Profile Vaue at Offset" 217 "Profile Vaue at Offset" 218 "Profile Vaue at Offset" 219 "Profile Vaue at Offset" 220 "Profile Vaue at Offset" 221 "Profile Vaue at Offset" 222 "Profile Vaue at Offset" 223 "Profile Vaue at Offset" 224 "Profile Vaue at Offset" 225 "Profile Vaue at Offset" 226 "Profile Vaue at Offset" 227 "Profile Vaue at Offset" 228 "Profile Vaue at Offset" 229 "Profile Vaue at Offset" 230 "Profile Vaue at Offset" 231 "Profile Vaue at Offset" 232 "Profile Vaue at Offset" 233 "Profile Vaue at Offset" 234 "Profile Vaue at Offset" 235 "Profile Vaue at Offset" 236 "Profile Vaue at Offset" 237 "Profile Vaue at Offset" 238 "Profile Vaue at Offset" 239 "Profile Vaue at Offset" 240 "Profile Vaue at Offset" 241 "Profile Vaue at Offset" 242 "Profile Vaue at Offset" 243 "Profile Vaue at Offset" 244 "Profile Vaue at Offset" 245 "Profile Vaue at Offset" 246 "Profile Vaue at Offset" 247 "Profile Vaue at Offset" 248 "Profile Vaue at Offset" 249 "Profile Vaue at Offset" 250 "Profile Vaue at Offset" 251 "Profile Vaue at Offset" 252 "Profile Vaue at Offset" 253 "Profile Vaue at Offset" 254 "Profile Vaue at Offset" 255 "Profile Vaue at Offset" 256 "Profile Vaue at Offset" 257 "Profile Vaue at Offset" 258 "Profile Vaue at Offset" 259 "Profile Vaue at Offset" 260 "Profile Vaue at Offset" 261 "Profile Vaue at Offset" 262 "Profile Vaue at Offset" 263 "Profile Vaue at Offset" 264 "Profile Vaue at Offset" 265 "Profile Vaue at Offset" 266 "Profile Vaue at Offset" 267 "Profile Vaue at Offset" 268 "Profile Vaue at Offset" 269 "Profile Vaue at Offset" 270 "Profile Vaue at Offset" 271 "Profile Vaue at Offset" 272 "Profile Vaue at Offset" 273 "Profile Vaue at Offset" 274 "Profile Vaue at Offset" 275 "Profile Vaue at Offset" 276 "Profile Vaue at Offset" 277 "Profile Vaue at Offset" 278 "Profile Vaue at Offset" 279 "Profile Vaue at Offset" 280 "Profile Vaue at Offset" 281 "Profile Vaue at Offset" 282 "Profile Vaue at Offset" 283 "Profile Vaue at Offset" 284 "Profile Vaue at Offset" 285 "Profile Vaue at Offset" 286 "Profile Vaue at Offset" 287 "Profile Vaue at Offset" 288 "Profile Vaue at Offset" 289 "Profile Vaue at Offset" 290 "Profile Vaue at Offset" 291 "Profile Vaue at Offset" 292 "Profile Vaue at Offset" 293 "Profile Vaue at Offset" 294 "Profile Vaue at Offset" 295 "Profile Vaue at Offset" 296 "Profile Vaue at Offset" 297 "Profile Vaue at Offset" 298 "Profile Vaue at Offset" 299 "Profile Vaue at Offset" 300 "Profile Vaue at Offset" 301 "Profile Vaue at Offset" 302 "Profile Vaue at Offset" 303 "Profile Vaue at Offset" 304 "Profile Vaue at Offset" 305 "Profile Vaue at Offset" 306 "Profile Vaue at Offset" 307 "Profile Vaue at Offset" 308 "Profile Vaue at Offset" 309 "Profile Vaue at Offset" 310 "Profile Vaue at Offset" 311 "Profile Vaue at Offset" 312 "Profile Vaue at Offset" 313 "Profile Vaue at Offset" 314 "Profile Vaue at Offset" 315 "Profile Vaue at Offset" 316 "Profile Vaue at Offset" 317 "Profile Vaue at Offset" 318 "Profile Vaue at Offset" 319 "Profile Vaue at Offset" 320 "Profile Vaue at Offset" 321 "Profile Vaue at Offset" 322 "Profile Vaue at Offset" 323 "Profile Vaue at Offset" 324 "Profile Vaue at Offset" 325 "Profile Vaue at Offset" 326 "Profile Vaue at Offset" 327 "Profile Vaue at Offset" 328 "Profile Vaue at Offset" 329 "Profile Vaue at Offset" 330 "Profile Vaue at Offset" 331 "Profile Vaue at Offset" 332 "Profile Vaue at Offset" 333 "Profile Vaue at Offset" 334 "Profile Vaue at Offset" 335 "Profile Vaue at Offset" 336 "Profile Vaue at Offset" 337 "Profile Vaue at Offset" 338 "Profile Vaue at Offset" 339 "Profile Vaue at Offset" 340 "Profile Vaue at Offset" 341 "Profile Vaue at Offset" 342 "Profile Vaue at Offset" 343 "Profile Vaue at Offset" 344 "Profile Vaue at Offset" 345 "Profile Vaue at Offset" 346 "Profile Vaue at Offset" 347 "Profile Vaue at Offset" 348 "Profile Vaue at Offset" 349 "Profile Vaue at Offset" 350 "Profile Vaue at Offset" 351 "Profile Vaue at Offset" 352 "Profile Vaue at Offset" 353 "Profile Vaue at Offset" 354 "Profile Vaue at Offset" 355 "Profile Vaue at Offset" 356 "Profile Vaue at Offset" 357 "Profile Vaue at Offset" 358 "Profile Vaue at Offset" 359 "Profile Vaue at Offset" 360 "Profile Vaue at Offset" 361 "Profile Vaue at Offset" 362 "Profile Vaue at Offset" 363 "Profile Vaue at Offset" 364 "Profile Vaue at Offset" 365 "Profile Vaue at Offset" 366 "Profile Vaue at Offset" 367 "Profile Vaue at Offset" 368 "Profile Vaue at Offset" 369 "Profile Vaue at Offset" 370 "Profile Vaue at Offset" 371 "Profile Vaue at Offset" 372 "Profile Vaue at Offset" 373 "Profile Vaue at Offset" 374 "Profile Vaue at Offset" 375 "Profile Vaue at Offset" 376 "Profile Vaue at Offset" 377 "Profile Vaue at Offset" 378 "Profile Vaue at Offset" 379 "Profile Vaue at Offset" 380 "Profile Vaue at Offset" 381 "Profile Vaue at Offset" 382 "Profile Vaue at Offset" 383 "Profile Vaue at Offset" 384 "Profile Vaue at Offset" 385 "Profile Vaue at Offset" 386 "Profile Vaue at Offset" 387 "Profile Vaue at Offset" 388 "Profile Vaue at Offset" 389 "Profile Vaue at Offset" 390 "Profile Vaue at Offset" 391 "Profile Vaue at Offset" 392 "Profile Vaue at Offset" 393 "Profile Vaue at Offset" 394 "Profile Vaue at Offset" 395 "Profile Vaue at Offset" 396 "Profile Vaue at Offset" 397 "Profile Vaue at Offset" 398 "Profile Vaue at Offset" 399 "Profile Vaue at Offset" 400 "Profile Vaue at Offset" 401 "Profile Vaue at Offset" 402 "Profile Vaue at Offset" 403 "Profile Vaue at Offset" 404 "Profile Vaue at Offset" 405 "Profile Vaue at Offset" 406 "Profile Vaue at Offset" 407 "Profile Vaue at Offset" 408 "Profile Vaue at Offset" 409 "Profile Vaue at Offset" 410 "Profile Vaue at Offset" 411 "Profile Vaue at Offset" 412 "Profile Vaue at Offset" 413 "Profile Vaue at Offset" 414 "Profile Vaue at Offset" 415 "Profile Vaue at Offset" 416 "Profile Vaue at Offset" 417 "Profile Vaue at Offset" 418 "Profile Vaue at Offset" 419 "Profile Vaue at Offset" 420 "Profile Vaue at Offset" 421 "Profile Vaue at Offset" 422 "Profile Vaue at Offset" 423 "Profile Vaue at Offset" 424 "Profile Vaue at Offset" 425 "Profile Vaue at Offset" 426 "Profile Vaue at Offset" 427 "Profile Vaue at Offset" 428 "Profile Vaue at Offset" 429 "Profile Vaue at Offset" 430 "Profile Vaue at Offset" 431 "Profile Vaue at Offset" 432 "Profile Vaue at Offset" 433 "Profile Vaue at Offset" 434 "Profile Vaue at Offset" 435 "Profile Vaue at Offset" 436 "Profile Vaue at Offset" 437 "Profile Vaue at Offset" 438 "Profile Vaue at Offset" 439 "Profile Vaue at Offset" 440 "Profile Vaue at Offset" 441 "Profile Vaue at Offset" 442 "Profile Vaue at Offset" 443 "Profile Vaue at Offset" 444 "Profile Vaue at Offset" 445 "Profile Vaue at Offset" 446 "Profile Vaue at Offset" 447 "Profile Vaue at Offset" 448 "Profile Vaue at Offset" 449 "Profile Vaue at Offset" 450 "Profile Vaue at Offset" 451 "Profile Vaue at Offset" 452 "Profile Vaue at Offset" 453 "Profile Vaue at Offset" 454 "Profile Vaue at Offset" 455 "Profile Vaue at Offset" 456 "Profile Vaue at Offset" 457 "Profile Vaue at Offset" 458 "Profile Vaue at Offset" 459 "Profile Vaue at Offset" 460 "Profile Vaue at Offset" 461 "Profile Vaue at Offset" 462 "Profile Vaue at Offset" 463 "Profile Vaue at Offset" 464 "Profile Vaue at Offset" 465 "Profile Vaue at Offset" 466 "Profile Vaue at Offset" 467 "Profile Vaue at Offset" 468 "Profile Vaue at Offset" 469 "Profile Vaue at Offset" 470 "Profile Vaue at Offset" 471 "Profile Vaue at Offset" 472 "Profile Vaue at Offset" 473 "Profile Vaue at Offset" 474 "Profile Vaue at Offset" 475 "Profile Vaue at Offset" 476 "Profile Vaue at Offset" 477 "Profile Vaue at Offset" 478 "Profile Vaue at Offset" 479 "Profile Vaue at Offset" 480 "Profile Vaue at Offset" 481 "Profile Vaue at Offset" 482 "Profile Vaue at Offset" 483 "Profile Vaue at Offset" 484 "Profile Vaue at Offset" 485 "Profile Vaue at Offset" 486 "Profile Vaue at Offset" 487 "Profile Vaue at Offset" 488 "Profile Vaue at Offset" 489 "Profile Vaue at Offset" 490 "Profile Vaue at Offset" 491 "Profile Vaue at Offset" 492 "Profile Vaue at Offset" 493 "Profile Vaue at Offset" 494 "Profile Vaue at Offset" 495 "Profile Vaue at Offset" 496 "Profile Vaue at Offset" 497 "Profile Vaue at Offset" 498 "Profile Vaue at Offset" 499 "Profile Vaue at Offset" 500 "Profile Vaue at Offset" 501 "Profile Vaue at Offset" 502 "Profile Vaue at Offset" 503 "Profile Vaue at Offset" 504 "Profile Vaue at Offset" 505 "Profile Vaue at Offset" 506 "Profile Vaue at Offset" 507 "Profile Vaue at Offset" 508 "Profile Vaue at Offset" 509 "Profile Vaue at Offset" 510 "Profile Vaue at Offset" 511 "Profile Vaue at Offset" 512 "Profile Vaue at Offset" 513 "Profile Vaue at Offset" 514 "Profile Vaue at Offset" 515 "Profile Vaue at Offset" 516 "Profile Vaue at Offset" 517 "Profile Vaue at Offset" 518 "Profile Vaue at Offset" 519 "Profile Vaue at Offset" 520 "Profile Vaue at Offset" 521 "Profile Vaue at Offset" 522 "Profile Vaue at Offset" 523 "Profile Vaue at Offset" 524 "Profile Vaue at Offset" 525 "Profile Vaue at Offset" 526 "Profile Vaue at Offset" 527 "Profile Vaue at Offset" 528 "Profile Vaue at Offset" 529 "Profile Vaue at Offset" 530 "Profile Vaue at Offset" 531 "Profile Vaue at Offset" 532 "Profile Vaue at Offset" 533 "Profile Vaue at Offset" 534 "Profile Vaue at Offset" 535 "Profile Vaue at Offset" 536 "Profile Vaue at Offset" 537 "Profile Vaue at Offset" 538 "Profile Vaue at Offset" 539 "Profile Vaue at Offset" 540 "Profile Vaue at Offset" 541 "Profile Vaue at Offset" 542 "Profile Vaue at Offset" 543 "Profile Vaue at Offset" 544 "Profile Vaue at Offset" 545 "Profile Vaue at Offset" 546 "Profile Vaue at Offset" 547 "Profile Vaue at Offset" 548 "Profile Vaue at Offset" 549 "Profile Vaue at Offset" 550 "Profile Vaue at Offset" 551 "Profile Vaue at Offset" 552 "Profile Vaue at Offset" 553 "Profile Vaue at Offset" 554 "Profile Vaue at Offset" 555 "Profile Vaue at Offset" 556 "Profile Vaue at Offset" 557 "Profile Vaue at Offset" 558 "Profile Vaue at Offset" 559 "Profile Vaue at Offset" 560 "Profile Vaue at Offset" 561 "Profile Vaue at Offset" 562 "Profile Vaue at Offset" 563 "Profile Vaue at Offset" 564 "Profile Vaue at Offset" 565 "Profile Vaue at Offset" 566 "Profile Vaue at Offset" 567 "Profile Vaue at Offset" 568 "Profile Vaue at Offset" 569 "Profile Vaue at Offset" 570 "Profile Vaue at Offset" 571 "Profile Vaue at Offset" 572 "Profile Vaue at Offset" 573 "Profile Vaue at Offset" 574 "Profile Vaue at Offset" 575 "Profile Vaue at Offset" 576 "Profile Vaue at Offset" 577 "Profile Vaue at Offset" 578 "Profile Vaue at Offset" 579 "Profile Vaue at Offset" 580 "Profile Vaue at Offset" 581 "Profile Vaue at Offset" 582 "Profile Vaue at Offset" 583 "Profile Vaue at Offset" 584 "Profile Vaue at Offset" 585 "Profile Vaue at Offset" 586 "Profile Vaue at Offset" 587 "Profile Vaue at Offset" 588 "Profile Vaue at Offset" 589 "Profile Vaue at Offset" 590 "Profile Vaue at Offset" 591 "Profile Vaue at Offset" 592 "Profile Vaue at Offset" 593 "Profile Vaue at Offset" 594 "Profile Vaue at Offset" 595 "Profile Vaue at Offset" 596 "Profile Vaue at Offset" 597 "Profile Vaue at Offset" 598 "Profile Vaue at Offset" 599 "Profile Vaue at Offset" 600 "Profile Vaue at Offset" 601 "Profile Vaue at Offset" 602 "Profile Vaue at Offset" 603 "Profile Vaue at Offset" 604 "Profile Vaue at Offset" 605 "Profile Vaue at Offset" 606 "Profile Vaue at Offset" 607 "Profile Vaue at Offset" 608 "Profile Vaue at Offset" 609 "Profile Vaue at Offset" 610 "Profile Vaue at Offset" 611 "Profile Vaue at Offset" 612 "Profile Vaue at Offset" 613 "Profile Vaue at Offset" 614 "Profile Vaue at Offset" 615 "Profile Vaue at Offset" 616 "Profile Vaue at Offset" 617 "Profile Vaue at Offset" 618 "Profile Vaue at Offset" 619 "Profile Vaue at Offset" 620 "Profile Vaue at Offset" 621 "Profile Vaue at Offset" 622 "Profile Vaue at Offset" 623 "Profile Vaue at Offset" 624 "Profile Vaue at Offset" 625 "Profile Vaue at Offset" 626 "Profile Vaue at Offset" 627 "Profile Vaue at Offset" 628 "Profile Vaue at Offset" 629 "Profile Vaue at Offset" 630 "Profile Vaue at Offset" 631 "Profile Vaue at Offset" 632 "Profile Vaue at Offset" 633 "Profile Vaue at Offset" 634 "Profile Vaue at Offset" 635 "Profile Vaue at Offset" 636 "Profile Vaue at Offset" 637 "Profile Vaue at Offset" 638 "Profile Vaue at Offset" 639 "Profile Vaue at Offset" 640 "Profile Vaue at Offset" 641 "Profile Vaue at Offset" 642 "Profile Vaue at Offset" 643 "Profile Vaue at Offset" 644 "Profile Vaue at Offset" 645 "Profile Vaue at Offset" 646 "Profile Vaue at Offset" 647 "Profile Vaue at Offset" 648 "Profile Vaue at Offset" 649 "Profile Vaue at Offset" 650 "Profile Vaue at Offset" 651 "Profile Vaue at Offset" 652 "Profile Vaue at Offset" 653 "Profile Vaue at Offset" 654 "Profile Vaue at Offset" 655 "Profile Vaue at Offset" 656 "Profile Vaue at Offset" 657 "Profile Vaue at Offset" 658 "Profile Vaue at Offset" 659 "Profile Vaue at Offset" 660 "Profile Vaue at Offset" 661 "Profile Vaue at Offset" 662 "Profile Vaue at Offset" 663 "Profile Vaue at Offset" 664 "Profile Vaue at Offset" 665 "Profile Vaue at Offset" 666 "Profile Vaue at Offset" 667 "Profile Vaue at Offset" 668 "Profile Vaue at Offset" 669 "Profile Vaue at Offset" 670 "Profile Vaue at Offset" 671 "Profile Vaue at Offset" 672 "Profile Vaue at Offset" 673 "Profile Vaue at Offset" 674 "Profile Vaue at Offset" 675 "Profile Vaue at Offset" 676 "Profile Vaue at Offset" 677 "Profile Vaue at Offset" 678 "Profile Vaue at Offset" 679 "Profile Vaue at Offset" 680 "Profile Vaue at Offset" 681 "Profile Vaue at Offset" 682 "Profile Vaue at Offset" 683 "Profile Vaue at Offset" 684 "Profile Vaue at Offset" 685 "Profile Vaue at Offset" 686 "Profile Vaue at Offset" 687 "Profile Vaue at Offset" 688 "Profile Vaue at Offset" 689 "Profile Vaue at Offset" 690 "Profile Vaue at Offset" 691 "Profile Vaue at Offset" 692 "Profile Vaue at Offset" 693 "Profile Vaue at Offset" 694 "Profile Vaue at Offset" 695 "Profile Vaue at Offset" 696 "Profile Vaue at Offset" 697 "Profile Vaue at Offset" 698 "Profile Vaue at Offset" 699 "Profile Vaue at Offset" 700 "Profile Vaue at Offset" 701 "Profile Vaue at Offset" 702 "Profile Vaue at Offset" 703 "Profile Vaue at Offset" 704 "Profile Vaue at Offset" 705 "Profile Vaue at Offset" 706 "Profile Vaue at Offset" 707 "Profile Vaue at Offset" 708 "Profile Vaue at Offset" 709 "Profile Vaue at Offset" 710 "Profile Vaue at Offset" 711 "Profile Vaue at Offset" 712 "Profile Vaue at Offset" 713 "Profile Vaue at Offset" 714 "Profile Vaue at Offset" 715 "Profile Vaue at Offset" 716 "Profile Vaue at Offset" 717 "Profile Vaue at Offset" 718 "Profile Vaue at Offset" 719 "Profile Vaue at Offset" 720 "Profile Vaue at Offset" 721 "Profile Vaue at Offset" 722 "Profile Vaue at Offset" 723 "Profile Vaue at Offset" 724 "Profile Vaue at Offset" 725 "Profile Vaue at Offset" 726 "Profile Vaue at Offset" 727 "Profile Vaue at Offset" 728 "Profile Vaue at Offset" 729 "Profile Vaue at Offset" 730 "Profile Vaue at Offset" 731 "Profile Vaue at Offset" 732 "Profile Vaue at Offset" 733 "Profile Vaue at Offset" 734 "Profile Vaue at Offset" 735 "Profile Vaue at Offset" 736 "Profile Vaue at Offset" 737 "Profile Vaue at Offset" 738 "Profile Vaue at Offset" 739 "Profile Vaue at Offset" 740 "Profile Vaue at Offset" 741 "Profile Vaue at Offset" 742 "Profile Vaue at Offset" 743 "Profile Vaue at Offset" 744 "Profile Vaue at Offset" 745 "Profile Vaue at Offset" 746 "Profile Vaue at Offset" 747 "Profile Vaue at Offset" 748 "Profile Vaue at Offset" 749 "Profile Vaue at Offset" 750 "Profile Vaue at Offset" 751 "Profile Vaue at Offset" 752 "Profile Vaue at Offset" 753 "Profile Vaue at Offset" 754 "Profile Vaue at Offset" 755 "Profile Vaue at Offset" 756 "Profile Vaue at Offset" 757 "Profile Vaue at Offset" 758 "Profile Vaue at Offset" 759 "Profile Vaue at Offset" 760 "Profile Vaue at Offset" 761 "Profile Vaue at Offset" 762 "Profile Vaue at Offset" 763 "Profile Vaue at Offset" 764 "Profile Vaue at Offset" 765 "Profile Vaue at Offset" 766 "Profile Vaue at Offset" 767 "Profile Vaue at Offset" 768 "Profile Vaue at Offset" 769 "Profile Vaue at Offset" 770 "Profile Vaue at Offset" 771 "Profile Vaue at Offset" 772 "Profile Vaue at Offset" 773 "Profile Vaue at Offset" 774 "Profile Vaue at Offset" 775 "Profile Vaue at Offset" 776 "Profile Vaue at Offset" 777 "Profile Vaue at Offset" 778 "Profile Vaue at Offset" 779 "Profile Vaue at Offset" 780 "Profile Vaue at Offset" 781 "Profile Vaue at Offset" 782 "Profile Vaue at Offset" 783 "Profile Vaue at Offset" 784 "Profile Vaue at Offset" 785 "Profile Vaue at Offset" 786 "Profile Vaue at Offset" 787 "Profile Vaue at Offset" 788 "Profile Vaue at Offset" 789 "Profile Vaue at Offset" 790 "Profile Vaue at Offset" 791 "Profile Vaue at Offset" 792 "Profile Vaue at Offset" 793 "Profile Vaue at Offset" 794 "Profile Vaue at Offset" 795 "Profile Vaue at Offset" 796 "Profile Vaue at Offset" 797 "Profile Vaue at Offset" 798 "Profile Vaue at Offset" 799 "Profile Vaue at Offset" 800 "Profile Vaue at Offset" 801 "Profile Vaue at Offset" 802 "Profile Vaue at Offset" 803 "Profile Vaue at Offset" 804 "Profile Vaue at Offset" 805 "Profile Vaue at Offset" 806 "Profile Vaue at Offset" 807 "Profile Vaue at Offset" 808 "Profile Vaue at Offset" 809 "Profile Vaue at Offset" 810 "Profile Vaue at Offset" 811 "Profile Vaue at Offset" 812 "Profile Vaue at Offset" 813 "Profile Vaue at Offset" 814 "Profile Vaue at Offset" 815 "Profile Vaue at Offset" 816 "Profile Vaue at Offset" 817 "Profile Vaue at Offset" 818 "Profile Vaue at Offset" 819 "Profile Vaue at Offset" 820 "Profile Vaue at Offset" 821 "Profile Vaue at Offset" 822 "Profile Vaue at Offset" 823 "Profile Vaue at Offset" 824 "Profile Vaue at Offset" 825 "Profile Vaue at Offset" 826 "Profile Vaue at Offset" 827 "Profile Vaue at Offset" 828 "Profile Vaue at Offset" 829 "Profile Vaue at Offset" 830 "Profile Vaue at Offset" 831 "Profile Vaue at Offset" 832 "Profile Vaue at Offset" 833 "Profile Vaue at Offset" 834 "Profile Vaue at Offset" 835 "Profile Vaue at Offset" 836 "Profile Vaue at Offset" 837 "Profile Vaue at Offset" 838 "Profile Vaue at Offset" 839 "Profile Vaue at Offset" 840 "Profile Vaue at Offset" 841 "Profile Vaue at Offset" 842 "Profile Vaue at Offset" 843 "Profile Vaue at Offset" 844 "Profile Vaue at Offset" 845 "Profile Vaue at Offset" 846 "Profile Vaue at Offset" 847 "Profile Vaue at Offset" 848 "Profile Vaue at Offset" 849 "Profile Vaue at Offset" 850 "Profile Vaue at Offset" 851 "Profile Vaue at Offset" 852 "Profile Vaue at Offset" 853 "Profile Vaue at Offset" 854 "Profile Vaue at Offset" 855 "Profile Vaue at Offset" 856 "Profile Vaue at Offset" 857 "Profile Vaue at Offset" 858 "Profile Vaue at Offset" 859 "Profile Vaue at Offset" 860 "Profile Vaue at Offset" 861 "Profile Vaue at Offset" 862 "Profile Vaue at Offset" 863 "Profile Vaue at Offset" 864 "Profile Vaue at Offset" 865 "Profile Vaue at Offset" 866 "Profile Vaue at Offset" 867 "Profile Vaue at Offset" 868 "Profile Vaue at Offset" 869 "Profile Vaue at Offset" 870 "Profile Vaue at Offset" 871 "Profile Vaue at Offset" 872 "Profile Vaue at Offset" 873 "Profile Vaue at Offset" 874 "Profile Vaue at Offset" 875 "Profile Vaue at Offset" 876 "Profile Vaue at Offset" 877 "Profile Vaue at Offset" 878 "Profile Vaue at Offset" 879 "Profile Vaue at Offset" 880 "Profile Vaue at Offset" 881 "Profile Vaue at Offset" 882 "Profile Vaue at Offset" 883 "Profile Vaue at Offset" 884 "Profile Vaue at Offset" 885 "Profile Vaue at Offset" 886 "Profile Vaue at Offset" 887 "Profile Vaue at Offset" 888 "Profile Vaue at Offset" 889 "Profile Vaue at Offset" 890 "Profile Vaue at Offset" 891 "Profile Vaue at Offset" 892 "Profile Vaue at Offset" 893 "Profile Vaue at Offset" 894 "Profile Vaue at Offset" 895 "Profile Vaue at Offset" 896 "Profile Vaue at Offset" 897 "Profile Vaue at Offset" 898 "Profile Vaue at Offset" 899 "Profile Vaue at Offset" 900 "Profile Vaue at Offset" 901 "Profile Vaue at Offset" 902 "Profile Vaue at Offset" 903 "Profile Vaue at Offset" 904 "Profile Vaue at Offset" 905 "Profile Vaue at Offset" 906 "Profile Vaue at Offset" 907 "Profile Vaue at Offset" 908 "Profile Vaue at Offset" 909 "Profile Vaue at Offset" 910 "Profile Vaue at Offset" 911 "Profile Vaue at Offset" 912 "Profile Vaue at Offset" 913 "Profile Vaue at Offset" 914 "Profile Vaue at Offset" 915 "Profile Vaue at Offset" 916 "Profile Vaue at Offset" 917 "Profile Vaue at Offset" 918 "Profile Vaue at Offset" 919 "Profile Vaue at Offset" 920 "Profile Vaue at Offset" 921 "Profile Vaue at Offset" 922 "Profile Vaue at Offset" 923 "Profile Vaue at Offset" 924 "Profile Vaue at Offset" 925 "Profile Vaue at Offset" 926 "Profile Vaue at Offset" 927 "Profile Vaue at Offset" 928 "Profile Vaue at Offset" 929 "Profile Vaue at Offset" 930 "Profile Vaue at Offset" 931 "Profile Vaue at Offset" 932 "Profile Vaue at Offset" 933 "Profile Vaue at Offset" 934 "Profile Vaue at Offset" 935 "Profile Vaue at Offset" 936 "Profile Vaue at Offset" 937 "Profile Vaue at Offset" 938 "Profile Vaue at Offset" 939 "Profile Vaue at Offset" 940 "Profile Vaue at Offset" 941 "Profile Vaue at Offset" 942 "Profile Vaue at Offset" 943 "Profile Vaue at Offset" 944 "Profile Vaue at Offset" 945 "Profile Vaue at Offset" 946 "Profile Vaue at Offset" 947 "Profile Vaue at Offset" 948 "Profile Vaue at Offset" 949 "Profile Vaue at Offset" 950 "Profile Vaue at Offset" 951 "Profile Vaue at Offset" 952 "Profile Vaue at Offset" 953 "Profile Vaue at Offset" 954 "Profile Vaue at Offset" 955 "Profile Vaue at Offset" 956 "Profile Vaue at Offset" 957 "Profile Vaue at Offset" 958 "Profile Vaue at Offset" 959 "Profile Vaue at Offset" 960 "Profile Vaue at Offset" 961 "Profile Vaue at Offset" 962 "Profile Vaue at Offset" 963 "Profile Vaue at Offset" 964 "Profile Vaue at Offset" 965 "Profile Vaue at Offset" 966 "Profile Vaue at Offset" 967 "Profile Vaue at Offset" 968 "Profile Vaue at Offset" 969 "Profile Vaue at Offset" 970 "Profile Vaue at Offset" 971 "Profile Vaue at Offset" 972 "Profile Vaue at Offset" 973 "Profile Vaue at Offset" 974 "Profile Vaue at Offset" 975 "Profile Vaue at Offset" 976 "Profile Vaue at Offset" 977 "Profile Vaue at Offset" 978 "Profile Vaue at Offset" 979 "Profile Vaue at Offset" 980 "Profile Vaue at Offset" 981 "Profile Vaue at Offset" 982 "Profile Vaue at Offset" 983 "Profile Vaue at Offset" 984 "Profile Vaue at Offset" 985 "Profile Vaue at Offset" 986 "Profile Vaue at Offset" 987 "Profile Vaue at Offset" 988 "Profile Vaue at Offset" 989 "Profile Vaue at Offset" 990 "Profile Vaue at Offset" 991 "Profile Vaue at Offset" 992 "Profile Vaue at Offset" 993 "Profile Vaue at Offset" 994 "Profile Vaue at Offset" 995 "Profile Vaue at Offset" 996 "Profile Vaue at Offset" 997 "Profile Vaue at Offset" 998 "Profile Vaue at Offset" 999 "Profile Vaue at Offset" 1000 "Profile Vaue at Offset" 1001 "Profile Vaue at Offset" 1002 "Profile Vaue at Offset" 1003 "Profile Vaue at Offset" 1004 "Profile Vaue at Offset" 1005 "Profile Vaue at Offset" 1006 "Profile Vaue at Offset" 1007 "Profile Vaue at Offset" 1008 "Profile Vaue at Offset" 1009 "Profile Vaue at Offset" 1010 "Profile Vaue at Offset" 1011 "Profile Vaue at Offset" 1012 "Profile Vaue at Offset" 1013 "Profile Vaue at Offset" 1014 "Profile Vaue at Offset" 1015 "Profile Vaue at Offset" 1016 "Profile Vaue at Offset" 1017 "Profile Vaue at Offset" 1018 "Profile Vaue at Offset" 1019 "Profile Vaue at Offset" 1020 "Profile Vaue at Offset" 1021 "Profile Vaue at Offset" 1022 "Profile Vaue at Offset" 1023 "Invalid" ;
VAL_ 1207 PROSHORT_V2_ProfileType 0 "Invalid" 1 "Curvature" 16 "Alert Information Section" 17 "Alert Information Section 2" 18 "Reserved for system specific types" 19 "Reserved for system specific types" 20 "Reserved for system specific types" 21 "Reserved for system specific types" 22 "Reserved for system specific types" 23 "Reserved for system specific types" 24 "Reserved for system specific types" 25 "Reserved for system specific types" 26 "Reserved for system specific types" 27 "Reserved for system specific types" 28 "Reserved for system specific types" 29 "Reserved for system specific types" 30 "Reserved for system specific types" 31 "Reserved for system specific types" 2 "Route Number types" 3 "Slope(step)" 4 "Slope(Linear)" 5 "Road Accessibility" 6 "Road condition" 7 "Variable Speed Sign Position" 8 "Heading Change" 9 "Reserved for standard type" 10 "Reserved for standard type" 11 "Reserved for standard type" 12 "Reserved for standard type" 13 "Reserved for standard type" 14 "Reserved for standard type" 15 "Reserved for standard type" ;
